VERSION ""

NS_ :

BS_:

BU_: BDCF THU FP IP RRS PLG BDCR FIS EPS ARHUD ETC EMS EPBI LAS WLCM ESCL HU APA ACC LCDAL LCDAR BMT AMP SRS TCU ATB AWD ESL ACM ECM PCU BMS IBCU OTA

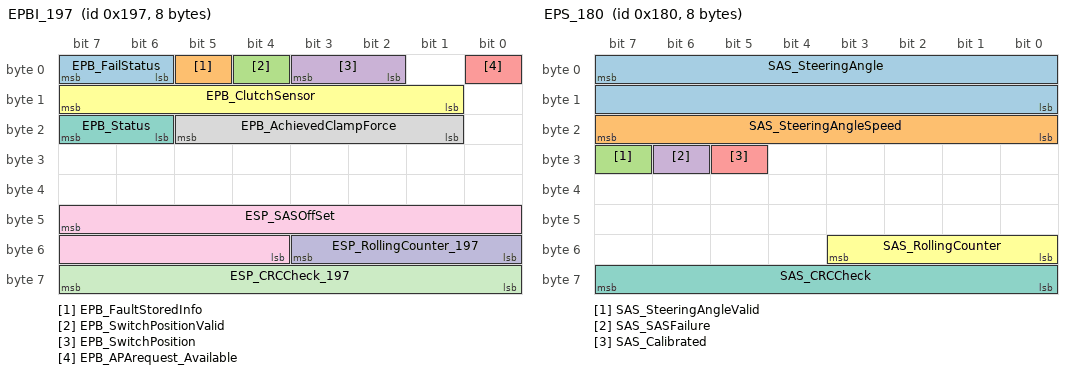
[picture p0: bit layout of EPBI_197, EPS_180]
BO_ 407 EPBI_197: 8 EPBI
SG_ EPB_FailStatus : 7|2@0+ (1,0) [0|3] "" BDCF
SG_ EPB_FaultStoredInfo : 5|1@0+ (1,0) [0|1] "" Vector__XXX
SG_ EPB_SwitchPositionValid : 4|1@0+ (1,0) [0|1] "" Vector__XXX
SG_ EPB_SwitchPosition : 3|2@0+ (1,0) [0|3] "" Vector__XXX
SG_ EPB_APArequest_Available : 0|1@0+ (1,0) [0|1] "" Vector__XXX
SG_ EPB_ClutchSensor : 15|7@0+ (1,0) [0|100] "%" Vector__XXX
SG_ EPB_Status : 23|2@0+ (1,0) [0|3] "" RRS
SG_ EPB_AchievedClampForce : 21|5@0+ (1,0) [0|31] "KN" Vector__XXX
SG_ ESP_SASOffSet : 47|12@0+ (0.1,-201) [-201|201] "degree" Vector__XXX
SG_ ESP_RollingCounter_197 : 51|4@0+ (1,0) [0|15] "" Vector__XXX
SG_ ESP_CRCCheck_197 : 63|8@0+ (1,0) [0|255] "" Vector__XXX

BO_ 391 EPBI_187: 8 EPBI
SG_ ESP_ABSActiveStatus : 7|1@0+ (1,0) [0|1] "" BDCF
SG_ ESP_GearHoldRequest : 6|1@0+ (1,0) [0|1] "" Vector__XXX
SG_ ESP_GearHoldRequestValid : 5|1@0+ (1,0) [0|1] "" Vector__XXX
SG_ ESP_TCSFailStatus : 4|1@0+ (1,0) [0|1] "" THU,IP
SG_ ESP_ABSFailStatus : 3|1@0+ (1,0) [0|1] "" THU,IP
SG_ ESP_EBDFailStatus : 2|1@0+ (1,0) [0|1] "" THU,IP
SG_ ESP_ESPFunctionStatus : 1|1@0+ (1,0) [0|1] "" THU,IP
SG_ ESP_ESPActiveStatus : 0|1@0+ (1,0) [0|1] "" THU,IP
SG_ ESP_EngTorqDecFast : 15|8@0+ (0.392,0) [0|99.568] "%" Vector__XXX
SG_ ESP_EngTorqDecSlow : 23|8@0+ (0.392,0) [0|99.568] "%" Vector__XXX
SG_ ESP_EngTorqInc : 31|8@0+ (0.392,0) [0|99.568] "%" Vector__XXX
SG_ ESP_EngTorqDecActive : 39|1@0+ (1,0) [0|1] "" Vector__XXX
SG_ ESP_EngTorqIncActive : 38|1@0+ (1,0) [0|1] "" Vector__XXX
SG_ ESP_VehicleSpeedValid : 37|1@0+ (1,0) [0|1] "" THU,IP,FIS,ESCL,RRS,PLG,BDCR
SG_ ESP_VehicleSpeed : 36|13@0+ (0.05625,0) [0|360] "km/h" THU,IP,FIS,ESCL,RRS,PLG,BDCR
SG_ ESP_ADBF_Active : 52|1@0+ (1,0) [0|1] "" Vector__XXX
SG_ ESP_RollingCounter_187 : 51|4@0+ (1,0) [0|15] "" Vector__XXX
SG_ ESP_CRCCheck_187 : 63|8@0+ (1,0) [0|255] "" Vector__XXX

BO_ 384 EPS_180: 8 EPS
SG_ SAS_SteeringAngle : 7|16@0+ (0.1,0) [-780|780] "degree" BDCF,THU,IP,FIS
SG_ SAS_SteeringAngleSpeed : 23|8@0+ (4,0) [0|1016] "deg/s" THU
SG_ SAS_SteeringAngleValid : 31|1@0+ (1,0) [0|1] "" THU,IP,FIS
SG_ SAS_SASFailure : 30|1@0+ (1,0) [0|1] "" Vector__XXX
SG_ SAS_Calibrated : 29|1@0+ (1,0) [0|1] "" Vector__XXX
SG_ SAS_RollingCounter : 51|4@0+ (1,0) [0|15] "" FIS
SG_ SAS_CRCCheck : 63|8@0+ (1,0) [0|255] "" FIS

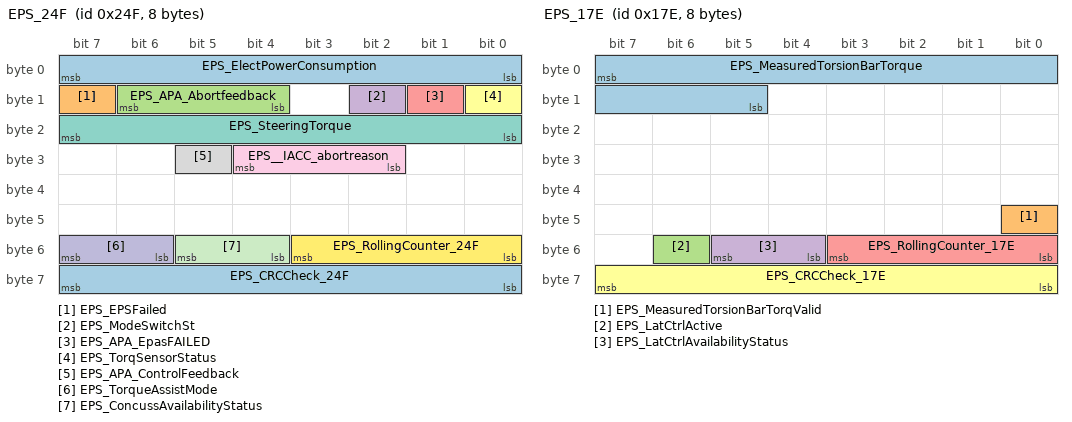
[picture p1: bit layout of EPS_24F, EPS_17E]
BO_ 591 EPS_24F: 8 EPS
 SG_ EPS_ElectPowerConsumption : 7|8@0+ (0.5,0) [0|127] "A" BDCF
 SG_ EPS_EPSFailed : 15|1@0+ (1,0) [0|1] "" THU,IP
 SG_ EPS_APA_Abortfeedback : 14|3@0+ (1,0) [0|7] "" Vector__XXX
 SG_ EPS_ModeSwitchSt : 10|1@0+ (1,0) [0|1] "" Vector__XXX
 SG_ EPS_APA_EpasFAILED : 9|1@0+ (1,0) [0|1] "" Vector__XXX
 SG_ EPS_TorqSensorStatus : 8|1@0+ (1,0) [0|1] "" Vector__XXX
 SG_ EPS_SteeringTorque : 23|8@0+ (0.1794,-22.78) [-22.78|22.78] "Nm" Vector__XXX
 SG_ EPS_APA_ControlFeedback : 29|1@0+ (1,0) [0|1] "" Vector__XXX
 SG_ EPS__IACC_abortreason : 28|3@0+ (1,0) [0|7] "" Vector__XXX
 SG_ EPS_TorqueAssistMode : 55|2@0+ (1,0) [0|3] "" THU,HU
 SG_ EPS_ConcussAvailabilityStatus : 53|2@0+ (1,0) [0|3] "" Vector__XXX
 SG_ EPS_RollingCounter_24F : 51|4@0+ (1,0) [0|15] "" Vector__XXX
 SG_ EPS_CRCCheck_24F : 63|8@0+ (1,0) [0|255] "" Vector__XXX

BO_ 382 EPS_17E: 8 EPS
 SG_ EPS_MeasuredTorsionBarTorque : 7|11@0+ (0.01,-10.23) [-10.23|10.23] "Nm" BDCF,THU
 SG_ EPS_MeasuredTorsionBarTorqValid : 40|1@0+ (1,0) [0|1] "" THU
 SG_ EPS_LatCtrlActive : 54|1@0+ (1,0) [0|1] "" Vector__XXX
 SG_ EPS_LatCtrlAvailabilityStatus : 53|2@0+ (1,0) [0|3] "" Vector__XXX
 SG_ EPS_RollingCounter_17E : 51|4@0+ (1,0) [0|15] "" Vector__XXX
 SG_ EPS_CRCCheck_17E : 63|8@0+ (1,0) [0|255] "" Vector__XXX

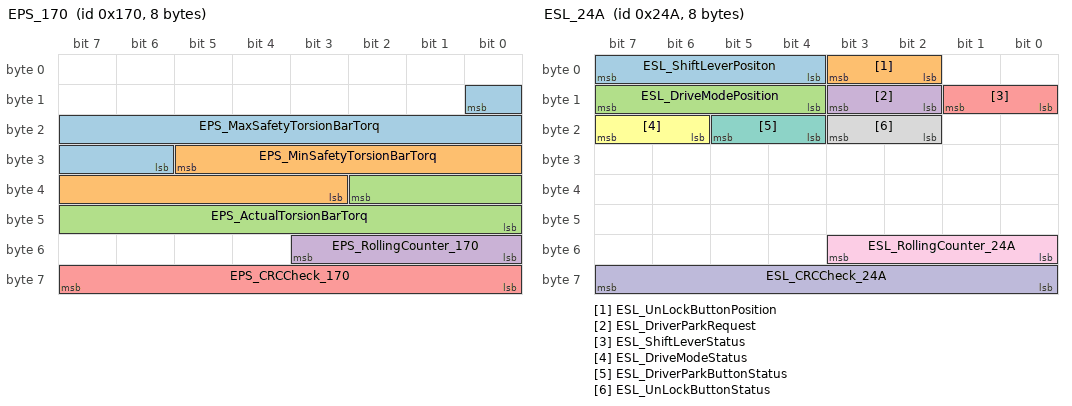
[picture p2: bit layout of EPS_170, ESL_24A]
BO_ 368 EPS_170: 8 EPS
 SG_ EPS_MaxSafetyTorsionBarTorq : 8|11@0+ (0.02,-20.48) [-20.48|20.46] "Nm" BDCF
 SG_ EPS_MinSafetyTorsionBarTorq : 29|11@0+ (0.02,-20.48) [-20.48|20.46] "Nm" Vector__XXX
 SG_ EPS_ActualTorsionBarTorq : 34|11@0+ (0.02,-20.48) [-20.48|20.46] "Nm" Vector__XXX
 SG_ EPS_RollingCounter_170 : 51|4@0+ (1,0) [0|15] "" Vector__XXX
 SG_ EPS_CRCCheck_170 : 63|8@0+ (1,0) [0|255] "" Vector__XXX

BO_ 586 ESL_24A: 8 ESL
 SG_ ESL_ShiftLeverPositon : 7|4@0+ (1,0) [0|15] "" BDCF
 SG_ ESL_UnLockButtonPosition : 3|2@0+ (1,0) [0|3] "" Vector__XXX
 SG_ ESL_DriveModePosition : 15|4@0+ (1,0) [0|15] "" Vector__XXX
 SG_ ESL_DriverParkRequest : 11|2@0+ (1,0) [0|3] "" Vector__XXX
 SG_ ESL_ShiftLeverStatus : 9|2@0+ (1,0) [0|3] "" Vector__XXX
 SG_ ESL_DriveModeStatus : 23|2@0+ (1,0) [0|3] "" Vector__XXX
 SG_ ESL_DriverParkButtonStatus : 21|2@0+ (1,0) [0|3] "" Vector__XXX
 SG_ ESL_UnLockButtonStatus : 19|2@0+ (1,0) [0|3] "" Vector__XXX
 SG_ ESL_RollingCounter_24A : 51|4@0+ (1,0) [0|15] "" Vector__XXX
 SG_ ESL_CRCCheck_24A : 63|8@0+ (1,0) [0|255] "" Vector__XXX

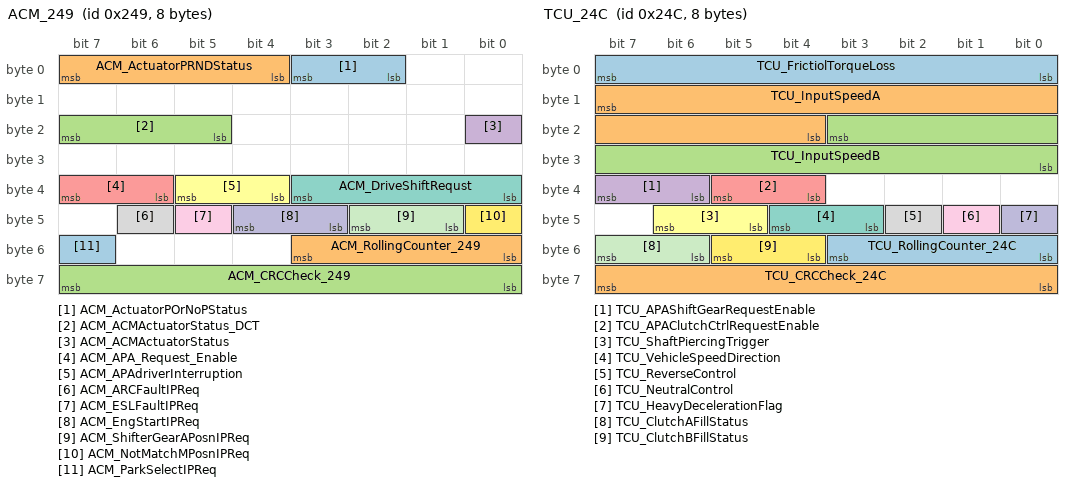
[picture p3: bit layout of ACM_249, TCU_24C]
BO_ 585 ACM_249: 8 ACM
 SG_ ACM_ActuatorPOrNoPStatus : 3|2@0+ (1,0) [0|3] "" BDCF
 SG_ ACM_ActuatorPRNDStatus : 7|4@0+ (1,0) [0|15] "" Vector__XXX
 SG_ ACM_ACMActuatorStatus_DCT : 23|3@0+ (1,0) [0|7] "" Vector__XXX
 SG_ ACM_ACMActuatorStatus : 16|1@0+ (1,0) [0|1] "" Vector__XXX
 SG_ ACM_APA_Request_Enable : 39|2@0+ (1,0) [0|3] "" Vector__XXX
 SG_ ACM_APAdriverInterruption : 37|2@0+ (1,0) [0|3] "" Vector__XXX
 SG_ ACM_DriveShiftRequst : 35|4@0+ (1,0) [0|15] "" Vector__XXX
 SG_ ACM_ARCFaultIPReq : 46|1@0+ (1,0) [0|1] "" Vector__XXX
 SG_ ACM_ESLFaultIPReq : 45|1@0+ (1,0) [0|1] "" Vector__XXX
 SG_ ACM_EngStartIPReq : 44|2@0+ (1,0) [0|3] "" Vector__XXX
 SG_ ACM_ShifterGearAPosnIPReq : 42|2@0+ (1,0) [0|3] "" Vector__XXX
 SG_ ACM_NotMatchMPosnIPReq : 40|1@0+ (1,0) [0|1] "" Vector__XXX
 SG_ ACM_ParkSelectIPReq : 55|1@0+ (1,0) [0|1] "" Vector__XXX
 SG_ ACM_RollingCounter_249 : 51|4@0+ (1,0) [0|15] "" Vector__XXX
 SG_ ACM_CRCCheck_249 : 63|8@0+ (1,0) [0|255] "" Vector__XXX

BO_ 509 ECM_1FD: 8 ECM
 SG_ TCU_CrankingAuthEnable : 5|2@0+ (1,0) [0|3] "" BDCF

BO_ 824 TCU_338: 8 TCU
 SG_ TCU_CompressorDisableReq : 7|1@0+ (1,0) [0|1] "" BDCF
 SG_ TCU_FailureLamp : 6|1@0+ (1,0) [0|1] "" THU,IP
 SG_ TCU_ReqTranTempWarning : 5|2@0+ (1,0) [0|3] "" THU,IP
 SG_ TCU_BrakeAssistRequest : 3|1@0+ (1,0) [0|1] "" Vector__XXX
 SG_ TCU_BrakeAssistRequestValid : 2|1@0+ (1,0) [0|1] "" Vector__XXX
 SG_ TCU_FanRequest : 1|2@0+ (1,0) [0|3] "" Vector__XXX
 SG_ TCU_ShiftMapID : 15|4@0+ (1,0) [0|15] "" Vector__XXX
 SG_ TCU_LinePressureFailureStatus : 11|1@0+ (1,0) [0|1] "" THU,IP
 SG_ TCU_ClearDiagnosticInfo : 9|2@0+ (1,0) [0|3] "" Vector__XXX
 SG_ TCU_TransFluidTemp : 23|8@0+ (1,-40) [-40|214] "degreeC" Vector__XXX
 SG_ TCU_SlopeRatio : 31|8@0+ (0.2,-25) [-25|25] "%" THU
 SG_ TCU_GearForDisplay : 39|4@0+ (1,0) [0|15] "" THU,IP,RRS
 SG_ TCU_GearIndication : 35|1@0+ (1,0) [0|1] "" Vector__XXX
 SG_ TCU_BuzzerReq : 34|3@0+ (1,0) [0|7] "" Vector__XXX
 SG_ TCU_EngStartIPReq : 47|2@0+ (1,0) [0|3] "" IP
 SG_ TCU_ParkRelAPosnIPReq : 45|2@0+ (1,0) [0|3] "" IP
 SG_ TCU_ParkRelMPosnIPReq : 43|1@0+ (1,0) [0|1] "" IP
 SG_ TCU_ParkSelectIPReq : 42|1@0+ (1,0) [0|1] "" IP
 SG_ TCU_ESLFaultIPReq : 41|1@0+ (1,0) [0|1] "" IP
 SG_ TCU_ARCFaultIPReq : 40|1@0+ (1,0) [0|1] "" IP
 SG_ TCU_DriveMode : 55|4@0+ (1,0) [0|15] "" Vector__XXX
 SG_ TCU_RollingCounter_338 : 51|4@0+ (1,0) [0|15] "" Vector__XXX
 SG_ TCU_CRCCheck_338 : 63|8@0+ (1,0) [0|255] "" Vector__XXX

BO_ 588 TCU_24C: 8 TCU
 SG_ TCU_FrictiolTorqueLoss : 7|8@0+ (0.1,0) [0|25] "%" BDCF
 SG_ TCU_InputSpeedA : 15|12@0+ (2.5,0) [0|10235] "rpm" Vector__XXX
 SG_ TCU_InputSpeedB : 19|12@0+ (2.5,0) [0|10235] "rpm" Vector__XXX
 SG_ TCU_APAShiftGearRequestEnable : 39|2@0+ (1,0) [0|3] "" Vector__XXX
 SG_ TCU_APAClutchCtrlRequestEnable : 37|2@0+ (1,0) [0|3] "" Vector__XXX
 SG_ TCU_ShaftPiercingTrigger : 46|2@0+ (1,0) [0|3] "" Vector__XXX
 SG_ TCU_VehicleSpeedDirection : 44|2@0+ (1,0) [0|3] "" Vector__XXX
 SG_ TCU_ReverseControl : 42|1@0+ (1,0) [0|1] "" RRS
 SG_ TCU_NeutralControl : 41|1@0+ (1,0) [0|1] "" Vector__XXX
 SG_ TCU_HeavyDecelerationFlag : 40|1@0+ (1,0) [0|1] "" Vector__XXX
 SG_ TCU_ClutchAFillStatus : 55|2@0+ (1,0) [0|3] "" Vector__XXX
 SG_ TCU_ClutchBFillStatus : 53|2@0+ (1,0) [0|3] "" Vector__XXX
 SG_ TCU_RollingCounter_24C : 51|4@0+ (1,0) [0|15] "" Vector__XXX
 SG_ TCU_CRCCheck_24C : 63|8@0+ (1,0) [0|255] "" Vector__XXX

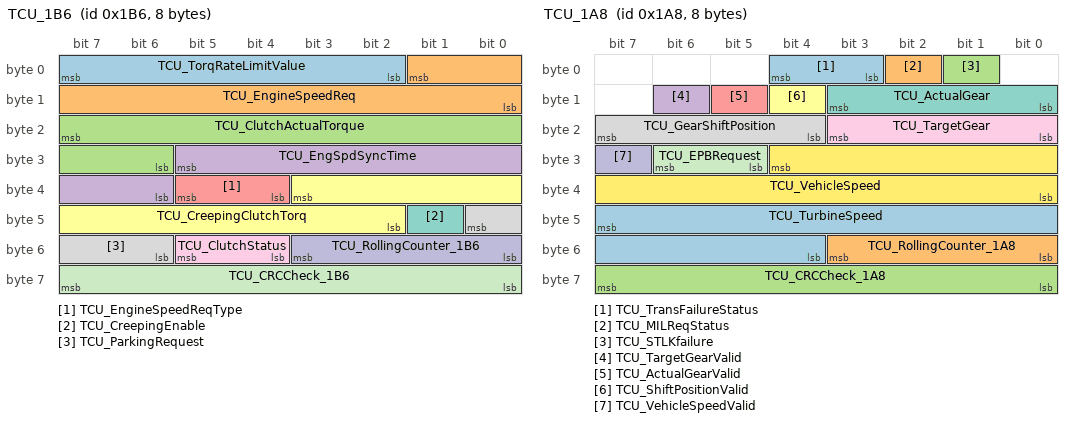
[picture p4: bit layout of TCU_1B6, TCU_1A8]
BO_ 438 TCU_1B6: 8 TCU
 SG_ TCU_TorqRateLimitValue : 7|6@0+ (10,0) [0|630] "Nm/s" BDCF
 SG_ TCU_EngineSpeedReq : 1|10@0+ (10,0) [0|10200] "Rpm" Vector__XXX
 SG_ TCU_ClutchActualTorque : 23|10@0+ (0.1,0) [0|100] "%" Vector__XXX
 SG_ TCU_EngSpdSyncTime : 29|8@0+ (10,0) [0|2550] "ms" Vector__XXX
 SG_ TCU_EngineSpeedReqType : 37|2@0+ (1,0) [0|3] "" Vector__XXX
 SG_ TCU_CreepingClutchTorq : 35|10@0+ (0.1,0) [0|100] "%" Vector__XXX
 SG_ TCU_CreepingEnable : 41|1@0+ (1,0) [0|1] "" Vector__XXX
 SG_ TCU_ParkingRequest : 40|3@0+ (1,0) [0|7] "" Vector__XXX
 SG_ TCU_ClutchStatus : 53|2@0+ (1,0) [0|3] "" Vector__XXX
 SG_ TCU_RollingCounter_1B6 : 51|4@0+ (1,0) [0|15] "" Vector__XXX
 SG_ TCU_CRCCheck_1B6 : 63|8@0+ (1,0) [0|255] "" Vector__XXX

BO_ 424 TCU_1A8: 8 TCU
SG_ TCU_TransFailureStatus : 4|2@0+ (1,0) [0|3] "" BDCF,THU,IP
SG_ TCU_MILReqStatus : 2|1@0+ (1,0) [0|1] "" Vector__XXX
SG_ TCU_STLKfailure : 1|1@0+ (1,0) [0|1] "" Vector__XXX
SG_ TCU_TargetGearValid : 14|1@0+ (1,0) [0|1] "" THU,IP
SG_ TCU_ActualGearValid : 13|1@0+ (1,0) [0|1] "" THU,IP
SG_ TCU_ShiftPositionValid : 12|1@0+ (1,0) [0|1] "" THU,IP,FIS,PLG
SG_ TCU_ActualGear : 11|4@0+ (1,0) [0|15] "" THU,IP,FIS
SG_ TCU_GearShiftPosition : 23|4@0+ (1,0) [0|15] "" THU,IP,FIS,PLG,BDCR
SG_ TCU_TargetGear : 19|4@0+ (1,0) [0|15] "" THU,IP
SG_ TCU_VehicleSpeedValid : 31|1@0+ (1,0) [0|1] "" Vector__XXX
SG_ TCU_EPBRequest : 30|2@0+ (1,0) [0|3] "" Vector__XXX
SG_ TCU_VehicleSpeed : 28|13@0+ (0.05625,0) [0|360] "km/h" Vector__XXX
SG_ TCU_TurbineSpeed : 47|12@0+ (2,0) [0|8190] "rpm" Vector__XXX
SG_ TCU_RollingCounter_1A8 : 51|4@0+ (1,0) [0|15] "" THU,IP
SG_ TCU_CRCCheck_1A8 : 63|8@0+ (1,0) [0|255] "" THU,IP

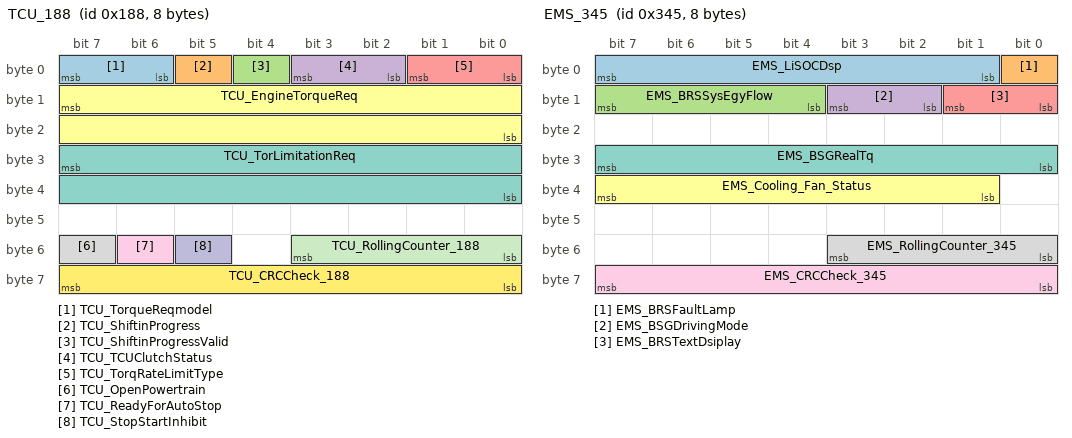
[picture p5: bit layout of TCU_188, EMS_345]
BO_ 392 TCU_188: 8 TCU
 SG_ TCU_TorqueReqmodel : 7|2@0+ (1,0) [0|3] "" BDCF
 SG_ TCU_ShiftinProgress : 5|1@0+ (1,0) [0|1] "" Vector__XXX
 SG_ TCU_ShiftinProgressValid : 4|1@0+ (1,0) [0|1] "" Vector__XXX
 SG_ TCU_TCUClutchStatus : 3|2@0+ (1,0) [0|3] "" Vector__XXX
 SG_ TCU_TorqRateLimitType : 1|2@0+ (1,0) [0|3] "" Vector__XXX
 SG_ TCU_EngineTorqueReq : 15|16@0+ (0.001526,0) [0|99.99878] "%" Vector__XXX
 SG_ TCU_TorLimitationReq : 31|16@0+ (0.001526,0) [0|99.99878] "%" Vector__XXX
 SG_ TCU_OpenPowertrain : 55|1@0+ (1,0) [0|1] "" Vector__XXX
 SG_ TCU_ReadyForAutoStop : 54|1@0+ (1,0) [0|1] "" Vector__XXX
 SG_ TCU_StopStartInhibit : 53|1@0+ (1,0) [0|1] "" Vector__XXX
 SG_ TCU_RollingCounter_188 : 51|4@0+ (1,0) [0|15] "" Vector__XXX
 SG_ TCU_CRCCheck_188 : 63|8@0+ (1,0) [0|255] "" Vector__XXX

BO_ 853 EMS_355: 8 EMS
SG_ EMS_CruiseActiveIndicate : 0|1@0+ (1,0) [0|1] "" BDCF,THU,IP
SG_ EMS_SSMWarningLampCtrol : 1|1@0+ (1,0) [0|1] "" THU,IP
SG_ EMS_CruiseUnavailDisplay : 2|1@0+ (1,0) [0|1] "" THU,IP
SG_ EMS_IdleStopStatus : 3|1@0+ (1,0) [0|1] "" THU,IP
SG_ EMS_CruiseIndicate : 4|1@0+ (1,0) [0|1] "" THU,IP
SG_ EMS_MIL : 6|2@0+ (1,0) [0|3] "" THU,IP
SG_ EMS_SVS : 7|1@0+ (1,0) [0|1] "" Vector__XXX
SG_ EMS_StartPrompt : 9|2@0+ (1,0) [0|3] "" THU,IP
SG_ EMS_CruiseDistance : 10|1@0+ (1,0) [0|1] "" THU,IP
SG_ EMS_CruiseSwitchSET : 11|1@0+ (1,0) [0|1] "" THU,IP
SG_ EMS_CruiseSwitchCANCEL : 12|1@0+ (1,0) [0|1] "" THU,IP
SG_ EMS_CruiseSwitchResume : 13|1@0+ (1,0) [0|1] "" THU,IP
SG_ EMS_CruiseSwitchOnOff : 14|1@0+ (1,0) [0|1] "" THU,IP
SG_ EMS_PFCCCondition : 15|1@0+ (1,0) [0|1] "" Vector__XXX
SG_ EMS_TankDoorSts : 16|1@0+ (1,0) [0|1] "" THU,IP
SG_ EMS_GPF_State : 19|3@0+ (1,0) [0|7] "" THU,IP
SG_ EMS_RemindShiftGear : 21|2@0+ (1,0) [0|3] "" THU,IP
SG_ EMS_ClearDiagnosticInfo : 23|2@0+ (1,0) [0|3] "" Vector__XXX
 SG_ EMS_AgsPosition : 26|2@0+ (1,0) [0|3] "" IP
SG_ EMS_AgsErrorStateDisplay : 27|1@0+ (1,0) [0|1] "" IP
SG_ EMS_CruiseControlStatus_355 : 29|2@0+ (1,0) [0|3] "" THU,IP
SG_ EMS_DriveMode : 31|2@0+ (1,0) [0|3] "" Vector__XXX
SG_ EMS_FuelConsumption : 39|8@0+ (0.015,0) [0|3.81] "ml" THU,IP
SG_ EMS_TargetCruiseSpeed : 47|8@0+ (1,0) [0|254] "Km/h" THU,IP
SG_ EMS_RollingCounter_355 : 51|4@0+ (1,0) [0|15] "" Vector__XXX
SG_ EMS_EngineType : 55|4@0+ (1,0) [0|15] "" Vector__XXX
SG_ EMS_CRCCheck_355 : 63|8@0+ (1,0) [0|255] "" Vector__XXX

BO_ 837 EMS_345: 8 EMS
SG_ EMS_LiSOCDsp : 7|7@0+ (1,0) [0|100] "%" BDCF
SG_ EMS_BRSFaultLamp : 0|1@0+ (1,0) [0|1] "" Vector__XXX
SG_ EMS_BRSSysEgyFlow : 15|4@0+ (1,0) [0|15] "" Vector__XXX
SG_ EMS_BSGDrivingMode : 11|2@0+ (1,0) [0|3] "" Vector__XXX
SG_ EMS_BRSTextDsiplay : 9|2@0+ (1,0) [0|3] "" Vector__XXX
SG_ EMS_Cooling_Fan_Status : 39|7@0+ (1,0) [0|111] "%" Vector__XXX
SG_ EMS_BSGRealTq : 31|8@0+ (0.5,-63) [-63|63] "" Vector__XXX
SG_ EMS_RollingCounter_345 : 51|4@0+ (1,0) [0|15] "" Vector__XXX
SG_ EMS_CRCCheck_345 : 63|8@0+ (1,0) [0|255] "" Vector__XXX

BO_ 776 EMS_308: 8 EMS
SG_ EMS_FuelCapLeakDisplay : 7|1@0+ (1,0) [0|1] "" THU,IP
SG_ EMS_OilPressureSts : 6|1@0+ (1,0) [0|1] "" THU,IP
SG_ EMS_ChrageLightState : 5|1@0+ (1,0) [0|1] "" THU,IP
SG_ EMS_EEMErrorFlag : 4|1@0+ (1,0) [0|1] "" Vector__XXX
SG_ EMS_EEM_state : 3|3@0+ (1,0) [0|7] "" Vector__XXX
SG_ EMS_IntakeAirTempSensorError : 0|1@0+ (1,0) [0|1] "" THU,HU
SG_ EMS_RemindGear : 15|3@0+ (1,0) [0|7] "" THU,IP
SG_ EMS_STTUnavailDisplay : 12|3@0+ (1,0) [0|7] "" IP
SG_ EMS_Neutralgear : 9|2@0+ (1,0) [0|1] "" Vector__XXX
SG_ EMS_EngineIntakeAirTemp : 23|8@0+ (0.75,-40) [-40|150.5] "degree_C" Vector__XXX
SG_ EMS_ASLTargetSpeed : 31|8@0+ (1,0) [0|255] "km/h" Vector__XXX
SG_ EMS_ExhaustValStatus : 34|2@0+ (1,0) [0|3] "" BDCF,THU
SG_ EMS_ASLFaultsWarning : 55|1@0+ (1,0) [0|1] "" Vector__XXX
SG_ EMS_ASLExceedTarSpdIndi : 54|1@0+ (1,0) [0|1] "" Vector__XXX
SG_ EMS_ASLControlStatus : 53|2@0+ (1,0) [0|3] "" Vector__XXX
SG_ EMS_RollingCounter_308 : 51|4@0+ (1,0) [0|15] "" Vector__XXX
SG_ EMS_CRCCheck_308 : 63|8@0+ (1,0) [0|255] "" Vector__XXX

BO_ 726 EMS_2D6: 8 EMS
SG_ EMS_CatalystWarmUp : 7|1@0+ (1,0) [0|1] "" BDCF
SG_ EMS_WarmUpCycle : 6|1@0+ (1,0) [0|1] "" Vector__XXX
SG_ EMS_DrivingCycle : 5|1@0+ (1,0) [0|1] "" Vector__XXX
SG_ EMS_EngineLimpHome : 4|1@0+ (1,0) [0|1] "" Vector__XXX
SG_ EMS_ImmoFeedback : 3|2@0+ (1,0) [0|3] "" Vector__XXX
SG_ EMS_ImmoConfiguration : 1|1@0+ (1,0) [0|1] "" Vector__XXX
SG_ EMS_CoolanTemperatureError : 15|1@0+ (1,0) [0|1] "" THU,IP
SG_ EMS_BatteryVoltageError : 14|1@0+ (1,0) [0|1] "" Vector__XXX
SG_ EMS_General_Denominator_Status : 12|1@0+ (1,0) [0|1] "" Vector__XXX
SG_ EMS_GeneralDenomStasVD : 11|1@0+ (1,0) [0|1] "" Vector__XXX
SG_ EMS_Ignition_Cycles_Counter : 10|1@0+ (1,0) [0|1] "" Vector__XXX
SG_ EMS_EngineStartupEnd : 9|1@0+ (1,0) [0|1] "" Vector__XXX
SG_ EMS_EngineCoolanTemperature : 23|8@0+ (0.75,-48) [-48|142.5] "degreeC" THU,IP
SG_ EMS_BatteryVoltage : 31|8@0+ (0.1,0) [0|25.4] "V" Vector__XXX
SG_ EMS_IdleReferenceSpeed : 39|8@0+ (10,0) [0|2540] "rpm" Vector__XXX
SG_ EMS_AltitudeFactor : 47|8@0+ (0.01575,0) [0|4] "" Vector__XXX
SG_ EMS_RollingCounter_2D6 : 51|4@0+ (1,0) [0|15] "" Vector__XXX
SG_ EMS_CRCCheck_2D6 : 63|8@0+ (1,0) [0|255] "" Vector__XXX

BO_ 618 EMS_26A: 8 EMS
SG_ EMS_EVPActive : 5|1@0+ (1,0) [0|1] "" BDCF
SG_ EMS_confirmation_in_sport_mode : 4|1@0+ (1,0) [0|1] "" Vector__XXX
SG_ EMS_AccReqPossible : 3|1@0+ (1,0) [0|1] "" Vector__XXX
SG_ EMS_QECACC : 2|2@0+ (1,0) [0|3] "" Vector__XXX
SG_ EMS_ECGPOvrd : 0|1@0+ (1,0) [0|1] "" Vector__XXX
SG_ EMS_APAAccPedShieldStatus : 24|1@0+ (1,0) [0|1] "" Vector__XXX
SG_ EMS_DriveModeSts : 28|4@0+ (1,0) [0|15] "" IP
SG_ EMS_EngTorqQualityFlag : 39|2@0+ (1,0) [0|3] "" Vector__XXX
SG_ EMS_CompressorWoE : 37|1@0+ (1,0) [0|1] "" Vector__XXX
SG_ EMS_KickDown : 36|1@0+ (1,0) [0|1] "" Vector__XXX
SG_ EMS_CompressorStatus : 35|1@0+ (1,0) [0|1] "" Vector__XXX
SG_ EMS_EngineStatusWithSTT : 34|3@0+ (1,0) [0|7] "" THU,IP
SG_ EMS_VacuumPressure : 47|10@0+ (1.1056,-1080) [-1080|50] "mbar" Vector__XXX
SG_ EMS_ConditionIdle : 53|1@0+ (1,0) [0|1] "" Vector__XXX
SG_ EMS_VacuumPressureValid : 52|1@0+ (1,0) [0|1] "" Vector__XXX
SG_ EMS_RollingCounter_26A : 51|4@0+ (1,0) [0|15] "" IP
SG_ EMS_CRCCheck_26A : 63|8@0+ (1,0) [0|255] "" IP

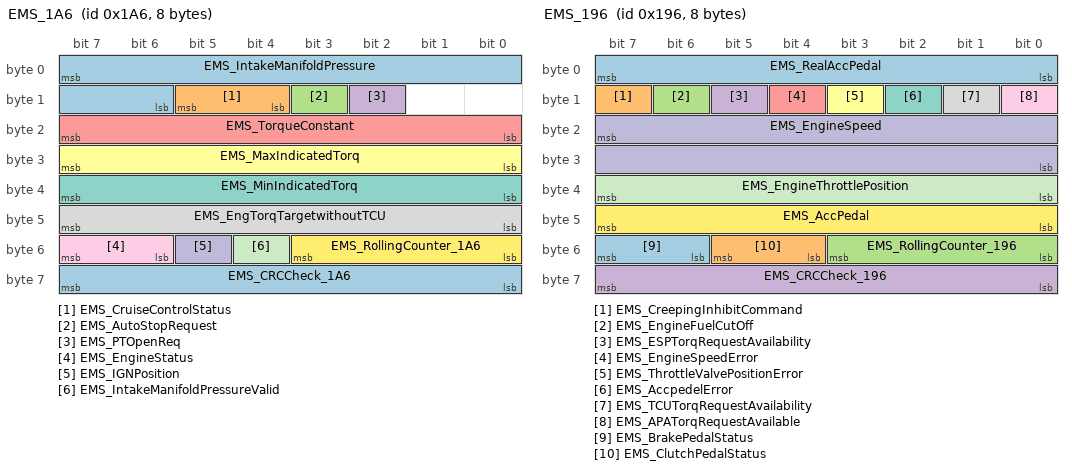
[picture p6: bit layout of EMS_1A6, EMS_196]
BO_ 422 EMS_1A6: 8 EMS
SG_ EMS_IntakeManifoldPressure : 7|10@0+ (4,100) [100|4188] "mbar" BDCF,THU
SG_ EMS_CruiseControlStatus : 13|2@0+ (1,0) [0|3] "" THU,IP
SG_ EMS_AutoStopRequest : 11|1@0+ (1,0) [0|1] "" Vector__XXX
SG_ EMS_PTOpenReq : 10|1@0+ (1,0) [0|1] "" Vector__XXX
SG_ EMS_TorqueConstant : 23|8@0+ (10,0) [0|2540] "NM" Vector__XXX
SG_ EMS_MaxIndicatedTorq : 31|8@0+ (0.392,0) [0|99.568] "%" Vector__XXX
SG_ EMS_MinIndicatedTorq : 39|8@0+ (0.392,0) [0|99.568] "%" Vector__XXX
SG_ EMS_EngTorqTargetwithoutTCU : 47|8@0+ (0.392,0) [0|99.568] "%" Vector__XXX
SG_ EMS_EngineStatus : 55|2@0+ (1,0) [0|3] "" THU,IP,FIS
SG_ EMS_IGNPosition : 53|1@0+ (1,0) [0|1] "" Vector__XXX
SG_ EMS_IntakeManifoldPressureValid : 52|1@0+ (1,0) [0|1] "" THU
SG_ EMS_RollingCounter_1A6 : 51|4@0+ (1,0) [0|15] "" Vector__XXX
SG_ EMS_CRCCheck_1A6 : 63|8@0+ (1,0) [0|255] "" Vector__XXX

BO_ 406 EMS_196: 8 EMS
SG_ EMS_RealAccPedal : 7|8@0+ (0.392,0) [0|99.568] "%" BDCF,THU
SG_ EMS_CreepingInhibitCommand : 15|1@0+ (1,0) [0|1] "" Vector__XXX
SG_ EMS_EngineFuelCutOff : 14|1@0+ (1,0) [0|1] "" IP
SG_ EMS_ESPTorqRequestAvailability : 13|1@0+ (1,0) [0|1] "" Vector__XXX
SG_ EMS_EngineSpeedError : 12|1@0+ (1,0) [0|1] "" THU,IP,FIS
SG_ EMS_ThrottleValvePositionError : 11|1@0+ (1,0) [0|1] "" THU,HU
SG_ EMS_AccpedelError : 10|1@0+ (1,0) [0|1] "" THU,HU
SG_ EMS_TCUTorqRequestAvailability : 9|1@0+ (1,0) [0|1] "" Vector__XXX
SG_ EMS_APATorqRequestAvailable : 8|1@0+ (1,0) [0|1] "" Vector__XXX
SG_ EMS_EngineSpeed : 23|16@0+ (0.25,0) [0|16383.5] "Rpm" THU,IP,FIS
SG_ EMS_EngineThrottlePosition : 39|8@0+ (0.392,0) [0|99.568] "%" Vector__XXX
SG_ EMS_AccPedal : 47|8@0+ (0.392,0) [0|99.568] "%" THU
SG_ EMS_BrakePedalStatus : 55|2@0+ (1,0) [0|3] "" THU,IP
SG_ EMS_ClutchPedalStatus : 53|2@0+ (1,0) [0|3] "" Vector__XXX
SG_ EMS_RollingCounter_196 : 51|4@0+ (1,0) [0|15] "" FIS
SG_ EMS_CRCCheck_196 : 63|8@0+ (1,0) [0|255] "" FIS

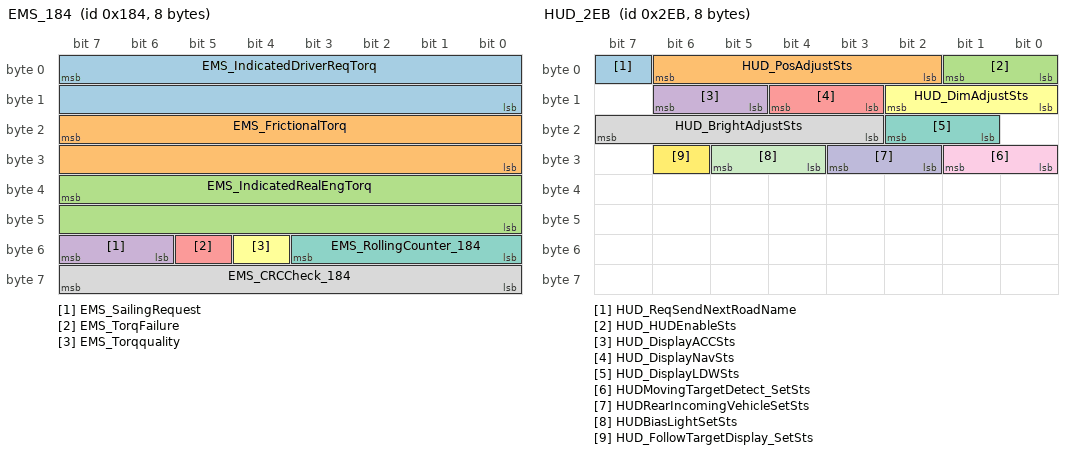
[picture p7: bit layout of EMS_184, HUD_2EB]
BO_ 388 EMS_184: 8 EMS
 SG_ EMS_IndicatedDriverReqTorq : 7|16@0+ (0.001526,0) [0|99.99878] "%" BDCF,THU,IP
 SG_ EMS_FrictionalTorq : 23|16@0+ (0.001526,0) [0|99.99878] "%" THU,IP
 SG_ EMS_IndicatedRealEngTorq : 39|16@0+ (0.001526,0) [0|99.99878] "%" Vector__XXX
 SG_ EMS_SailingRequest : 55|2@0+ (1,0) [0|3] "" Vector__XXX
 SG_ EMS_TorqFailure : 53|1@0+ (1,0) [0|1] "" Vector__XXX
 SG_ EMS_Torqquality : 52|1@0+ (1,0) [0|1] "" Vector__XXX
 SG_ EMS_RollingCounter_184 : 51|4@0+ (1,0) [0|15] "" Vector__XXX
 SG_ EMS_CRCCheck_184 : 63|8@0+ (1,0) [0|255] "" Vector__XXX

BO_ 747 HUD_2EB: 8 BDCF
 SG_ HUD_ReqSendNextRoadName : 7|1@0+ (1,0) [0|1] "" THU
 SG_ HUD_PosAdjustSts : 6|5@0+ (1,0) [0|31] "" THU
 SG_ HUD_HUDEnableSts : 1|2@0+ (1,0) [0|3] "" THU,IP
 SG_ HUD_DisplayACCSts : 14|2@0+ (1,0) [0|3] "" THU
 SG_ HUD_DisplayNavSts : 12|2@0+ (1,0) [0|3] "" THU
 SG_ HUD_DimAdjustSts : 10|3@0+ (1,0) [0|7] "" THU
 SG_ HUD_DisplayLDWSts : 18|2@0+ (1,0) [0|3] "" THU
 SG_ HUD_BrightAdjustSts : 23|5@0+ (1,0) [0|31] "" THU
 SG_ HUDMovingTargetDetect_SetSts : 25|2@0+ (1,0) [0|3] "" THU
 SG_ HUDRearIncomingVehicleSetSts : 27|2@0+ (1,0) [0|3] "" THU
 SG_ HUDBiasLightSetSts : 29|2@0+ (1,0) [0|3] "" THU
 SG_ HUD_FollowTargetDisplay_SetSts : 30|1@0+ (1,0) [0|1] "" THU

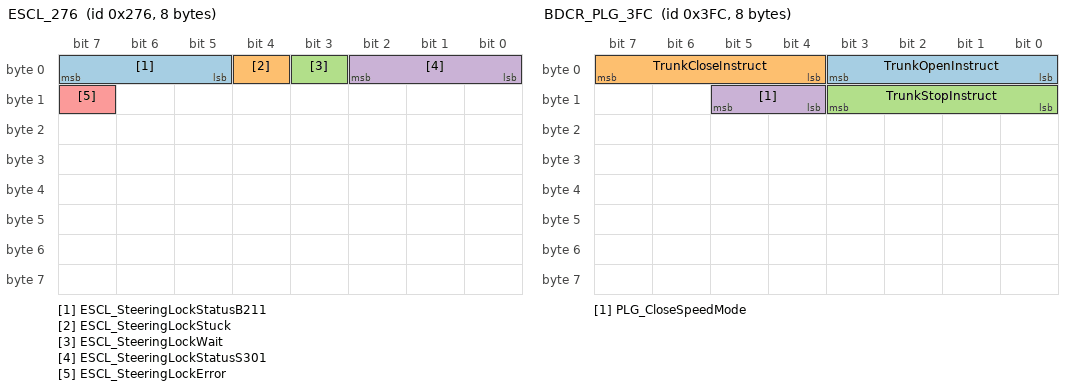
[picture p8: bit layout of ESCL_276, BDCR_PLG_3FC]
BO_ 630 ESCL_276: 8 ESCL
SG_ ESCL_SteeringLockStatusB211 : 7|3@0+ (1,0) [0|7] "" BDCF
SG_ ESCL_SteeringLockStuck : 4|1@0+ (1,0) [0|1] "" BDCF
SG_ ESCL_SteeringLockWait : 3|1@0+ (1,0) [0|1] "" BDCF
SG_ ESCL_SteeringLockStatusS301 : 2|3@0+ (1,0) [0|7] "" BDCF
SG_ ESCL_SteeringLockError : 15|1@0+ (1,0) [0|1] "" BDCF

BO_ 1020 BDCR_PLG_3FC: 8 BDCR
 SG_ TrunkOpenInstruct : 3|4@0+ (1,0) [0|15] ""  BDCF
 SG_ TrunkCloseInstruct : 7|4@0+ (1,0) [0|15] ""  BDCF
 SG_ TrunkStopInstruct : 11|4@0+ (1,0) [0|15] ""  BDCF
 SG_ PLG_CloseSpeedMode : 13|2@0+ (1,0) [0|3] ""  BDCF

BO_ 1022 BDCR_PLG_3FE: 8 BDCR
SG_ PLG_OpenHeightLearningStatus : 1|1@0+ (1,0) [0|1] "" BDCF
SG_ PLG_MovementStatus : 4|3@0+ (1,0) [0|7] "" BDCF,THU
SG_ PLG_LatchStatus : 7|3@0+ (1,0) [0|7] "" BDCF,THU
SG_ PLG_OpenHeightLearningResult : 0|1@0+ (1,0) [0|1] "" BDCF
SG_ PLG_GatePosition : 15|8@0+ (0.395,0) [0|100] "" BDCF,THU
SG_ PLG_InitializeStatus : 16|1@0+ (1,0) [0|1] "" BDCF,THU
SG_ PLG_InitializedResult : 17|1@0+ (1,0) [0|1] "" BDCF
SG_ PLG_ShutfaceSwitch : 18|1@0+ (1,0) [0|1] "" BDCF,THU
SG_ PLG_OpenCloseSwitch : 19|1@0+ (1,0) [0|1] "" BDCF,THU
SG_ PLG_PoleOverVoltage : 20|1@0+ (1,0) [0|1] "" BDCF
SG_ PLG_PoleUnderVoltage : 21|1@0+ (1,0) [0|1] "" BDCF
SG_ PLG_KickSensorStatus : 22|1@0+ (1,0) [0|1] "" BDCF
SG_ PLG_PawlSwitch : 23|1@0+ (1,0) [0|1] "" BDCF
SG_ PLG_PoleTimeoutStatus : 31|1@0+ (1,0) [0|1] "" BDCF
SG_ PLG_LockTimeoutStatus : 30|1@0+ (1,0) [0|1] "" BDCF
SG_ PLG_LockOverVoltage : 29|1@0+ (1,0) [0|1] "" BDCF
SG_ PLG_LockUnderVoltage : 28|1@0+ (1,0) [0|1] "" BDCF
SG_ PLG_ApsStatus : 27|1@0+ (1,0) [0|1] "" BDCF
SG_ PLG_PinchEventStatus : 26|1@0+ (1,0) [0|1] "" BDCF
SG_ PLG_ResetSwitch : 25|1@0+ (1,0) [0|1] "" BDCF
SG_ PLG_RatchetSwitch : 24|1@0+ (1,0) [0|1] "" BDCF
SG_ PLG_LatchMotorHeatProtectStatus : 39|1@0+ (1,0) [0|1] "" BDCF
SG_ PLG_LatchMotorStallStatus : 38|1@0+ (1,0) [0|1] "" BDCF
SG_ PLG_GateMotorHeatProtectStatus : 37|1@0+ (1,0) [0|1] "" BDCF
SG_ PLG_GateMotorStallStatus : 36|1@0+ (1,0) [0|1] "" BDCF
SG_ PLG_PinchPlayModeStatus : 35|1@0+ (1,0) [0|1] "" BDCF
SG_ PLG_InitializedFailReason : 34|3@0+ (1,0) [0|7] "" BDCF,THU
SG_ PLG_BuzzerStaus : 47|3@0+ (1,0) [0|3] "" BDCF,THU
SG_ PLG_OpenCloseSwitchError : 44|1@0+ (1,0) [0|1] "" BDCF
SG_ PLG_ShutfaceSwitchError : 43|1@0+ (1,0) [0|1] "" BDCF
SG_ PLG_PinchTriggerSignal : 42|1@0+ (1,0) [0|1] "" BDCF
SG_ PLG_Lock_RelayError : 41|1@0+ (1,0) [0|1] "" BDCF
SG_ PLG_Pole_HallError : 40|1@0+ (1,0) [0|1] "" BDCF
SG_ PLG_TrunkPositionFeedback : 55|8@0+ (0.395,0) [0|100] "" BDCF,THU
SG_ PLG_OpenHeightLearningFailReason : 58|3@0+ (1,0) [0|7] "" BDCF,THU
SG_ PLG_Pole_RelayError : 60|1@0+ (1,0) [0|1] "" BDCF
SG_ Sunroof_IntegrateSwitch : 63|3@0+ (1,0) [0|7] "" BDCF

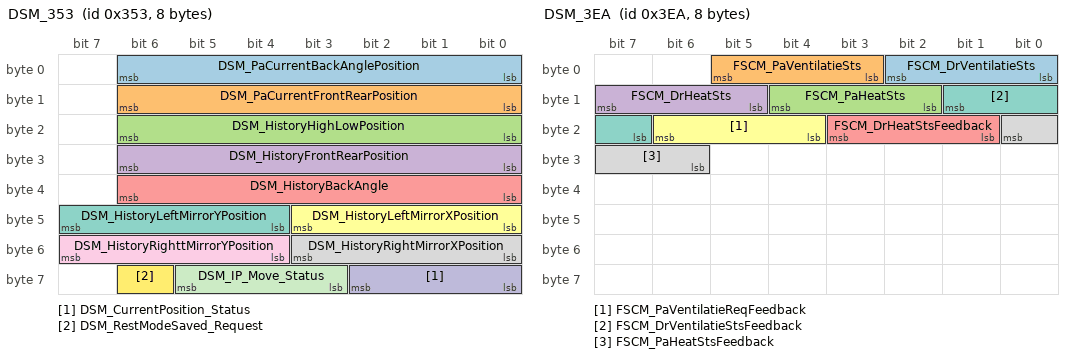
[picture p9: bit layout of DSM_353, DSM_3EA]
BO_ 851 DSM_353: 8 BDCF
SG_ DSM_PaCurrentBackAnglePosition : 6|7@0+ (1,0) [0|100] "%" THU,FIS
SG_ DSM_PaCurrentFrontRearPosition : 14|7@0+ (1,0) [0|100] "%" THU,FIS
SG_ DSM_HistoryHighLowPosition : 22|7@0+ (1,0) [0|100] "%" THU,FIS
SG_ DSM_HistoryFrontRearPosition : 30|7@0+ (1,0) [0|100] "%" THU,FIS
SG_ DSM_HistoryBackAngle : 38|7@0+ (1,0) [0|126] "°" THU,FIS
SG_ DSM_HistoryLeftMirrorXPosition : 43|4@0+ (5,0) [0|75] "°" THU,FIS
SG_ DSM_HistoryLeftMirrorYPosition : 47|4@0+ (5,0) [0|75] "°" THU,FIS
SG_ DSM_HistoryRightMirrorXPosition : 51|4@0+ (5,0) [0|75] "°" THU,FIS
SG_ DSM_HistoryRighttMirrorYPosition : 55|4@0+ (5,0) [0|75] "°" THU,FIS
SG_ DSM_CurrentPosition_Status : 58|3@0+ (1,0) [0|7] "" THU
SG_ DSM_IP_Move_Status : 61|3@0+ (1,0) [0|7] "" THU,IP
SG_ DSM_RestModeSaved_Request : 62|1@0+ (1,0) [0|1] "" THU,IP

BO_ 850 DSM_352: 8 BDCF
 SG_ DSM_MirrorTurnSetFeedback : 1|2@0+ (1,0) [0|3] ""  THU
 SG_ DSM_RightMirrorStatus : 3|2@0+ (1,0) [0|3] ""  THU
 SG_ DSM_LeftMirrorStatus : 5|2@0+ (1,0) [0|3] ""  THU
 SG_ DSM_ComityFeedback : 7|2@0+ (1,0) [0|3] ""  THU,FIS
 SG_ DSM_DrCurrentMemoryPosition : 11|4@0+ (1,0) [0|15] ""  THU,FIS
 SG_ DSM_PaPositionSaved_Request : 13|2@0+ (1,0) [0|3] ""  THU,IP,FIS
 SG_ DSM_MirrorPositionSaved_Request : 15|2@0+ (1,0) [0|3] ""  THU,IP,FIS
 SG_ DSM_DrCurrentHighLowPosition : 22|7@0+ (1,0) [0|100] "%"  THU,FIS
 SG_ DSM_DrCurrentFrontRearPosition : 30|7@0+ (1,0) [0|100] "%"  THU,FIS
 SG_ DSM_DrCurrentBackAngle : 38|7@0+ (1,0) [0|126] "°"  THU,FIS
 SG_ DSM_CurrentLeftMirrorXPosition : 43|4@0+ (5,0) [0|75] "°"  THU,FIS
 SG_ DSM_CurrentLeftMirrorYPosition : 47|4@0+ (5,0) [0|75] "°"  THU,FIS
 SG_ DSM_CurrentRightMirrorXPosition : 51|4@0+ (5,0) [0|75] "°"  THU,FIS
 SG_ DSM_CurrentRighttMirrorYPosition : 55|4@0+ (5,0) [0|75] "°"  THU,FIS
 SG_ DSM_SetSuccessed : 57|2@0+ (1,0) [0|3] ""  THU,FIS
 SG_ DSM_PositionStatus : 59|2@0+ (1,0) [0|3] ""  THU,FIS
 SG_ DSM_DrPositionSaved_Request : 61|2@0+ (1,0) [0|3] ""  THU,IP,FIS
 SG_ DSMPaComitySwitchFeedbasck : 62|1@0+ (1,0) [0|1] ""  THU,FIS
 SG_ DSMDrComitySwitchFeedbasck : 63|1@0+ (1,0) [0|1] ""  THU,FIS

BO_ 849 DSM_351: 8 BDCF
SG_ DSM_MemoryAlarm : 12|2@0+ (1,0) [0|3] "" THU
SG_ DSM_KeyMomerySts : 14|2@0+ (1,0) [0|3] "" THU
SG_ DSM_DSMMemoryPosition : 19|2@0+ (1,0) [0|3] "" THU
SG_ DSM_SlideForwardSwitch : 27|1@0+ (1,0) [0|1] "" THU
SG_ DSM_SlideBackwardSwtich : 28|1@0+ (1,0) [0|1] "" THU
SG_ DSM_BackForwardSwitch : 29|1@0+ (1,0) [0|1] "" THU
SG_ DSM_BackBackwardSwtich : 30|1@0+ (1,0) [0|1] "" THU
SG_ DSM_LeftMirrUpwardSW : 39|1@0+ (1,0) [0|1] "" THU
SG_ DSM_LeftMirrDownwardSW : 40|1@0+ (1,0) [0|1] "" THU
SG_ DSM_LeftMirrLeftwardSW : 41|1@0+ (1,0) [0|1] "" THU
SG_ DSM_LeftMirrRightwardSW : 42|1@0+ (1,0) [0|1] "" THU
SG_ DSM_RightMirrUpwardSW : 43|1@0+ (1,0) [0|1] "" THU
SG_ DSM_RightMirrDownwardSW : 44|1@0+ (1,0) [0|1] "" THU
SG_ DSM_RightMirrLeftwardSW : 45|1@0+ (1,0) [0|1] "" THU
SG_ DSM_RightMirrRightwardSW : 46|1@0+ (1,0) [0|1] "" THU
SG_ DSM_PaSlideForwardSwitch : 48|1@0+ (1,0) [0|1] "" THU
SG_ DSM_PaSlideBackwardSwtich : 49|1@0+ (1,0) [0|1] "" THU
SG_ DSM_PaBackForwardSwtich : 50|1@0+ (1,0) [0|1] "" THU
SG_ DSM_PaBackBackwardSwtich : 51|1@0+ (1,0) [0|1] "" THU
SG_ DSM_DrDownwardSwtich : 52|1@0+ (1,0) [0|1] "" THU
SG_ DSM_DrUpwardSwtich : 53|1@0+ (1,0) [0|1] "" THU
SG_ DSM_MemoryPositionFB : 55|2@0+ (1,0) [0|3] "" THU
SG_ DSM_PaCurrentMemoryPosition : 35|4@0+ (1,0) [0|15] "" THU
SG_ DSM_PaCurrentPosition_Status : 5|3@0+ (1,0) [0|7] "" THU
SG_ DSM_MirrCurrentPosition_Status : 7|2@0+ (1,0) [0|3] "" THU

BO_ 1002 DSM_3EA: 8 BDCF
SG_ FSCM_DrVentilatieSts : 2|3@0+ (1,0) [0|7] "" THU
SG_ FSCM_PaVentilatieSts : 5|3@0+ (1,0) [0|7] "" THU
SG_ FSCM_PaHeatSts : 12|3@0+ (1,0) [0|7] "" THU
SG_ FSCM_DrHeatSts : 15|3@0+ (1,0) [0|7] "" THU
SG_ FSCM_DrHeatStsFeedback : 19|3@0+ (1,0) [0|7] "" THU
SG_ FSCM_PaVentilatieReqFeedback : 22|3@0+ (1,0) [0|7] "" THU
SG_ FSCM_DrVentilatieStsFeedback : 9|3@0+ (1,0) [0|7] "" THU
SG_ FSCM_PaHeatStsFeedback : 16|3@0+ (1,0) [0|7] "" THU

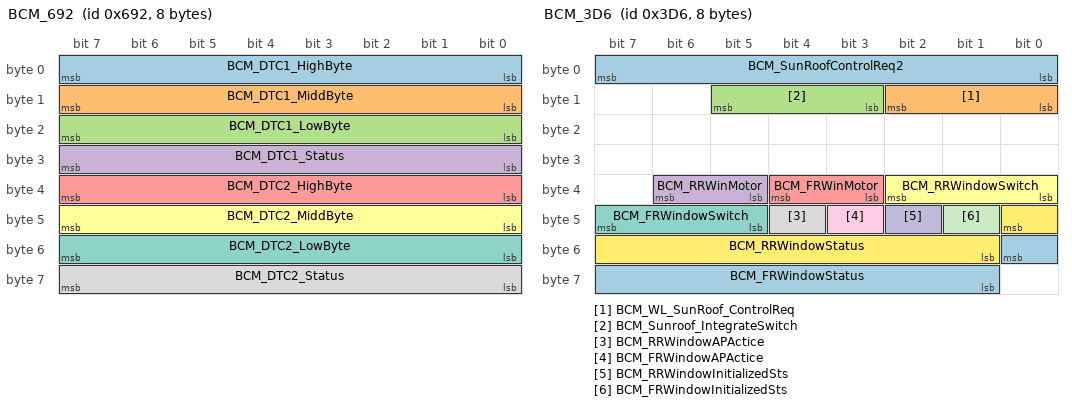
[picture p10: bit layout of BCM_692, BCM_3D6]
BO_ 1682 BCM_692: 8 BDCF
 SG_ BCM_DTC1_HighByte : 7|8@0+ (1,0) [0|255] "" Vector__XXX
 SG_ BCM_DTC1_MiddByte : 15|8@0+ (1,0) [0|255] "" Vector__XXX
 SG_ BCM_DTC1_LowByte : 23|8@0+ (1,0) [0|255] "" Vector__XXX
 SG_ BCM_DTC1_Status : 31|8@0+ (1,0) [0|255] "" Vector__XXX
 SG_ BCM_DTC2_HighByte : 39|8@0+ (1,0) [0|255] "" Vector__XXX
 SG_ BCM_DTC2_MiddByte : 47|8@0+ (1,0) [0|255] "" Vector__XXX
 SG_ BCM_DTC2_LowByte : 55|8@0+ (1,0) [0|255] "" Vector__XXX
 SG_ BCM_DTC2_Status : 63|8@0+ (1,0) [0|255] "" Vector__XXX

BO_ 982 BCM_3D6: 8 BDCF
SG_ BCM_SunRoofControlReq2 : 7|8@0+ (1,0) [0|256] "%" BDCR
SG_ BCM_WL_SunRoof_ControlReq : 10|3@0+ (1,0) [0|7] "" BDCR
SG_ BCM_Sunroof_IntegrateSwitch : 13|3@0+ (1,0) [0|7] "" BDCR
SG_ BCM_RRWinMotor : 38|2@0+ (1,0) [0|3] "" Vector__XXX
SG_ BCM_FRWinMotor : 36|2@0+ (1,0) [0|3] "" Vector__XXX
SG_ BCM_RRWindowSwitch : 34|3@0+ (1,0) [0|7] "" THU
SG_ BCM_FRWindowSwitch : 47|3@0+ (1,0) [0|7] "" THU
SG_ BCM_RRWindowAPActice : 44|1@0+ (1,0) [0|1] "" Vector__XXX
SG_ BCM_FRWindowAPActice : 43|1@0+ (1,0) [0|1] "" Vector__XXX
SG_ BCM_RRWindowInitializedSts : 42|1@0+ (1,0) [0|1] "" THU,IP
SG_ BCM_FRWindowInitializedSts : 41|1@0+ (1,0) [0|1] "" THU,IP
SG_ BCM_RRWindowStatus : 40|8@0+ (0.5,0) [0|100] "%" Vector__XXX
SG_ BCM_FRWindowStatus : 48|8@0+ (0.5,0) [0|100] "%" Vector__XXX

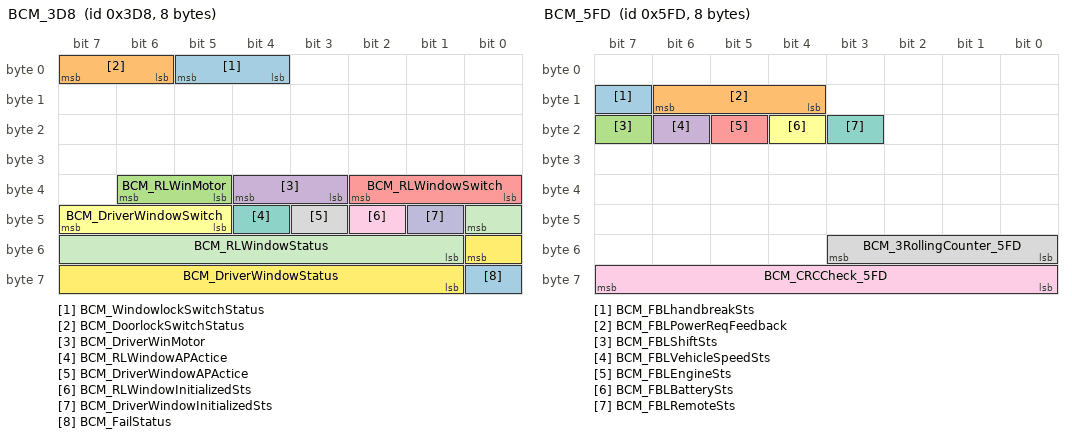
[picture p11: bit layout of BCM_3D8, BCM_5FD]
BO_ 984 BCM_3D8: 8 BDCF
SG_ BCM_WindowlockSwitchStatus : 5|2@0+ (1,0) [0|3] "" THU
SG_ BCM_DoorlockSwitchStatus : 7|2@0+ (1,0) [0|3] "" THU
SG_ BCM_RLWinMotor : 38|2@0+ (1,0) [0|3] "" Vector__XXX
SG_ BCM_DriverWinMotor : 36|2@0+ (1,0) [0|3] "" Vector__XXX
SG_ BCM_RLWindowSwitch : 34|3@0+ (1,0) [0|7] "" THU
SG_ BCM_DriverWindowSwitch : 47|3@0+ (1,0) [0|7] "" THU
SG_ BCM_RLWindowAPActice : 44|1@0+ (1,0) [0|1] "" Vector__XXX
SG_ BCM_DriverWindowAPActice : 43|1@0+ (1,0) [0|1] "" Vector__XXX
SG_ BCM_RLWindowInitializedSts : 42|1@0+ (1,0) [0|1] "" THU,IP
SG_ BCM_DriverWindowInitializedSts : 41|1@0+ (1,0) [0|1] "" THU,IP
SG_ BCM_RLWindowStatus : 40|8@0+ (0.5,0) [0|100] "%" Vector__XXX
SG_ BCM_DriverWindowStatus : 48|8@0+ (0.5,0) [0|100] "%" Vector__XXX
SG_ BCM_FailStatus : 56|1@0+ (1,0) [0|1] "" Vector__XXX

BO_ 1533 BCM_5FD: 8 BDCF
SG_ BCM_FBLhandbreakSts : 15|1@0+ (1,0) [0|1] "" THU
SG_ BCM_FBLPowerReqFeedback : 14|3@0+ (1,0) [0|7] "" THU
SG_ BCM_FBLShiftSts : 23|1@0+ (1,0) [0|1] "" THU
SG_ BCM_FBLVehicleSpeedSts : 22|1@0+ (1,0) [0|1] "" THU
SG_ BCM_FBLEngineSts : 21|1@0+ (1,0) [0|1] "" THU
SG_ BCM_FBLBatterySts : 20|1@0+ (1,0) [0|1] "" THU
SG_ BCM_FBLRemoteSts : 19|1@0+ (1,0) [0|1] "" THU
SG_ BCM_3RollingCounter_5FD : 51|4@0+ (1,0) [0|15] "" THU
SG_ BCM_CRCCheck_5FD : 63|8@0+ (1,0) [0|255] "" THU

BO_ 1535 BCM_5FF: 8 BDCF
SG_ BCM_AutoLockFeedback : 7|2@0+ (1,0) [0|3] "" Vector__XXX
SG_ BCM_RKEUnlockDoorTypeSetStatus : 5|2@0+ (1,0) [0|3] "" THU,IP
SG_ BCM_AutoParkUnlockSetStatus : 3|2@0+ (1,0) [0|3] "" THU,IP
SG_ BCM_AutoSpeedLockSetStatus : 1|2@0+ (1,0) [0|3] "" THU,IP
SG_ BCM_RmoteLockFeedback : 15|3@0+ (1,0) [0|7] "" THU
SG_ BCM_TwiceLockDoorSetStatus : 12|2@0+ (1,0) [0|3] "" Vector__XXX
SG_ BCM_AutoLeaveLockSetStatus : 10|3@0+ (1,0) [0|7] "" Vector__XXX
SG_ PEPS_KeyPositionStatus : 23|3@0+ (1,0) [0|7] "" THU,FIS
SG_ PEPS_PeScanDoorStatus : 20|1@0+ (1,0) [0|1] "" Vector__XXX
SG_ BCM_KeyInSignal : 19|1@0+ (1,0) [0|1] "" THU,IP
SG_ BCM_RmoteUnLockFeedback : 18|3@0+ (1,0) [0|3] "" THU
SG_ PEPS_GreetLampFB : 31|3@0+ (1,0) [0|7] "" THU
SG_ PEPS_DoorHandleButtonSignal : 28|1@0+ (1,0) [0|1] "" Vector__XXX
SG_ PEPS_UnlockModeTransitionSignal : 27|1@0+ (1,0) [0|1] "" Vector__XXX
SG_ PEPS_KeyInCarAlarmSignal : 26|1@0+ (1,0) [0|1] "" THU,IP,FIS
SG_ PEPS_KeyUndetectedAlarmSignal : 25|1@0+ (1,0) [0|1] "" THU,IP
SG_ PEPS_KeyBatteryStatus : 24|1@0+ (1,0) [0|1] "" THU,IP
SG_ PEPS_HandleProximitySensorSignal : 39|2@0+ (1,0) [0|3] "" Vector__XXX
SG_ PEPS_SmartUnlockstatus : 37|2@0+ (1,0) [0|3] "" THU
SG_ PEPS_Smartlockstatus : 35|2@0+ (1,0) [0|3] "" THU
SG_ PEPS_SmartTrunkUlockStaus : 33|2@0+ (1,0) [0|3] "" Vector__XXX
SG_ LCM_MirrorAutoFoldSetStatus : 47|2@0+ (1,0) [0|3] "" Vector__XXX
SG_ BCM_CarRemindFeedback : 45|2@0+ (1,0) [0|3] "" THU
SG_ BCM_RearWiperSetStatus : 43|2@0+ (1,0) [0|3] "" THU
SG_ BCM_MirrorAutoFoldSetStatus : 41|2@0+ (1,0) [0|3] "" THU
SG_ BCM_CarWashMirrorFoldFeedback : 55|2@0+ (1,0) [0|3] "" Vector__XXX
SG_ BCM_RemoteControlSwtichSetStatus : 53|3@0+ (1,0) [0|7] "" THU
SG_ BCM_RemoteControlWindowSetStatus : 50|2@0+ (1,0) [0|3] "" THU
SG_ BCM_RemoteCtrlSunroofSetStatus : 63|2@0+ (1,0) [0|3] "" THU
SG_ BCM_LockAutoClsSunroofSetStatus : 61|2@0+ (1,0) [0|3] "" THU
SG_ BCM_LatchOverheatProtect : 59|1@0+ (1,0) [0|1] "" THU
SG_ BCM_RemoteTrunkFeedback : 58|3@0+ (1,0) [0|7] "" Vector__XXX

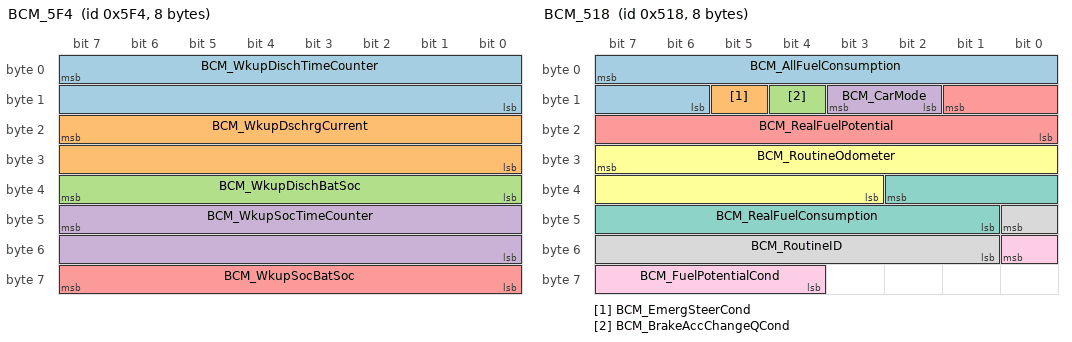
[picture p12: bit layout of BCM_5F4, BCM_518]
BO_ 1524 BCM_5F4: 8 BDCF
SG_ BCM_WkupDischTimeCounter : 7|16@0+ (1,0) [0|65535] "" Vector__XXX
SG_ BCM_WkupDschrgCurrent : 23|16@0+ (1,0) [0|65536] "mA" Vector__XXX
SG_ BCM_WkupDischBatSoc : 39|8@0+ (1,0) [0|100] "%" Vector__XXX
SG_ BCM_WkupSocTimeCounter : 47|16@0+ (1,0) [0|65535] "" Vector__XXX
SG_ BCM_WkupSocBatSoc : 63|8@0+ (1,0) [0|100] "%" Vector__XXX

BO_ 1510 BCM_5E6: 8 BDCF
SG_ BCM_HotMagCurrentData : 7|64@0+ (1,0) [0|0] "" Vector__XXX

BO_ 1304 BCM_518: 8 BDCF
SG_ BCM_AllFuelConsumption : 7|10@0+ (0.1,0) [0|102.3] "L" Vector__XXX
SG_ BCM_EmergSteerCond : 13|1@0+ (1,0) [0|1] "" Vector__XXX
SG_ BCM_BrakeAccChangeQCond : 12|1@0+ (1,0) [0|1] "" Vector__XXX
SG_ BCM_CarMode : 11|2@0+ (1,0) [0|3] "" THU,IP
SG_ BCM_RealFuelPotential : 9|10@0+ (0.015,0) [0|15.345] "ml" Vector__XXX
SG_ BCM_RoutineOdometer : 31|13@0+ (0.1,0) [0|819.1] "KM" Vector__XXX
SG_ BCM_RealFuelConsumption : 34|10@0+ (0.015,0) [0|15.345] "ml" Vector__XXX
SG_ BCM_RoutineID : 40|8@0+ (1,0) [0|255] "" Vector__XXX
SG_ BCM_FuelPotentialCond : 48|5@0+ (1,0) [0|31] "" Vector__XXX

BO_ 1298 BCM_512: 8 BDCF
SG_ PEPS_VINFrameNumber : 7|8@0+ (1,0) [0|255] "" THU,FIS,ETC
SG_ PEPS_VIN : 15|56@0+ (1,0) [0|1] "" THU,FIS,ETC

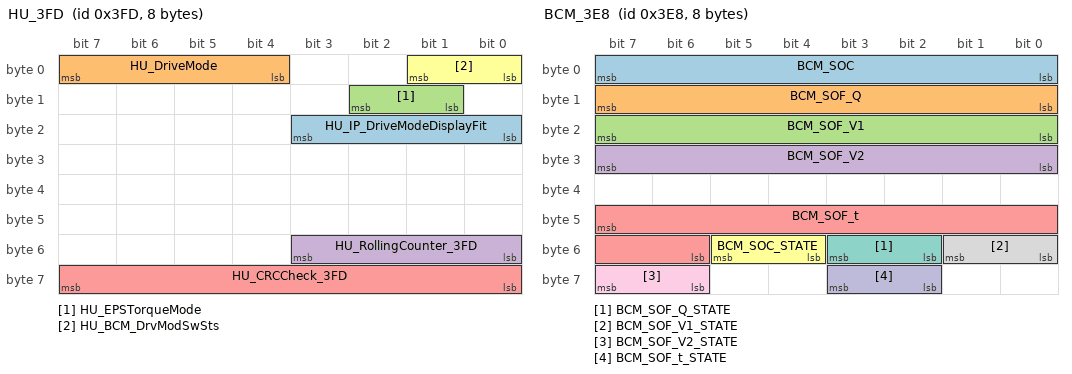
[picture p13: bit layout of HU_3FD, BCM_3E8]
BO_ 1021 HU_3FD: 8 THU
 SG_ HU_IP_DriveModeDisplayFit : 19|4@0+ (1,0) [0|15] "" BDCF,IP
 SG_ HU_DriveMode : 7|4@0+ (1,0) [0|15] "" BDCF,IP
 SG_ HU_EPSTorqueMode : 10|2@0+ (1,0) [0|3] "" BDCF
 SG_ HU_RollingCounter_3FD : 51|4@0+ (1,0) [0|15] "" BDCF,IP
 SG_ HU_CRCCheck_3FD : 63|8@0+ (1,0) [0|255] "" BDCF,IP
 SG_ HU_BCM_DrvModSwSts : 1|2@0+ (1,0) [0|3] "" BDCF

BO_ 1023 BCM_3FF: 8 BDCF
SG_ BCM_MusicPlayRequestSignal : 7|2@0+ (1,0) [0|3] "" THU
SG_ BCM_MusicLightModeSelectSts : 2|3@0+ (1,0) [0|7] "" THU
SG_ BCM_FollowMeTurnon : 15|1@0+ (1,0) [0|1] "" THU,HU,IP
SG_ BCM_Musiclightfeedback : 12|2@0+ (1,0) [0|3] "" THU
SG_ BCM_OutWelcomeSoundFeedback : 10|3@0+ (1,0) [0|7] "" THU
SG_ BCM_FrontPositionLampError : 23|1@0+ (1,0) [0|1] "" THU,IP
SG_ BCM_AutoHeadlightSts : 22|1@0+ (1,0) [0|1] "" THU,HU,IP
SG_ BCM_FrontFoglampStatus : 21|2@0+ (1,0) [0|3] "" THU,HU,IP
SG_ BCM_RearFoglampStatus : 19|2@0+ (1,0) [0|3] "" THU,HU,IP
SG_ BCM_PositionLampStatus : 17|2@0+ (1,0) [0|3] "" THU,HU,IP
SG_ BCM_BrakeLampError : 31|1@0+ (1,0) [0|1] "" THU,IP
SG_ BCM_RightRearFoglampError : 30|1@0+ (1,0) [0|1] "" THU,IP
SG_ BCM_LeftRearFoglampError : 29|1@0+ (1,0) [0|1] "" THU,IP
SG_ BCM_RightFrontFoglampError : 28|1@0+ (1,0) [0|1] "" THU,IP
SG_ BCM_LeftFrontFoglampError : 27|1@0+ (1,0) [0|1] "" THU,IP
SG_ BCM_RightLowBeamError : 26|1@0+ (1,0) [0|1] "" THU,IP
SG_ BCM_LeftLowBeamError : 25|1@0+ (1,0) [0|1] "" THU,IP
SG_ BCM_RearPositionLampError : 24|1@0+ (1,0) [0|1] "" THU,IP
SG_ BCM_ReverseLightSts : 39|2@0+ (1,0) [0|3] "" THU
SG_ BCM_RightPositionLampError : 37|1@0+ (1,0) [0|1] "" THU,IP
SG_ BCM_LeftPositionLampError : 36|1@0+ (1,0) [0|1] "" THU,IP
SG_ BCM_RightDayLampError : 35|1@0+ (1,0) [0|1] "" THU,IP
SG_ BCM_LeftDayLampError : 34|1@0+ (1,0) [0|1] "" THU,IP
SG_ BCM_ReverseLampError : 33|1@0+ (1,0) [0|1] "" THU
SG_ BCM_CHMLampError : 32|1@0+ (1,0) [0|1] "" THU
SG_ BCM_RearRightTuningLightFaultSts : 47|1@0+ (1,0) [0|1] "" THU
SG_ BCM_TurnIndicatorRightError : 46|1@0+ (1,0) [0|1] "" THU,IP
SG_ BCM_TurnIndicatorLeftError : 45|1@0+ (1,0) [0|1] "" THU,IP
SG_ BCM_PositionLampSwitchStatus : 44|1@0+ (1,0) [0|1] "" THU
SG_ BCM_DRLSts : 43|1@0+ (1,0) [0|1] "" THU
SG_ BCM_FollowMeHomeLightSetStatus : 42|3@0+ (1,0) [0|7] "" THU,IP
SG_ BCM_AutoHeadlightSetSts : 54|1@0+ (1,0) [0|1] "" THU,HU
SG_ BCM_HighBeamLampError : 53|1@0+ (1,0) [0|1] "" THU
SG_ BCM_RearLeftTuningLightFaultSts : 52|1@0+ (1,0) [0|1] "" THU
SG_ BCM_LightingBackwardWarningStatus : 51|2@0+ (1,0) [0|3] "" THU
SG_ BCM_LightingDoorOpenWarningStatus : 49|2@0+ (1,0) [0|3] "" THU
SG_ BCM_AutoturnlightovertakemodeSetSts : 63|2@0+ (1,0) [0|3] "" THU,IP
SG_ BCM_BrakeLampStatus : 56|1@0+ (1,0) [0|1] "" THU
SG_ BCM_RainOpenLightStatus : 58|2@0+ (1,0) [0|3] "" THU
 SG_ BCM_ParkingWaitLightStatus : 60|2@0+ (1,0) [0|3] "" THU
 SG_ BCM_EmBrakeFlashStatus : 14|2@0+ (1,0) [0|3] "" THU
SG_ BCM_AutoFlashlightovertakeSts : 4|2@0+ (1,0) [0|3] ""  THU

BO_ 1007 BCM_3EF: 8 BDCF
 SG_ BCM_AtmoLightTopLightEnableSts : 7|2@0+ (1,0) [0|3] "" Vector__XXX
 SG_ BCM_AtmosphereLightswitchSetStatus : 5|2@0+ (1,0) [0|3] "" THU
 SG_ BCM_SetDoorLightStatus : 3|2@0+ (1,0) [0|3] "" THU
 SG_ BCM_RoomLightControlSts : 1|2@0+ (1,0) [0|3] "" THU
 SG_ BCM_Dimmerlevel : 15|5@0+ (1,0) [0|31] "" Vector__XXX
 SG_ BCM_AtmosphereLightbrightnessSetStatus : 8|4@0+ (0.1,0) [0|15] "" THU
 SG_ BCM_DimmerLevelSts : 20|5@0+ (1,0) [0|31] "" Vector__XXX
 SG_ BCM_AtmosphereLightColorSetStatus : 31|8@0+ (1,0) [0|255] "" THU
 SG_ BCM_SEWEnableSts : 39|2@0+ (1,0) [0|3] "" Vector__XXX
 SG_ BCM_WelcomeAtmoLightEnableSts : 37|2@0+ (1,0) [0|3] "" Vector__XXX
 SG_ BCM_AtmoLightLinkStartEnableSts : 35|2@0+ (1,0) [0|3] "" Vector__XXX
 SG_ BCM_AtmoLightOverspeedEnableSts : 33|2@0+ (1,0) [0|3] "" Vector__XXX
 SG_ BCM_SenseAQIEnable : 47|2@0+ (1,0) [0|3] "" Vector__XXX
 SG_ BCM_AtmoLightSceneMode_FeedBack : 45|2@0+ (1,0) [0|3] "" Vector__XXX
 SG_ BCM_AtmoLightLinkDriveModeSts : 43|2@0+ (1,0) [0|3] "" Vector__XXX
 SG_ BCM_AtmoLightLinkDoorEnableSts : 41|2@0+ (1,0) [0|3] "" Vector__XXX
 SG_ BCM_AtmoLightAAEnableSts : 55|2@0+ (1,0) [0|3] "" Vector__XXX
 SG_ BCM_SenseBlossomEnable : 53|2@0+ (1,0) [0|3] "" Vector__XXX
 SG_ BCM_LaneChangeTurnLightSetStatus : 51|3@0+ (1,0) [0|7] "" THU
 SG_ BCM_ALCEnableStatus : 59|2@0+ (1,0) [0|3] "" THU
 SG_ BCM_Interactive_switch_Status : 57|2@0+ (1,0) [0|3] "" Vector__XXX
 SG_ BCM_HonkovertakeSts : 10|2@0+ (1,0) [0|3] ""  THU

BO_ 1000 BCM_3E8: 8 BDCF
SG_ BCM_SOC : 7|8@0+ (1,0) [0|100] "%" THU
SG_ BCM_SOF_Q : 15|8@0+ (0.5,0) [0|127] "Ah" THU
SG_ BCM_SOF_V1 : 23|8@0+ (0.0625,0) [0|15.875] "V" THU
SG_ BCM_SOF_V2 : 31|8@0+ (0.0625,0) [0|15.875] "V" THU
SG_ BCM_SOF_t : 47|10@0+ (1,0) [0|1023] "min" THU
SG_ BCM_SOC_STATE : 53|2@0+ (1,0) [0|3] "" THU
SG_ BCM_SOF_Q_STATE : 51|2@0+ (1,0) [0|3] "" THU
SG_ BCM_SOF_V1_STATE : 49|2@0+ (1,0) [0|3] "" THU
SG_ BCM_SOF_V2_STATE : 63|2@0+ (1,0) [0|3] "" THU
SG_ BCM_SOF_t_STATE : 59|2@0+ (1,0) [0|3] "" THU

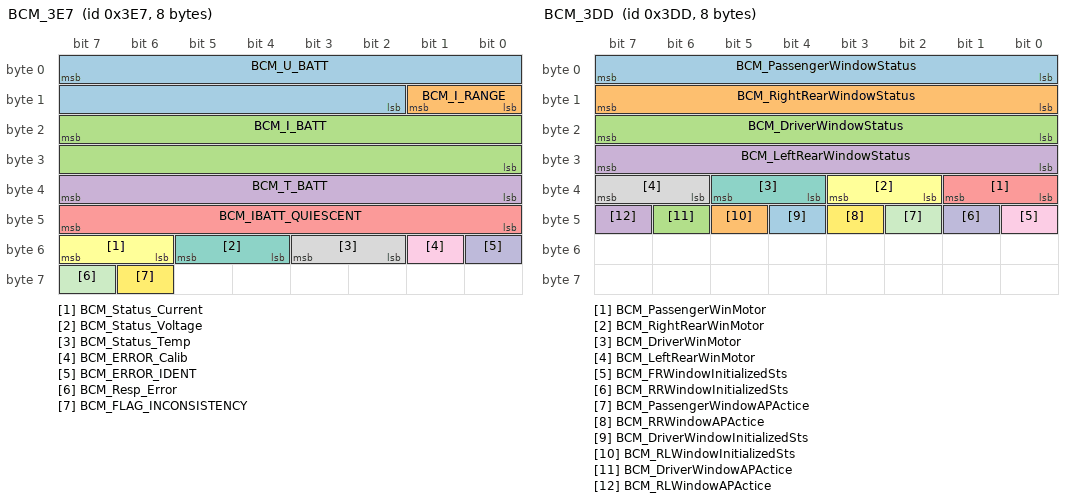
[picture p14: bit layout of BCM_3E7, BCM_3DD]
BO_ 999 BCM_3E7: 8 BDCF
SG_ BCM_U_BATT : 7|14@0+ (0.0009765625,3) [3|18] "V" THU
SG_ BCM_I_RANGE : 9|2@0+ (1,0) [0|3] "" THU
SG_ BCM_I_BATT : 23|16@0+ (1,0) [7168|58368] "A" THU
SG_ BCM_T_BATT : 39|8@0+ (1,-40) [-40|105] "°C" THU
SG_ BCM_IBATT_QUIESCENT : 47|8@0+ (0.00390625,0) [0|0.984375] "A" THU
SG_ BCM_Status_Current : 55|2@0+ (1,0) [0|3] "" THU
SG_ BCM_Status_Voltage : 53|2@0+ (1,0) [0|3] "" THU
SG_ BCM_Status_Temp : 51|2@0+ (1,0) [0|3] "" THU
SG_ BCM_ERROR_Calib : 49|1@0+ (1,0) [0|1] "" THU
SG_ BCM_ERROR_IDENT : 48|1@0+ (1,0) [0|1] "" THU
SG_ BCM_Resp_Error : 63|1@0+ (1,0) [0|1] "" THU
SG_ BCM_FLAG_INCONSISTENCY : 62|1@0+ (1,0) [0|1] "" THU

BO_ 989 BCM_3DD: 8 BDCF
SG_ BCM_PassengerWindowStatus : 7|8@0+ (0.5,0) [0|100] "%" THU,IP,BDCR
SG_ BCM_RightRearWindowStatus : 15|8@0+ (0.5,0) [0|100] "%" THU,IP,BDCR
SG_ BCM_DriverWindowStatus : 23|8@0+ (0.5,0) [0|100] "%" THU,IP,BDCR
SG_ BCM_LeftRearWindowStatus : 31|8@0+ (0.5,0) [0|100] "%" THU,IP,BDCR
SG_ BCM_PassengerWinMotor : 33|2@0+ (1,0) [0|3] "" Vector__XXX
SG_ BCM_RightRearWinMotor : 35|2@0+ (1,0) [0|3] "" Vector__XXX
SG_ BCM_DriverWinMotor : 37|2@0+ (1,0) [0|3] "" Vector__XXX
SG_ BCM_LeftRearWinMotor : 39|2@0+ (1,0) [0|3] "" Vector__XXX
SG_ BCM_FRWindowInitializedSts : 40|1@0+ (1,0) [0|1] "" THU
SG_ BCM_RRWindowInitializedSts : 41|1@0+ (1,0) [0|1] "" THU
SG_ BCM_PassengerWindowAPActice : 42|1@0+ (1,0) [0|1] "" THU
SG_ BCM_RRWindowAPActice : 43|1@0+ (1,0) [0|1] "" THU
SG_ BCM_DriverWindowInitializedSts : 44|1@0+ (1,0) [0|1] "" THU
SG_ BCM_RLWindowInitializedSts : 45|1@0+ (1,0) [0|1] "" THU
SG_ BCM_DriverWindowAPActice : 46|1@0+ (1,0) [0|1] "" THU
SG_ BCM_RLWindowAPActice : 47|1@0+ (1,0) [0|1] "" THU

BO_ 942 BCM_3AE: 8 BDCF
SG_ BCM_Q_Charge : 7|16@0+ (0.125,0) [0|8191.75] "Ah" THU
SG_ BCM_Q_Discharge : 23|16@0+ (0.125,0) [0|8191.75] "Ah" THU

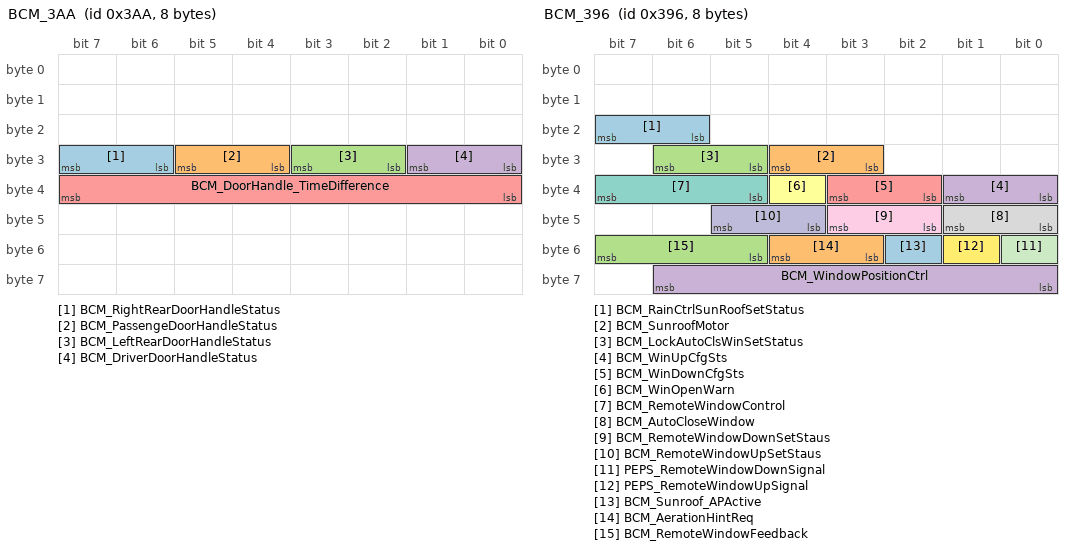
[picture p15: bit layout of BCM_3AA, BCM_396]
BO_ 938 BCM_3AA: 8 BDCF
SG_ BCM_RightRearDoorHandleStatus : 31|2@0+ (1,0) [0|3] "" Vector__XXX
SG_ BCM_PassengeDoorHandleStatus : 29|2@0+ (1,0) [0|3] "" Vector__XXX
SG_ BCM_LeftRearDoorHandleStatus : 27|2@0+ (1,0) [0|3] "" Vector__XXX
SG_ BCM_DriverDoorHandleStatus : 25|2@0+ (1,0) [0|3] "" Vector__XXX
SG_ BCM_DoorHandle_TimeDifference : 39|8@0+ (5,0) [0|255] "" Vector__XXX

BO_ 918 BCM_396: 8 BDCF
 SG_ BCM_RainCtrlSunRoofSetStatus : 23|2@0+ (1,0) [0|3] ""  THU
 SG_ BCM_SunroofMotor : 28|2@0+ (1,0) [0|3] ""  THU
 SG_ BCM_LockAutoClsWinSetStatus : 30|2@0+ (1,0) [0|3] ""  THU
 SG_ BCM_WinUpCfgSts : 33|2@0+ (1,0) [0|3] "" Vector__XXX
 SG_ BCM_WinDownCfgSts : 35|2@0+ (1,0) [0|3] "" Vector__XXX
 SG_ BCM_WinOpenWarn : 36|1@0+ (1,0) [0|1] "" Vector__XXX
 SG_ BCM_RemoteWindowControl : 39|3@0+ (1,0) [0|7] "" Vector__XXX
 SG_ BCM_AutoCloseWindow : 41|2@0+ (1,0) [0|3] "" Vector__XXX
 SG_ BCM_RemoteWindowDownSetStaus : 43|2@0+ (1,0) [0|3] "" Vector__XXX
 SG_ BCM_RemoteWindowUpSetStaus : 45|2@0+ (1,0) [0|3] "" Vector__XXX
 SG_ PEPS_RemoteWindowDownSignal : 48|1@0+ (1,0) [0|1] ""  THU
 SG_ PEPS_RemoteWindowUpSignal : 49|1@0+ (1,0) [0|1] ""  THU
 SG_ BCM_Sunroof_APActive : 50|1@0+ (1,0) [0|1] "" Vector__XXX
 SG_ BCM_AerationHintReq : 52|2@0+ (1,0) [0|3] "" Vector__XXX
 SG_ BCM_RemoteWindowFeedback : 55|3@0+ (1,0) [0|7] ""  THU
 SG_ BCM_WindowPositionCtrl : 62|7@0+ (1,0) [0|127] "" Vector__XXX

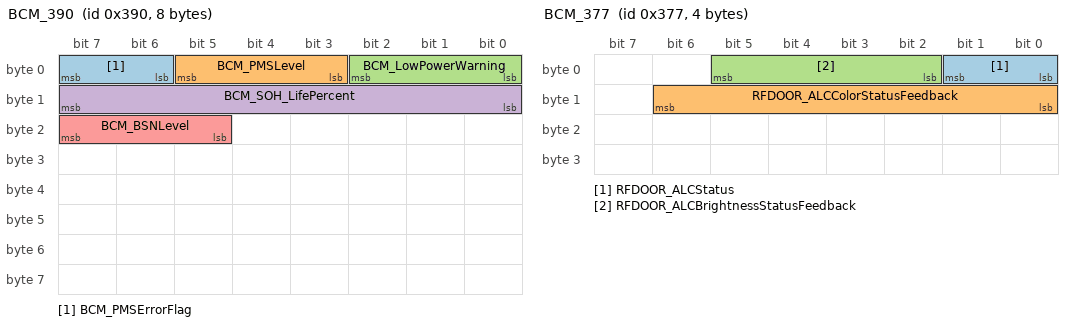
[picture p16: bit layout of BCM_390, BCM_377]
BO_ 912 BCM_390: 8 BDCF
SG_ BCM_PMSErrorFlag : 7|2@0+ (1,0) [0|3] "" THU,IP
SG_ BCM_PMSLevel : 5|3@0+ (1,0) [0|7] "" THU,IP
SG_ BCM_LowPowerWarning : 2|3@0+ (1,0) [0|7] "" THU,IP
SG_ BCM_SOH_LifePercent : 15|8@0+ (1,0) [0|100] "%" THU,IP
SG_ BCM_BSNLevel : 23|3@0+ (1,0) [0|7] "" THU,IP

BO_ 905 BCM_389: 8 BDCF
SG_ BCM_RearWiperSwitchStatus : 1|2@0+ (1,0) [0|3] "" THU
SG_ BCM_PositionLampSwitchStatus : 3|2@0+ (1,0) [0|3] "" THU
SG_ BCM_RearFoglampSwitchStatus : 5|2@0+ (1,0) [0|3] "" THU
SG_ BCM_HighBeamSwitchStatus : 7|2@0+ (1,0) [0|3] "" THU
SG_ BCM_LowBeamSwitchStatus : 9|2@0+ (1,0) [0|3] "" THU
SG_ BCM_FrontWashSwitchStatus : 11|2@0+ (1,0) [0|3] "" THU
SG_ BCM_RearWashSwitchStatus : 13|2@0+ (1,0) [0|3] "" THU
SG_ BCM_AutoHeadlightSwitchStatus : 15|2@0+ (1,0) [0|3] "" THU
SG_ BCM_RoofLampDoorSwitchStatus : 17|2@0+ (1,0) [0|3] "" THU
SG_ BCM_PassengerWindowSwitchStatus1 : 19|2@0+ (1,0) [0|3] "" THU
SG_ BCM_LeftRearWindowSwitchStatus1 : 21|2@0+ (1,0) [0|3] "" THU
SG_ BCM_RightRearWindowSwitchStatus1 : 23|2@0+ (1,0) [0|3] "" THU
SG_ BCM_RearMirrorFoldStatus : 25|2@0+ (1,0) [0|3] "" THU
SG_ BCM_SunRoofSwitchStatus : 27|2@0+ (1,0) [0|3] "" THU
SG_ BCM_SunshadeSwitchStatus : 29|2@0+ (1,0) [0|3] "" THU
SG_ BCM_CarWashModelstatus : 31|2@0+ (1,0) [0|1] "" THU
SG_ BCM_FrontWiperIntervalTime : 39|3@0+ (1,0) [0|7] "" THU
SG_ RLS_WiperAutoSpReq : 36|3@0+ (1,0) [0|3] "" THU
SG_ BCM_FrontWiperSwitchStatus : 33|3@0+ (1,0) [0|7] "" THU
SG_ BCM_FrontWiperSensibility : 46|3@0+ (1,0) [0|7] "" THU
SG_ BCM_OverTakeLightSwitchStatus : 43|2@0+ (1,0) [0|3] "" THU
SG_ BCM_FrontFoglampSwitchStatus : 41|2@0+ (1,0) [0|3] "" THU
SG_ BCM_EmergencyLightSwitchStatus : 55|2@0+ (1,0) [0|3] "" THU
SG_ BCM_TrumpetSwitchStatus : 53|1@0+ (1,0) [0|1] "" THU
SG_ BCM_FrontWiperPosition : 52|1@0+ (1,0) [0|1] "" THU
SG_ BCM_RearWiperPosition : 51|1@0+ (1,0) [0|1] "" THU
SG_ BCM_WiperServiceReqStatus : 50|1@0+ (1,0) [0|1] "" THU
SG_ BCM_WiperForbiddenSta : 49|1@0+ (1,0) [0|1] "" THU
SG_ BCM_WindowContralSta : 48|1@0+ (1,0) [0|1] "" THU
SG_ BCM_BrakePedalStatus : 57|2@0+ (1,0) [0|3] "" THU,IP,FIS
SG_ BCM_ValetModelFeedback : 62|3@0+ (1,0) [0|7] "" THU

BO_ 903 BCM_387: 8 BDCF
SG_ BCM_DriveModeFeedback : 7|2@0+ (1,0) [0|3] "" Vector__XXX
SG_ BCM_DriveModeStatus : 5|4@0+ (1,0) [0|15] "" Vector__XXX
SG_ BCM__BLEKeyIndicator : 1|2@0+ (1,0) [0|3] "" Vector__XXX
SG_ BCM_DrivingModeMemoryStatus : 15|2@0+ (1,0) [0|3] "" Vector__XXX
SG_ BCM_DriveModeSet : 13|3@0+ (1,0) [0|7] "" Vector__XXX
SG_ BCM_RainfallLevel : 19|4@0+ (1,0) [0|15] "" THU
SG_ BCM_ThemeChangeSet : 29|2@0+ (1,0) [0|3] "" Vector__XXX
SG_ BCM_FrontWashStatus : 27|2@0+ (1,0) [0|3] "" THU
SG_ BCM_FrontWiperStatus : 25|2@0+ (1,0) [0|3] "" THU
SG_ BCM_RLS_Light_switch_reason : 39|8@0+ (1,0) [0|255] "" THU,IP
SG_ BCM_BuzzerWarningMode : 47|5@0+ (1,0) [0|31] "" THU,HU,IP
SG_ BCM_AmbientLightStatus : 42|1@0+ (1,0) [0|1] "" Vector__XXX
SG_ BCM_Statusrainsensor : 41|1@0+ (1,0) [0|1] "" THU,IP
SG_ BCM_Statuslowbeam : 40|1@0+ (1,0) [0|1] "" THU,IP
SG_ BCM_SystemFailureFlag : 55|1@0+ (1,0) [0|1] "" THU
SG_ BCM_RearWiperStatus : 54|1@0+ (1,0) [0|1] "" THU
SG_ BCM_SaveEnergySetStatus : 53|2@0+ (1,0) [0|3] "" Vector__XXX
SG_ BCM_VoiceWelcometSts : 51|2@0+ (1,0) [0|3] "" THU
SG_ BCM_VoiceWelcomeTipsContent : 58|3@0+ (1,0) [0|7] "" THU
SG_ BCM_RainOpenLightRequest : 60|2@0+ (1,0) [0|3] "" THU
 SG_ BCM_LightThemeSts : 63|2@0+ (1,0) [0|3] "" THU

BO_ 902 BCM_386: 8 BDCF
SG_ BCM_LeftLowFrequencyAntennaDiagnosis : 1|2@0+ (1,0) [0|3] "" THU
SG_ BCM_RightLowFrequencyAntennaDiagnosis : 3|2@0+ (1,0) [0|3] "" THU
SG_ BCM_FrontCarLowFrequencyAntennaDiagnosis : 5|2@0+ (1,0) [0|3] "" THU
SG_ BCM_MiddleCarLowFrequencyAntennaDiagnosis : 7|2@0+ (1,0) [0|3] "" THU
SG_ BCM_TrunkLowFrequencyAntennaDiagnosis : 9|2@0+ (1,0) [0|3] "" THU
SG_ BCM_RearFoglampDiagnosis : 11|2@0+ (1,0) [0|3] "" THU
SG_ BCM_LeftLowBeamDiagnosis : 13|2@0+ (1,0) [0|3] "" THU
SG_ BCM_RightLowBeamDiagnosis : 15|2@0+ (1,0) [0|3] "" THU
SG_ BCM_LeftHighBeamDiagnosis : 17|2@0+ (1,0) [0|3] "" THU
SG_ BCM_RightHighBeamDiagnosis : 19|2@0+ (1,0) [0|3] "" THU
SG_ BCM_BrakeLightDiagnosis : 21|2@0+ (1,0) [0|3] "" THU
SG_ BCM_PositionLampDiagnosis : 23|2@0+ (1,0) [0|3] "" THU
SG_ BCM_TurnIndicatorLeftFrontDiagnosis : 25|2@0+ (1,0) [0|3] "" THU
SG_ BCM_TurnIndicatorRightFrontDiagnosis : 27|2@0+ (1,0) [0|3] "" THU
SG_ BCM_TurnIndicatorLeftRearDiagnosis : 29|2@0+ (1,0) [0|3] "" THU
SG_ BCM_TurnIndicatorRightRearDiagnosis : 31|2@0+ (1,0) [0|3] "" THU
SG_ BCM_RLS_NotInstalled : 33|2@0+ (1,0) [0|3] "" THU
SG_ BCM_LFPressureSensorDiagnosis : 35|2@0+ (1,0) [0|3] "" THU
SG_ BCM_RFPressureSensorDiagnosis : 37|2@0+ (1,0) [0|3] "" THU
SG_ BCM_LRPressureSensorDiagnosis : 39|2@0+ (1,0) [0|3] "" THU
SG_ BCM_RRPressureSensorDiagnosis : 41|2@0+ (1,0) [0|3] "" THU
SG_ BCM_LFPressureNotLearn : 42|1@0+ (1,0) [0|1] "" THU
SG_ BCM_RFPressureNotLearn : 43|1@0+ (1,0) [0|1] "" THU
SG_ BCM_LRPressureNotLearn : 44|1@0+ (1,0) [0|1] "" THU
SG_ BCM_RRPressureNotLearn : 45|1@0+ (1,0) [0|1] "" THU
SG_ BCM_LFPressureSensorLowPower : 46|1@0+ (1,0) [0|1] "" THU
SG_ BCM_RFPressureSensorLowPower : 47|1@0+ (1,0) [0|1] "" THU
SG_ BCM_LRPressureSensorLowPower : 48|1@0+ (1,0) [0|1] "" THU
SG_ BCM_RRPressureSensorLowPower : 49|1@0+ (1,0) [0|1] "" THU

BO_ 889 BDCR_SRF_379: 8 BDCR
SG_ Sunshade_SwitchError : 0|1@0+ (1,0) [0|1] "" BDCF
SG_ Sunshade_ECUError : 1|1@0+ (1,0) [0|1] "" BDCF
SG_ Sunshade_HallError : 2|1@0+ (1,0) [0|1] "" BDCF
SG_ Sunshade_ThermalProtection : 3|1@0+ (1,0) [0|1] "" BDCF
SG_ Sunshade_OverVoltage : 4|1@0+ (1,0) [0|1] "" BDCF
SG_ Sunshade_UnderVoltage : 5|1@0+ (1,0) [0|1] "" BDCF
SG_ Sunshade_RelayError : 6|1@0+ (1,0) [0|1] "" BDCF
SG_ Sunshade_TimeoutStatus : 7|1@0+ (1,0) [0|1] "" BDCF
SG_ Sunshade_PositionCount : 15|16@0+ (1,0) [0|65535] "" BDCF
SG_ Sunshade_MovementStatus : 26|3@0+ (1,0) [0|7] "" BDCF
SG_ Sunshade_Switch : 31|5@0+ (1,0) [0|31] "" BDCF
SG_ Sunshade_Initialized : 32|1@0+ (1,0) [0|1] "" BDCF
SG_ Sunshade_TeachRun : 33|1@0+ (1,0) [0|1] "" BDCF
SG_ Sunshade_Status : 35|2@0+ (1,0) [0|3] "" BDCF
SG_ Sunshade_APActive : 36|1@0+ (1,0) [0|1] "" BDCF
SG_ Sunshade_Position : 39|3@0+ (1,0) [0|7] "" BDCF
SG_ Sunshade_MasterSlave : 47|8@0+ (1,0) [0|255] "" BDCF
SG_ Sunshade_POS_VIT_FL : 54|7@0+ (1,0) [0|100] "%" BDCF
SG_ Sunshade_MasterSlave2 : 59|4@0+ (1,0) [0|15] "" BDCF
SG_ Sunshade_MotorStallStatus : 60|1@0+ (1,0) [0|1] "" BDCF
SG_ Sunshade_PinchEventStatus : 61|1@0+ (1,0) [0|1] "" BDCF
SG_ Sunshade_PinchPlayModeStatus : 62|1@0+ (1,0) [0|1] "" BDCF

BO_ 890 BDCR_SRF_37A: 8 BDCR
SG_ Sunroof_Initialized : 0|1@0+ (1,0) [0|1] "" BDCF
SG_ Sunroof_Status : 2|2@0+ (1,0) [0|3] "" BDCF
SG_ Sunroof_APActive : 3|1@0+ (1,0) [0|1] "" BDCF
SG_ BDCR_ECUError : 4|1@0+ (1,0) [0|1] "" BDCF
SG_ Sunroof_SwitchError : 5|1@0+ (1,0) [0|1] "" BDCF
SG_ Sunroof_HallError : 6|1@0+ (1,0) [0|1] "" BDCF
SG_ Sunroof_TimeoutStatus : 7|1@0+ (1,0) [0|1] "" BDCF
SG_ Sunroof_POS_VIT : 14|7@0+ (1,0) [0|100] "%"  BDCF,THU
SG_ Sunroof_POS_Direction : 15|1@0+ (1,0) [0|1] "" BDCF
SG_ Sunroof_PositionCount : 23|16@0+ (1,0) [0|65535] "" BDCF
SG_ Sunroof_MovementStatus : 35|4@0+ (1,0) [0|15] "" BDCF
SG_ Sunroof_Switch : 39|4@0+ (1,0) [0|15] "" BDCF
SG_ Sunroof_ThermalProtection : 40|1@0+ (1,0) [0|1] "" BDCF
SG_ Sunroof_SsInitializing : 41|1@0+ (1,0) [0|1] "" BDCF
SG_ Sunroof_TeachRun : 42|1@0+ (1,0) [0|1] "" BDCF
SG_ Sunroof_OverVoltage : 43|1@0+ (1,0) [0|1] "" BDCF
SG_ Sunroof_UnderVoltage : 44|1@0+ (1,0) [0|1] "" BDCF
SG_ Sunroof_RelayError : 45|1@0+ (1,0) [0|1] "" BDCF
SG_ Sun_InitializedResult : 46|1@0+ (1,0) [0|1] "" BDCF
SG_ Sunroof_PinchPlayModeStatus : 47|1@0+ (1,0) [0|1] "" BDCF
SG_ Sunroof_Position : 50|3@0+ (1,0) [0|7] "" BDCF
SG_ Sun_InitializedFailReason : 53|3@0+ (1,0) [0|7] "" BDCF
SG_ Sunroof_PinchEventStatus : 54|1@0+ (1,0) [0|1] "" BDCF
SG_ Sunroof_MotorStallStatus : 55|1@0+ (1,0) [0|1] "" BDCF
SG_ Sunroof_MasterSlave : 63|8@0+ (1,0) [0|255] "" BDCF

BO_ 887 BCM_377: 4 BDCF
SG_ RFDOOR_ALCStatus : 1|2@0+ (1,0) [0|3] "" THU,HU
SG_ RFDOOR_ALCColorStatusFeedback : 14|7@0+ (1,0) [0|127] "" THU,HU
SG_ RFDOOR_ALCBrightnessStatusFeedback : 5|4@0+ (1,0) [0|15] "" THU,HU

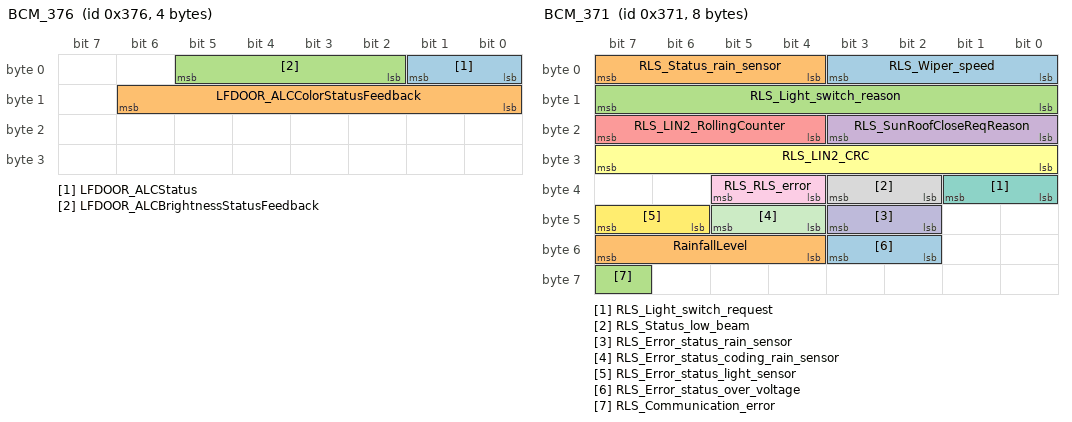
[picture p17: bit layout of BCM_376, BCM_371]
BO_ 886 BCM_376: 4 BDCF
SG_ LFDOOR_ALCStatus : 1|2@0+ (1,0) [0|3] "" THU,HU
SG_ LFDOOR_ALCColorStatusFeedback : 14|7@0+ (1,0) [0|127] "" THU,HU
SG_ LFDOOR_ALCBrightnessStatusFeedback : 5|4@0+ (1,0) [0|15] "" THU,HU

BO_ 885 BCM_375: 4 BDCF
SG_ InstrumentPanel_MiddleALCStatus : 1|2@0+ (1,0) [0|3] "" THU,HU
SG_ InstrumentPanel_MiddleALCColorStatusFeedback : 14|7@0+ (1,0) [0|127] "" THU,HU
SG_ InstrumentPanel_MiddleALCBrightnessStatusFeedback : 5|4@0+ (1,0) [0|15] "" THU,HU

BO_ 884 BCM_374: 4 BDCF
 SG_ InstrumentPanel_RightALCStatus : 1|2@0+ (1,0) [0|3] "" THU,HU
 SG_ InstrumentPanel_RightALCColorStatusFeedback : 14|7@0+ (1,0) [0|127] "" THU,HU
 SG_ InstrumentPanel_RightALCBrightnessStatusFeedback : 5|4@0+ (1,0) [0|15] "" THU,HU

BO_ 883 BCM_373: 4 BDCF
SG_ InstrumentPanel_LeftALCStatus : 1|2@0+ (1,0) [0|3] "" THU,HU
SG_ InstrumentPanel_LeftALCColorStatusFeedback : 14|7@0+ (1,0) [0|127] "" THU,HU
SG_ InstrumentPanel_LeftALCBrightnessStatusFeedback : 5|4@0+ (1,0) [0|15] "" THU,HU

BO_ 881 BCM_371: 8 BDCF
SG_ RLS_Wiper_speed : 3|4@0+ (2,33) [0|15] "wiper_strokes/min" Vector__XXX
SG_ RLS_Status_rain_sensor : 7|4@0+ (1,0) [0|15] "" Vector__XXX
SG_ RLS_Light_switch_reason : 15|8@0+ (1,0) [0|255] "" Vector__XXX
SG_ RLS_SunRoofCloseReqReason : 19|4@0+ (1,0) [0|7] "" Vector__XXX
SG_ RLS_LIN2_RollingCounter : 23|4@0+ (1,0) [0|15] "" Vector__XXX
SG_ RLS_LIN2_CRC : 31|8@0+ (1,0) [0|255] "" Vector__XXX
SG_ RLS_Light_switch_request : 33|2@0+ (1,0) [0|3] "" Vector__XXX
SG_ RLS_Status_low_beam : 35|2@0+ (1,0) [0|3] "" Vector__XXX
SG_ RLS_RLS_error : 37|2@0+ (1,0) [0|3] "" Vector__XXX
SG_ RLS_Error_status_rain_sensor : 43|2@0+ (1,0) [0|3] "" Vector__XXX
SG_ RLS_Error_status_coding_rain_sensor : 45|2@0+ (1,0) [0|3] "" Vector__XXX
SG_ RLS_Error_status_light_sensor : 47|2@0+ (1,0) [0|3] "" Vector__XXX
SG_ RLS_Error_status_over_voltage : 51|2@0+ (1,0) [0|3] "" Vector__XXX
SG_ RainfallLevel : 55|4@0+ (1,0) [0|15] "" Vector__XXX
SG_ RLS_Communication_error : 63|1@0+ (1,0) [0|1] "" Vector__XXX

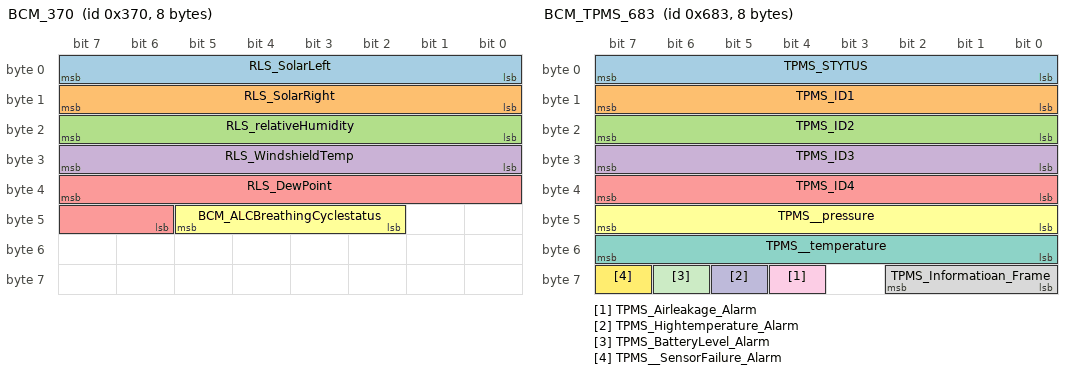
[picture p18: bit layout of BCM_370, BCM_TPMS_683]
BO_ 880 BCM_370: 8 BDCF
SG_ RLS_SolarLeft : 7|8@0+ (5,0) [0|1200] "w/m2" THU,IP,ARHUD
SG_ RLS_SolarRight : 15|8@0+ (5,0) [0|1200] "w/m2" THU,IP,ARHUD
SG_ RLS_relativeHumidity : 23|8@0+ (0.5,-0.5) [0|100] "%" Vector__XXX
SG_ RLS_WindshieldTemp : 31|8@0+ (0.5,-40) [-40|87] "℃" Vector__XXX
SG_ RLS_DewPoint : 39|10@0+ (0.1,-39.6) [-39.6|60.4] "℃" Vector__XXX
 SG_ BCM_ALCBreathingCyclestatus : 45|4@0+ (1,0) [0|15] ""  THU

BO_ 1668 BCM_TPMS_684: 8 BDCF
SG_ TPMS_checksum : 7|8@0+ (1,0) [0|255] "" Vector__XXX

BO_ 1667 BCM_TPMS_683: 8 BDCF
SG_ TPMS_STYTUS : 7|8@0+ (1,0) [0|255] "" Vector__XXX
SG_ TPMS_ID1 : 15|8@0+ (1,0) [0|255] "" Vector__XXX
SG_ TPMS_ID2 : 23|8@0+ (1,0) [0|255] "" Vector__XXX
SG_ TPMS_ID3 : 31|8@0+ (1,0) [0|255] "" Vector__XXX
SG_ TPMS_ID4 : 39|8@0+ (1,0) [0|255] "" Vector__XXX
SG_ TPMS__pressure : 47|8@0+ (1,0) [0|255] "" Vector__XXX
SG_ TPMS__temperature : 55|8@0+ (1,0) [0|255] "" Vector__XXX
SG_ TPMS_Informatioan_Frame : 58|3@0+ (1,0) [0|7] "" Vector__XXX
SG_ TPMS_Airleakage_Alarm : 60|1@0+ (1,0) [0|1] "" Vector__XXX
SG_ TPMS_Hightemperature_Alarm : 61|1@0+ (1,0) [0|1] "" Vector__XXX
SG_ TPMS_BatteryLevel_Alarm : 62|1@0+ (1,0) [0|1] "" Vector__XXX
SG_ TPMS__SensorFailure_Alarm : 63|1@0+ (1,0) [0|1] "" Vector__XXX

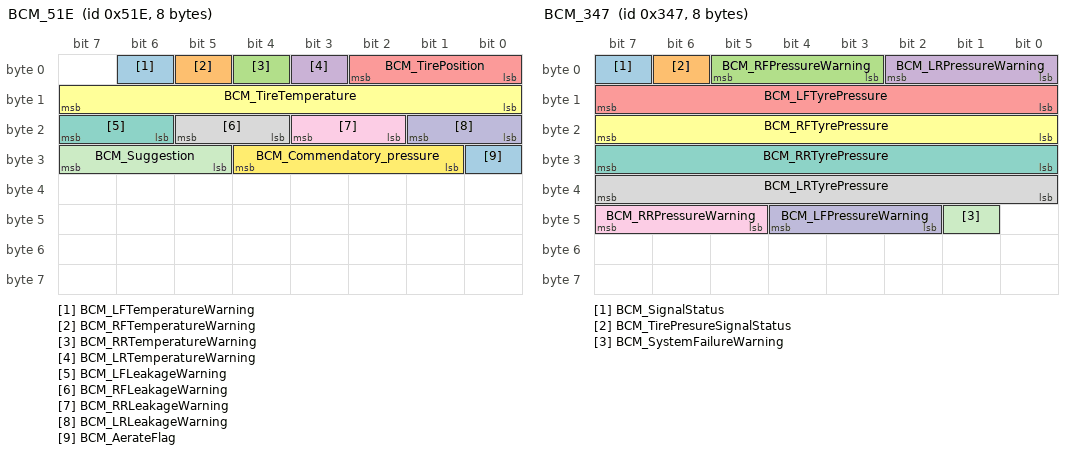
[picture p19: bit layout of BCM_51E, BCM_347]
BO_ 1310 BCM_51E: 8 BDCF
SG_ BCM_LFTemperatureWarning : 6|1@0+ (1,0) [0|1] "" THU,HU,IP
SG_ BCM_RFTemperatureWarning : 5|1@0+ (1,0) [0|1] "" THU,HU,IP
SG_ BCM_RRTemperatureWarning : 4|1@0+ (1,0) [0|1] "" THU,HU,IP
SG_ BCM_LRTemperatureWarning : 3|1@0+ (1,0) [0|1] "" THU,HU,IP
SG_ BCM_TirePosition : 2|3@0+ (1,0) [0|3] "" THU,HU,IP
SG_ BCM_TireTemperature : 15|8@0+ (1,-40) [-40|214] "°C" THU,HU,IP
SG_ BCM_LFLeakageWarning : 23|2@0+ (1,0) [0|3] "" THU,IP
SG_ BCM_RFLeakageWarning : 21|2@0+ (1,0) [0|3] "" THU,IP
SG_ BCM_RRLeakageWarning : 19|2@0+ (1,0) [0|3] "" THU,IP
SG_ BCM_LRLeakageWarning : 17|2@0+ (1,0) [0|3] "" THU,IP
SG_ BCM_Suggestion : 31|3@0+ (1,0) [0|7] "" THU,IP
SG_ BCM_Commendatory_pressure : 28|4@0+ (1,0) [0|15] "" THU,IP
SG_ BCM_AerateFlag : 24|1@0+ (1,0) [0|1] "" IP

BO_ 839 BCM_347: 8 BDCF
SG_ BCM_SignalStatus : 7|1@0+ (1,0) [0|1] "" THU,HU,IP
SG_ BCM_TirePresureSignalStatus : 6|1@0+ (1,0) [0|1] "" THU,HU,IP
SG_ BCM_RFPressureWarning : 5|3@0+ (1,0) [0|7] "" THU,HU,IP
SG_ BCM_LRPressureWarning : 2|3@0+ (1,0) [0|7] "" THU,HU,IP
SG_ BCM_LFTyrePressure : 15|8@0+ (1.373,0) [0|350] "KPa" THU,HU,IP
SG_ BCM_RFTyrePressure : 23|8@0+ (1.373,0) [0|350] "KPa" THU,HU,IP
SG_ BCM_RRTyrePressure : 31|8@0+ (1.373,0) [0|350] "KPa" THU,HU,IP
SG_ BCM_LRTyrePressure : 39|8@0+ (1.373,0) [0|350] "KPa" THU,HU,IP
SG_ BCM_RRPressureWarning : 47|3@0+ (1,0) [0|7] "" THU,HU,IP
SG_ BCM_LFPressureWarning : 44|3@0+ (1,0) [0|7] "" THU,HU,IP
SG_ BCM_SystemFailureWarning : 41|1@0+ (1,0) [0|1] "" THU,HU,IP

BO_ 664 BCM_298: 8 BDCF
 SG_ PEPS_TrunkRequestSignal : 7|1@0+ (1,0) [0|1] "" THU
 SG_ PEPS_KeyLearningSignal : 6|2@0+ (1,0) [0|3] "" THU,IP
 SG_ PEPS_EasyOpenOrginalSignal : 4|1@0+ (1,0) [0|1] "" Vector__XXX
 SG_ PEPS_RemoteFailedAlarmSignal : 3|1@0+ (1,0) [0|1] "" THU,IP
 SG_ PEPS_SearchCarSignal : 2|1@0+ (1,0) [0|1] "" Vector__XXX
 SG_ PEPS_LuggageUnlockSignal : 1|2@0+ (1,0) [0|3] "" THU,PLG,BDCR
 SG_ PEPS_KeyNumber : 15|3@0+ (1,0) [0|7] "" Vector__XXX
 SG_ PEPS_KeyAuthenticationStatus : 12|2@0+ (1,0) [0|3] "" Vector__XXX
 SG_ PEPS_Easy_open : 10|1@0+ (1,0) [0|1] "" PLG
 SG_ PEPS_Welcomelamp_Detonate : 9|2@0+ (1,0) [0|3] "" THU
 SG_ PEPS_SmartTrunkUlockRemind : 23|2@0+ (1,0) [0|3] "" Vector__XXX
 SG_ PEPS_UnlockSignal : 21|2@0+ (1,0) [0|3] "" THU
 SG_ PEPS_WLCM_Enable : 19|2@0+ (1,0) [0|3] "" THU,WLCM
 SG_ PEPS_LockSignal : 17|2@0+ (1,0) [0|3] "" THU,IP,ESCL
 SG_ PEPS_SmartUnlockSignal : 29|3@0+ (1,0) [0|7] "" Vector__XXX
 SG_ PEPS_SmartLockSignal : 26|3@0+ (1,0) [0|7] "" Vector__XXX
 SG_ PEPS_LockKeyStatus : 31|2@0+ (1,0) [0|3] "" Vector__XXX
 SG_ BCM_TrunkStatus : 39|1@0+ (1,0) [0|1] "" THU,HU,IP,BDCR
 SG_ BCM_RightRearDoorStatus : 38|1@0+ (1,0) [0|1] "" THU,HU,IP,BDCR
 SG_ BCM_BreathingLightSet_FeedBack : 37|2@0+ (1,0) [0|3] "" THU
 SG_ PEPS_TrunkKeyStatus : 35|2@0+ (1,0) [0|3] "" Vector__XXX
 SG_ PEPS_UnLockKeyStatus : 33|2@0+ (1,0) [0|3] "" Vector__XXX
 SG_ BCM_PassengerDoorStatus : 45|1@0+ (1,0) [0|1] "" THU,HU,IP,BDCR
 SG_ BCM_DriverDoorLockStatus : 44|2@0+ (1,0) [0|3] "" THU,FIS,PLG
 SG_ BCM_PassengerDoorLockStatus : 42|2@0+ (1,0) [0|3] "" THU,FIS
 SG_ BCM_LeftRearDoorStatus : 40|1@0+ (1,0) [0|1] "" THU,HU,IP,FIS,BDCR
 SG_ BCM_LockandUnlockFeedback : 51|6@0+ (1,0) [0|52] "" THU,HU,FIS
 SG_ BCM_WindowElectricInspectionSign : 61|1@0+ (1,0) [0|1] "" THU,HU
 SG_ PEPS_RemoteStartKeyStatus : 47|2@0+ (1,0) [0|3] ""  THU

CM_ SG_ 884 ACC_CRCCheck_374 "ACC_374校验和";
CM_ SG_ 884 ACC_RollingCounter_374 "ACC_374计数器";
CM_ SG_ 884 ADS_RemoteRoadShapeC2 "远端道路形状参数C2";
CM_ SG_ 884 ADS_RemoteRoadShapeC1 "远端道路形状参数C1";
CM_ SG_ 884 ADS_RightPedWarnLevel "右侧行人目标报警级别";
CM_ SG_ 884 ADS_TSRHostNextSpdLimitDist "前方限速变化点距离";
CM_ SG_ 884 ADS_TSRHostNextSpdLimit "前方变更点后限速值";
CM_ SG_ 884 ADS_RightPedDetection "右侧行人目标识别结果";
CM_ SG_ 884 ADS_LeftPedWarnLevel "左侧行人目标报警级别";
CM_ SG_ 884 ADS_LeftPedDetection "左侧行人目标识别结果";
CM_ SG_ 884 ADS_HostPedWarnLevel_1 "本车道行人目标1报警级别";
CM_ SG_ 407 ESP_CRCCheck_197 "ESP_197校验和";
CM_ SG_ 407 ESP_RollingCounter_197 "ESP_197计数器";
CM_ SG_ 407 ESP_SASOffSet "转向角度补偿值";
CM_ SG_ 407 EPB_AchievedClampForce "EPB夹紧力";
CM_ SG_ 407 EPB_Status "EPB状态";
CM_ SG_ 407 EPB_ClutchSensor "离合器行程开关";
CM_ SG_ 407 EPB_APArequest_Available "APA请求拉EPB可用";
CM_ SG_ 407 EPB_SwitchPosition "EPB开关位置";
CM_ SG_ 407 EPB_FaultStoredInfo "EPB故障存储信息";
CM_ SG_ 407 EPB_FailStatus "EPB故障状态";
CM_ SG_ 391 ESP_CRCCheck_187 "ESP_187校验和";
CM_ SG_ 391 ESP_RollingCounter_187 "ESP_187计数器";
CM_ SG_ 391 ESP_ADBF_Active "ADBF功能的可行性";
CM_ SG_ 391 ESP_VehicleSpeed "车速信号";
CM_ SG_ 391 ESP_EngTorqIncActive "增扭有效标志位";
CM_ SG_ 391 ESP_EngTorqDecActive "降扭有效标志位";
CM_ SG_ 391 ESP_EngTorqInc "增扭请求";
CM_ SG_ 391 ESP_EngTorqDecSlow "慢速减扭请求";
CM_ SG_ 391 ESP_EngTorqDecFast "快速减扭请求";
CM_ SG_ 391 ESP_ESPActiveStatus "ESP工作状态";
CM_ SG_ 391 ESP_ESPFunctionStatus "ESP功能开启状态";
CM_ SG_ 391 ESP_EBDFailStatus "EBD故障";
CM_ SG_ 391 ESP_ABSFailStatus "ABS故障";
CM_ SG_ 391 ESP_TCSFailStatus "TCS/ESP故障";
CM_ SG_ 391 ESP_GearHoldRequestValid "TCS换档禁止请求有效";
CM_ SG_ 391 ESP_GearHoldRequest "TCS换档禁止请求";
CM_ SG_ 391 ESP_ABSActiveStatus "ABS工作状态";
CM_ SG_ 384 SAS_CRCCheck "SAS_180校验和";
CM_ SG_ 384 SAS_RollingCounter "转角报文计数信号";
CM_ SG_ 384 SAS_Calibrated "SAS标定状态";
CM_ SG_ 384 SAS_SASFailure "转角传感器失效";
CM_ SG_ 384 SAS_SteeringAngleValid "转向角度失效信号";
CM_ SG_ 384 SAS_SteeringAngleSpeed "转角速度";
CM_ SG_ 384 SAS_SteeringAngle "转向角度";
CM_ SG_ 591 EPS_CRCCheck_24F "EPS_24F校验和";
CM_ SG_ 591 EPS_RollingCounter_24F "EPS_24F计数器";
CM_ SG_ 591 EPS_ConcussAvailabilityStatus "方向盘震动状态";
CM_ SG_ 591 EPS_TorqueAssistMode "EPS当前助力模式反馈";
CM_ SG_ 591 EPS__IACC_abortreason "IACC控制中断反馈";
CM_ SG_ 591 EPS_APA_ControlFeedback "APA请求转向控制反馈";
CM_ SG_ 591 EPS_SteeringTorque "转向力矩";
CM_ SG_ 591 EPS_TorqSensorStatus "力矩传感器状态";
CM_ SG_ 591 EPS_APA_EpasFAILED "EPS临时故障";
CM_ SG_ 591 EPS_ModeSwitchSt "EPS助力模式切换状态";
CM_ SG_ 591 EPS_APA_Abortfeedback "APA控制中断反馈";
CM_ SG_ 591 EPS_EPSFailed "助力转向故障位";
CM_ SG_ 591 EPS_ElectPowerConsumption "助力转向电流消耗";
CM_ SG_ 382 EPS_CRCCheck_17E "EPS_17E校验和";
CM_ SG_ 382 EPS_RollingCounter_17E "EPS_17E计数器";
CM_ SG_ 382 EPS_LatCtrlAvailabilityStatus "EPS横向控制可用状态";
CM_ SG_ 382 EPS_LatCtrlActive "EPS横向控制激活";
CM_ SG_ 382 EPS_MeasuredTorsionBarTorqValid "驾驶员手力矩验证位";
CM_ SG_ 382 EPS_MeasuredTorsionBarTorque "驾驶员手力矩";
CM_ SG_ 368 EPS_CRCCheck_170 "EPS_170校验和";
CM_ SG_ 368 EPS_RollingCounter_170 "EPS_170计数器";
CM_ SG_ 368 EPS_ActualTorsionBarTorq "EPS实际扭杆扭矩";
CM_ SG_ 368 EPS_MinSafetyTorsionBarTorq "EPS功能安全限定的最小扭杆扭矩";
CM_ SG_ 368 EPS_MaxSafetyTorsionBarTorq "EPS功能安全限定的最大扭杆扭矩";
CM_ SG_ 586 ESL_CRCCheck_24A "ESL_24A校验和";
CM_ SG_ 586 ESL_RollingCounter_24A "ESL_24A计数器";
CM_ SG_ 586 ESL_UnLockButtonStatus "解锁按钮信号有效状态";
CM_ SG_ 586 ESL_DriverParkButtonStatus "P挡开关故障状态";
CM_ SG_ 586 ESL_DriveModeStatus "驾驶模式故障状态";
CM_ SG_ 586 ESL_ShiftLeverStatus "电子换挡器状态";
CM_ SG_ 586 ESL_DriverParkRequest "驾驶员P档请求";
CM_ SG_ 586 ESL_DriveModePosition "驾驶模式";
CM_ SG_ 586 ESL_UnLockButtonPosition "解锁按钮状态";
CM_ SG_ 586 ESL_ShiftLeverPositon "电子换挡器挡位请求";
CM_ SG_ 585 ACM_CRCCheck_249 "ACM_249校验和";
CM_ SG_ 585 ACM_RollingCounter_249 "ACM_249计数器";
CM_ SG_ 585 ACM_ParkSelectIPReq "不满足入P条件提示";
CM_ SG_ 585 ACM_NotMatchMPosnIPReq "换挡器在M位置出提示";
CM_ SG_ 585 ACM_ShifterGearAPosnIPReq "换挡器在A位置出提示";
CM_ SG_ 585 ACM_EngStartIPReq "不满足启动操作条件提示";
CM_ SG_ 585 ACM_ESLFaultIPReq "ESL故障显示需求";
CM_ SG_ 585 ACM_ARCFaultIPReq "ACM故障显示需求";
CM_ SG_ 585 ACM_DriveShiftRequst "驾驶员挡位请求";
CM_ SG_ 585 ACM_APAdriverInterruption "驾驶员干预换挡";
CM_ SG_ 585 ACM_APA_Request_Enable "APA控制使能";
CM_ SG_ 585 ACM_ACMActuatorStatus "ACM与执行机构状态";
CM_ SG_ 585 ACM_ActuatorPRNDStatus "执行机构PRND状态";
CM_ SG_ 585 ACM_ActuatorPOrNoPStatus "执行机构状态";
CM_ SG_ 509 TCU_CrankingAuthEnable "离合器允许发动机启动";
CM_ SG_ 824 TCU_CRCCheck_338 "TCU_338校验和";
CM_ SG_ 824 TCU_RollingCounter_338 "TCU_338计数器";
CM_ SG_ 824 TCU_DriveMode "TCU驾驶模式";
CM_ SG_ 824 TCU_ARCFaultIPReq "执行机构发生故障时，对仪表的显示需求(包括Limphome，在P挡卡滞、在非P挡卡滞、在P与非P之间卡滞)";
CM_ SG_ 824 TCU_ESLFaultIPReq "换挡器存在故障时，对仪表的显示请求。";
CM_ SG_ 824 TCU_ParkSelectIPReq "不满足入P条件的文本对话框提醒/The_warning_text_that_unsatisfy_engagement_park_condition";
CM_ SG_ 824 TCU_ParkRelMPosnIPReq "换挡器在M位置出P的文本对话框提醒/The_warning_text_when_release_park_at__M_positon";
CM_ SG_ 824 TCU_ParkRelAPosnIPReq "换挡器在A位置出P的文本对话框提醒/The_warning_text_when_release_park_at__Auto_positon";
CM_ SG_ 824 TCU_EngStartIPReq "不满足启动操作条件的文本对话框提醒/The_warning_text_that_unsatisfy_the_start_operation_condition";
CM_ SG_ 824 TCU_BuzzerReq "蜂鸣器";
CM_ SG_ 824 TCU_GearIndication "档位显示方式";
CM_ SG_ 824 TCU_GearForDisplay "档位显示";
CM_ SG_ 824 TCU_SlopeRatio "坡度";
CM_ SG_ 824 TCU_TransFluidTemp "传动液温度";
CM_ SG_ 824 TCU_ClearDiagnosticInfo "清故障信息";
CM_ SG_ 824 TCU_LinePressureFailureStatus "DCT变速器主压状态";
CM_ SG_ 824 TCU_ShiftMapID "TCU换挡图谱";
CM_ SG_ 824 TCU_FanRequest "风扇请求";
CM_ SG_ 824 TCU_BrakeAssistRequestValid "制动辅助请求有效";
CM_ SG_ 824 TCU_BrakeAssistRequest "制动辅助请求";
CM_ SG_ 824 TCU_ReqTranTempWarning "TCU请求仪表显示油温信息";
CM_ SG_ 824 TCU_FailureLamp "故障指示灯";
CM_ SG_ 824 TCU_CompressorDisableReq "压缩机禁止请求";
CM_ SG_ 588 TCU_CRCCheck_24C "TCU_24C校验和";
CM_ SG_ 588 TCU_RollingCounter_24C "TCU_24C计数器";
CM_ SG_ 588 TCU_ClutchBFillStatus "离合器B充油状态";
CM_ SG_ 588 TCU_ClutchAFillStatus "离合器A充油状态";
CM_ SG_ 588 TCU_HeavyDecelerationFlag "急减速标志";
CM_ SG_ 588 TCU_NeutralControl "空挡控制标志";
CM_ SG_ 588 TCU_ReverseControl "倒挡控制标志";
CM_ SG_ 588 TCU_VehicleSpeedDirection "车速方向";
CM_ SG_ 588 TCU_ShaftPiercingTrigger "穿轴使能";
CM_ SG_ 588 TCU_APAClutchCtrlRequestEnable "APA滑摩请求使能";
CM_ SG_ 588 TCU_APAShiftGearRequestEnable "APA换挡控制使能";
CM_ SG_ 588 TCU_InputSpeedB "输入轴B转速";
CM_ SG_ 588 TCU_InputSpeedA "输入轴A转速";
CM_ SG_ 588 TCU_FrictiolTorqueLoss "TCU摩擦扭矩损耗";
CM_ SG_ 438 TCU_CRCCheck_1B6 "TCU_1B6校验和";
CM_ SG_ 438 TCU_RollingCounter_1B6 "TCU_1B6计数器";
CM_ SG_ 438 TCU_ClutchStatus "离合器状态";
CM_ SG_ 438 TCU_ParkingRequest "P挡请求信号";
CM_ SG_ 438 TCU_CreepingEnable "爬行开始标志";
CM_ SG_ 438 TCU_CreepingClutchTorq "爬行加载在离合器上的扭矩";
CM_ SG_ 438 TCU_EngineSpeedReqType "TCU转速请求模式";
CM_ SG_ 438 TCU_EngSpdSyncTime "发动机转速同步时间";
CM_ SG_ 438 TCU_ClutchActualTorque "离合器实际扭矩";
CM_ SG_ 438 TCU_EngineSpeedReq "TCU转速请求";
CM_ SG_ 438 TCU_TorqRateLimitValue "发动机扭矩斜率限制值";
CM_ SG_ 424 TCU_CRCCheck_1A8 "TCU_1A8校验和";
CM_ SG_ 424 TCU_RollingCounter_1A8 "TCU_1A8计数器";
CM_ SG_ 424 TCU_TurbineSpeed "涡轮转速";
CM_ SG_ 424 TCU_EPBRequest "TCU对EPB请求";
CM_ SG_ 424 TCU_VehicleSpeed "车速信号";
CM_ SG_ 424 TCU_GearShiftPosition "换挡器位置";
CM_ SG_ 424 TCU_ShiftPositionValid "换挡器位置有效";
CM_ SG_ 424 TCU_ActualGear "实际档位";
CM_ SG_ 424 TCU_TargetGear "目标档位";
CM_ SG_ 424 TCU_STLKfailure "STLK故障";
CM_ SG_ 424 TCU_MILReqStatus "MIL灯请求";
CM_ SG_ 424 TCU_TransFailureStatus "变速箱故障状态";
CM_ SG_ 392 TCU_CRCCheck_188 "TCU_188校验和";
CM_ SG_ 392 TCU_RollingCounter_188 "TCU_188计数器";
CM_ SG_ 392 TCU_StopStartInhibit "禁止起停信号";
CM_ SG_ 392 TCU_ReadyForAutoStop "准备好自动停机信号";
CM_ SG_ 392 TCU_OpenPowertrain "传动链断开信号";
CM_ SG_ 392 TCU_TorLimitationReq "扭矩限制请求";
CM_ SG_ 392 TCU_EngineTorqueReq "请求发动机目标指示扭矩";
CM_ SG_ 392 TCU_TorqRateLimitType "发动机扭矩斜率限制类型";
CM_ SG_ 392 TCU_TCUClutchStatus "液力变矩器状态";
CM_ SG_ 392 TCU_ShiftinProgressValid "换挡过程状态有效";
CM_ SG_ 392 TCU_ShiftinProgress "换挡过程状态";
CM_ SG_ 392 TCU_TorqueReqmodel "AT扭矩请求模式";
CM_ SG_ 853 EMS_CRCCheck_355 "EMS_355校验和";
CM_ SG_ 853 EMS_EngineType "发动机类型";
CM_ SG_ 853 EMS_RollingCounter_355 "EMS_355计数器";
CM_ SG_ 853 EMS_TargetCruiseSpeed "巡航目标车速";
CM_ SG_ 853 EMS_FuelConsumption "100ms油耗";
CM_ SG_ 853 EMS_DriveMode "发动机驾驶模式";
CM_ SG_ 853 EMS_CruiseControlStatus_355 "巡航控制状态";
CM_ SG_ 853 EMS_AgsErrorStateDisplay "主动进气格栅故障状态";
CM_ SG_ 853 EMS_ClearDiagnosticInfo "清除诊断信息";
CM_ SG_ 853 EMS_RemindShiftGear "换档提示";
CM_ SG_ 853 EMS_GPF_State "GPF再生提示";
CM_ SG_ 853 EMS_TankDoorSts "油箱门未关标志位";
CM_ SG_ 853 EMS_PFCCCondition "永久故障码清除条件";
CM_ SG_ 853 EMS_CruiseSwitchOnOff "ACC使能开关状态";
CM_ SG_ 853 EMS_CruiseSwitchResume "ACC的RESUME开关状态";
CM_ SG_ 853 EMS_CruiseSwitchCANCEL "ACC的CANCEL开关状态";
CM_ SG_ 853 EMS_CruiseSwitchSET "ACC的SET开关状态";
CM_ SG_ 853 EMS_CruiseDistance "ACC巡航距离开关状态";
CM_ SG_ 853 EMS_StartPrompt "启动提示";
CM_ SG_ 853 EMS_SVS "SVS指示灯";
CM_ SG_ 853 EMS_MIL "MIL指示灯";
CM_ SG_ 853 EMS_CruiseIndicate "巡航指示灯";
CM_ SG_ 853 EMS_IdleStopStatus "怠速停机状态信号";
CM_ SG_ 853 EMS_CruiseUnavailDisplay "巡航条件不满足显示";
CM_ SG_ 853 EMS_SSMWarningLampCtrol "起停系统警告灯控制";
CM_ SG_ 853 EMS_CruiseActiveIndicate "巡航激活指示灯";
CM_ SG_ 837 EMS_CRCCheck_345 "EMS_345校验和";
CM_ SG_ 837 EMS_RollingCounter_345 "EMS_345计数器";
CM_ SG_ 837 EMS_BSGRealTq "48V电机真实扭矩";
CM_ SG_ 837 EMS_Cooling_Fan_Status "冷却风扇工作状态";
CM_ SG_ 837 EMS_BRSTextDsiplay "48V系统文本显示";
CM_ SG_ 837 EMS_BSGDrivingMode "电机助力模式";
CM_ SG_ 837 EMS_BRSSysEgyFlow "48V系统能量流显示";
CM_ SG_ 837 EMS_BRSFaultLamp "48V系统故障指示灯";
CM_ SG_ 837 EMS_LiSOCDsp "48V锂电池显示SOC";
CM_ SG_ 776 EMS_CRCCheck_308 "EMS_308校验和";
CM_ SG_ 776 EMS_RollingCounter_308 "EMS_308计数器";
CM_ SG_ 776 EMS_ASLControlStatus "限速控制状态";
CM_ SG_ 776 EMS_ASLExceedTarSpdIndi "超速状态指示";
CM_ SG_ 776 EMS_ASLFaultsWarning "限速故障提醒";
CM_ SG_ 776 EMS_ExhaustValStatus "排气声浪功能状态";
CM_ SG_ 776 EMS_ASLTargetSpeed "限速目标车速";
CM_ SG_ 776 EMS_EngineIntakeAirTemp "进气温度传感器";
CM_ SG_ 776 EMS_Neutralgear "空挡信号";
CM_ SG_ 776 EMS_STTUnavailDisplay "STT不能停机提示信号";
CM_ SG_ 776 EMS_RemindGear "提示目标档位";
CM_ SG_ 776 EMS_IntakeAirTempSensorError "进气温度传感器故障";
CM_ SG_ 776 EMS_EEM_state "发电机状态";
CM_ SG_ 776 EMS_EEMErrorFlag "发电机通讯故障提示信号";
CM_ SG_ 776 EMS_ChrageLightState "充电指示灯控制信号";
CM_ SG_ 776 EMS_OilPressureSts "机油压力报警";
CM_ SG_ 776 EMS_FuelCapLeakDisplay "油箱盖未拧紧提示";
CM_ SG_ 726 EMS_CRCCheck_2D6 "EMS_2D6校验和";
CM_ SG_ 726 EMS_RollingCounter_2D6 "EMS_2D6计数器";
CM_ SG_ 726 EMS_AltitudeFactor "高原系数";
CM_ SG_ 726 EMS_IdleReferenceSpeed "目标怠速";
CM_ SG_ 726 EMS_EngineCoolanTemperature "发动机冷却液温度";
CM_ SG_ 726 EMS_EngineStartupEnd "发动机退出起动";
CM_ SG_ 726 EMS_Ignition_Cycles_Counter "点火计数器";
CM_ SG_ 726 EMS_GeneralDenomStasVD "一般分母计数器有效";
CM_ SG_ 726 EMS_General_Denominator_Status "一般分母计数器";
CM_ SG_ 726 EMS_BatteryVoltage "电源电压";
CM_ SG_ 726 EMS_CoolanTemperatureError "发动机冷却液温度故障";
CM_ SG_ 726 EMS_ImmoConfiguration "IMMO配置";
CM_ SG_ 726 EMS_ImmoFeedback "IMMO认证反馈";
CM_ SG_ 726 EMS_EngineLimpHome "跛行状态";
CM_ SG_ 726 EMS_DrivingCycle "驾驶循环";
CM_ SG_ 726 EMS_WarmUpCycle "暖机循环";
CM_ SG_ 726 EMS_CatalystWarmUp "催化剂加热请求";
CM_ SG_ 618 EMS_CRCCheck_26A "EMS_26A校验和";
CM_ SG_ 618 EMS_RollingCounter_26A "EMS_26A计数器";
CM_ SG_ 618 EMS_VacuumPressureValid "真空度压力有效标志";
CM_ SG_ 618 EMS_ConditionIdle "怠速状态";
CM_ SG_ 618 EMS_VacuumPressure "真空度压力";
CM_ SG_ 618 EMS_EngineStatusWithSTT "发动机怠速起停状态";
CM_ SG_ 618 EMS_CompressorStatus "压缩机状态";
CM_ SG_ 618 EMS_KickDown "Kick_down开关";
CM_ SG_ 618 EMS_CompressorWoE "压缩机许可信号";
CM_ SG_ 618 EMS_EngTorqQualityFlag "发动机扭矩质量标志位";
CM_ SG_ 618 EMS_DriveModeSts "EMS驾驶模式状态";
CM_ SG_ 618 EMS_APAAccPedShieldStatus "加速踏板屏蔽请求状态";
CM_ SG_ 618 EMS_ECGPOvrd "发动机检测到驾驶员油门请求超过ACC油门请求";
CM_ SG_ 618 EMS_QECACC "EMS检测到ACC发出的信息有错误";
CM_ SG_ 618 EMS_AccReqPossible "发动机当前可以响应ACC的扭矩请求";
CM_ SG_ 618 EMS_confirmation_in_sport_mode "电喷进入运动模式确认";
CM_ SG_ 618 EMS_EVPActive "电子真空泵工作状态";
CM_ SG_ 422 EMS_CRCCheck_1A6 "EMS_1A6校验和";
CM_ SG_ 422 EMS_RollingCounter_1A6 "EMS_1A6计数器";
CM_ SG_ 422 EMS_IntakeManifoldPressureValid "进气压力有效";
CM_ SG_ 422 EMS_IGNPosition "点火开关ON位置";
CM_ SG_ 422 EMS_EngineStatus "发动机运行状态";
CM_ SG_ 422 EMS_EngTorqTargetwithoutTCU "不包括TCU扭矩干预请求的发动机扭矩";
CM_ SG_ 422 EMS_MinIndicatedTorq "最小指示扭矩";
CM_ SG_ 422 EMS_MaxIndicatedTorq "最大指示扭矩";
CM_ SG_ 422 EMS_TorqueConstant "扭矩基准值";
CM_ SG_ 422 EMS_PTOpenReq "请求传动链脱开信号";
CM_ SG_ 422 EMS_AutoStopRequest "自动停机请求信号";
CM_ SG_ 422 EMS_CruiseControlStatus "巡航控制状态";
CM_ SG_ 422 EMS_IntakeManifoldPressure "进气歧管压力";
CM_ SG_ 406 EMS_CRCCheck_196 "EMS_196校验和";
CM_ SG_ 406 EMS_RollingCounter_196 "EMS_196计数器";
CM_ SG_ 406 EMS_ClutchPedalStatus "离合器踏板状态";
CM_ SG_ 406 EMS_BrakePedalStatus "制动踏板状态";
CM_ SG_ 406 EMS_AccPedal "加速踏板位置";
CM_ SG_ 406 EMS_EngineThrottlePosition "发动机节气门位置";
CM_ SG_ 406 EMS_APATorqRequestAvailable "发动机当前可以响应APA的扭矩请求";
CM_ SG_ 406 EMS_TCUTorqRequestAvailability "TCU扭矩请求响应";
CM_ SG_ 406 EMS_AccpedelError "加速踏板故障";
CM_ SG_ 406 EMS_ThrottleValvePositionError "节气门位置故障";
CM_ SG_ 406 EMS_EngineSpeed "发动机转速";
CM_ SG_ 406 EMS_ESPTorqRequestAvailability "ESP扭矩请求响应";
CM_ SG_ 406 EMS_EngineFuelCutOff "断油标志";
CM_ SG_ 406 EMS_CreepingInhibitCommand "爬行功能禁止";
CM_ SG_ 406 EMS_RealAccPedal "真实加速踏板位置";
CM_ SG_ 388 EMS_CRCCheck_184 "EMS_184校验和";
CM_ SG_ 388 EMS_RollingCounter_184 "EMS_184计数器";
CM_ SG_ 388 EMS_Torqquality "发动机扭矩质量";
CM_ SG_ 388 EMS_TorqFailure "发动机扭矩失效";
CM_ SG_ 388 EMS_SailingRequest "空挡滑行请求";
CM_ SG_ 388 EMS_IndicatedRealEngTorq "发动机真实扭矩";
CM_ SG_ 388 EMS_FrictionalTorq "摩擦扭矩";
CM_ SG_ 388 EMS_IndicatedDriverReqTorq "驾驶员期望燃烧扭矩";
CM_ SG_ 747 HUD_FollowTargetDisplay_SetSts "跟随目标显示设置反馈";
CM_ SG_ 747 HUDBiasLightSetSts "HUD背景光设置反馈";
CM_ SG_ 747 HUDRearIncomingVehicleSetSts "后方来车提醒设置反馈";
CM_ SG_ 747 HUDMovingTargetDetect_SetSts "移动物体检测设置反馈";
CM_ SG_ 747 HUD_BrightAdjustSts "HUD亮度调节反馈";
CM_ SG_ 747 HUD_DisplayLDWSts "HUD是否显示LDW反馈";
CM_ SG_ 747 HUD_DimAdjustSts "HUD背光调节反馈";
CM_ SG_ 747 HUD_DisplayNavSts "HUD是否显示导航反馈";
CM_ SG_ 747 HUD_DisplayACCSts "HUD是否显示ACC反馈";
CM_ SG_ 747 HUD_HUDEnableSts "HUD功能开启状态";
CM_ SG_ 747 HUD_PosAdjustSts "HUD高度调节反馈";
CM_ SG_ 747 HUD_ReqSendNextRoadName "请求重新发送道路名";
CM_ SG_ 630 ESCL_SteeringLockError "转向锁故障信号";
CM_ SG_ 630 ESCL_SteeringLockStatusS301 "转向锁状态信号";
CM_ SG_ 630 ESCL_SteeringLockWait "转向锁等待信号";
CM_ SG_ 630 ESCL_SteeringLockStuck "转向锁堵转信号";
CM_ SG_ 630 ESCL_SteeringLockStatusB211 "转向锁状态信号";
CM_ SG_ 1020 PLG_CloseSpeedMode "电动背门关闭速度模式";
CM_ SG_ 1020 TrunkStopInstruct "尾门系统暂停指令";
CM_ SG_ 1020 TrunkCloseInstruct "尾门系统关闭指令";
CM_ SG_ 1020 TrunkOpenInstruct "尾门系统打开指令";
CM_ SG_ 1022 Sunroof_IntegrateSwitch "天窗一体式开关状态";
CM_ SG_ 1022 PLG_Pole_RelayError "电吸锁继电器错误";
CM_ SG_ 1022 PLG_OpenHeightLearningFailReason "电动背门开启高度学习失败原因";
CM_ SG_ 1022 PLG_TrunkPositionFeedback "尾门位置设置反馈";
CM_ SG_ 1022 PLG_Pole_HallError "撑杆电机霍尔传感器错误";
CM_ SG_ 1022 PLG_Lock_RelayError "撑杆电机继电器错误";
CM_ SG_ 1022 PLG_PinchTriggerSignal "背门防夹触发信号";
CM_ SG_ 1022 PLG_ShutfaceSwitchError "背门内开关错误";
CM_ SG_ 1022 PLG_OpenCloseSwitchError "主驾驶侧开关错误";
CM_ SG_ 1022 PLG_BuzzerStaus "蜂鸣器状态";
CM_ SG_ 1022 PLG_InitializedFailReason "电动背门初始化失败原因反馈";
CM_ SG_ 1022 PLG_PinchPlayModeStatus "防玩保护状态信号";
CM_ SG_ 1022 PLG_GateMotorStallStatus "撑杆电机堵转状态信号";
CM_ SG_ 1022 PLG_GateMotorHeatProtectStatus "撑杆电机热保护状态信号";
CM_ SG_ 1022 PLG_LatchMotorStallStatus "锁电机堵转状态信号";
CM_ SG_ 1022 PLG_LatchMotorHeatProtectStatus "锁电机热保护状态信号";
CM_ SG_ 1022 PLG_RatchetSwitch "全锁开关信号";
CM_ SG_ 1022 PLG_ResetSwitch "锁复位开关信号";
CM_ SG_ 1022 PLG_PinchEventStatus "防夹状态信号";
CM_ SG_ 1022 PLG_ApsStatus "防夹条状态信号";
CM_ SG_ 1022 PLG_LockUnderVoltage "门锁电机欠电压错误";
CM_ SG_ 1022 PLG_LockOverVoltage "门锁电机过电压错误";
CM_ SG_ 1022 PLG_LockTimeoutStatus "门锁电机运行超时状态信号";
CM_ SG_ 1022 PLG_PoleTimeoutStatus "撑杆电机运行超时状态信号";
CM_ SG_ 1022 PLG_PawlSwitch "半锁开关信号";
CM_ SG_ 1022 PLG_KickSensorStatus "脚踢传感器开关命令请求";
CM_ SG_ 1022 PLG_PoleUnderVoltage "撑杆电机欠电压错误";
CM_ SG_ 1022 PLG_PoleOverVoltage "撑杆电机过电压错误";
CM_ SG_ 1022 PLG_OpenCloseSwitch "主驾驶侧开关状态";
CM_ SG_ 1022 PLG_ShutfaceSwitch "背门内开关状态";
CM_ SG_ 1022 PLG_InitializedResult "电动背门初始化结果反馈";
CM_ SG_ 1022 PLG_InitializeStatus "电动背门初始化状态";
CM_ SG_ 1022 PLG_GatePosition "尾门位置";
CM_ SG_ 1022 PLG_OpenHeightLearningResult "电动背门开启高度学习结果反馈";
CM_ SG_ 1022 PLG_LatchStatus "锁工作状态";
CM_ SG_ 1022 PLG_MovementStatus "尾门运动状态信号";
CM_ SG_ 1022 PLG_OpenHeightLearningStatus "电动背门开启高度学习状态";
CM_ SG_ 851 DSM_RestModeSaved_Request "座椅休息模式保存请求";
CM_ SG_ 851 DSM_IP_Move_Status "座椅移动状态提醒";
CM_ SG_ 851 DSM_CurrentPosition_Status "当前座椅位置状态";
CM_ SG_ 851 DSM_HistoryRighttMirrorYPosition "右后视镜历史Y轴位置";
CM_ SG_ 851 DSM_HistoryRightMirrorXPosition "右后视镜历史X轴位置";
CM_ SG_ 851 DSM_HistoryLeftMirrorYPosition "左后视镜历史Y轴位置";
CM_ SG_ 851 DSM_HistoryLeftMirrorXPosition "左后视镜历史X轴位置";
CM_ SG_ 851 DSM_HistoryBackAngle "主驾历史倾斜角度";
CM_ SG_ 851 DSM_HistoryFrontRearPosition "主驾历史前后位置";
CM_ SG_ 851 DSM_HistoryHighLowPosition "座椅历史高低位置";
CM_ SG_ 851 DSM_PaCurrentFrontRearPosition "副驾座椅当前前后位置";
CM_ SG_ 851 DSM_PaCurrentBackAnglePosition "副驾座椅当前靠背位置";
CM_ SG_ 850 DSM_MirrorTurnSetFeedback "挂倒挡后视镜自动翻转设置反馈";
CM_ SG_ 850 DSM_RightMirrorStatus "右后视镜工作状态";
CM_ SG_ 850 DSM_LeftMirrorStatus "左后视镜工作状态";
CM_ SG_ 850 DSM_ComityFeedback "座椅礼让设置反馈";
CM_ SG_ 850 DSM_DrCurrentMemoryPosition "主驾当前记忆状态";
CM_ SG_ 850 DSM_PaPositionSaved_Request "副驾座椅位置保存请求";
CM_ SG_ 850 DSM_MirrorPositionSaved_Request "后视镜位置保存请求";
CM_ SG_ 850 DSM_DrCurrentHighLowPosition "座椅当前高低位置";
CM_ SG_ 850 DSM_DrCurrentFrontRearPosition "主驾当前前后位置";
CM_ SG_ 850 DSM_DrCurrentBackAngle "主驾当前倾斜角度";
CM_ SG_ 850 DSM_CurrentLeftMirrorXPosition "左后视镜当前X轴位置";
CM_ SG_ 850 DSM_CurrentLeftMirrorYPosition "左后视镜当前Y轴位置";
CM_ SG_ 850 DSM_CurrentRightMirrorXPosition "右后视镜当前X轴位置";
CM_ SG_ 850 DSM_CurrentRighttMirrorYPosition "右后视镜当前Y轴位置";
CM_ SG_ 850 DSM_SetSuccessed "DSM设置成功信号";
CM_ SG_ 850 DSM_PositionStatus "DSM状态信号";
CM_ SG_ 850 DSM_DrPositionSaved_Request "主驾座椅位置保存请求";
CM_ SG_ 850 DSMPaComitySwitchFeedbasck "主驾座椅礼让开关反馈";
CM_ SG_ 850 DSMDrComitySwitchFeedbasck "副驾座椅礼让开关反馈";

CM_ SG_ 849 DSM_MirrCurrentPosition_Status "后视镜当前位置状态";
CM_ SG_ 849 DSM_PaCurrentPosition_Status "当前副驾座椅位置状态";
CM_ SG_ 849 DSM_PaCurrentMemoryPosition "副驾当前记忆状态";
CM_ SG_ 849 DSM_MemoryPositionFB "HU记忆提示反馈";
CM_ SG_ 849 DSM_DrUpwardSwtich "主驾座椅向上调节开关";
CM_ SG_ 849 DSM_DrDownwardSwtich "主驾座椅向下调节开关";
CM_ SG_ 849 DSM_PaBackBackwardSwtich "副驾座椅靠背向后调节开关";
CM_ SG_ 849 DSM_PaBackForwardSwtich "副驾座椅靠背向前调节开关";
CM_ SG_ 849 DSM_PaSlideBackwardSwtich "副驾座椅水平向后调节开关";
CM_ SG_ 849 DSM_PaSlideForwardSwitch "副驾座椅水平向前调节开关";
CM_ SG_ 849 DSM_RightMirrRightwardSW "右外后视镜向右调节开关";
CM_ SG_ 849 DSM_RightMirrLeftwardSW "右外后视镜向左调节开关";
CM_ SG_ 849 DSM_RightMirrDownwardSW "右外后视镜向下调节开关";
CM_ SG_ 849 DSM_RightMirrUpwardSW "右外后视镜向上调节开关";
CM_ SG_ 849 DSM_LeftMirrRightwardSW "左外后视镜向右调节开关";
CM_ SG_ 849 DSM_LeftMirrLeftwardSW "左外后视镜向左调节开关";
CM_ SG_ 849 DSM_LeftMirrDownwardSW "左外后视镜向下调节开关";
CM_ SG_ 849 DSM_LeftMirrUpwardSW "左外后视镜向上调节开关";
CM_ SG_ 849 DSM_BackBackwardSwtich "主驾座椅靠背向后调节开关";
CM_ SG_ 849 DSM_BackForwardSwitch "主驾座椅靠背向前调节开关";
CM_ SG_ 849 DSM_SlideBackwardSwtich "主驾座椅水平向后调节开关";
CM_ SG_ 849 DSM_SlideForwardSwitch "主驾座椅水平向前调节开关";
CM_ SG_ 849 DSM_DSMMemoryPosition "座椅记忆位置请求";
CM_ SG_ 849 DSM_KeyMomerySts "钥匙联动状态";
CM_ SG_ 849 DSM_MemoryAlarm "记忆提示请求";
CM_ SG_ 1002 FSCM_PaHeatStsFeedback "副驾座椅加热状态反馈";
CM_ SG_ 1002 FSCM_DrVentilatieStsFeedback "主驾座椅通风状态反馈";
CM_ SG_ 1002 FSCM_PaVentilatieReqFeedback "副驾座椅通风状态反馈";
CM_ SG_ 1002 FSCM_DrHeatStsFeedback "主驾座椅加热状态反馈";
CM_ SG_ 1002 FSCM_DrHeatSts "主驾座椅加热状态";
CM_ SG_ 1002 FSCM_PaHeatSts "副驾座椅加热状态";
CM_ SG_ 1002 FSCM_PaVentilatieSts "副驾座椅通风状态";
CM_ SG_ 1002 FSCM_DrVentilatieSts "主驾座椅通风状态";
CM_ SG_ 1682 BCM_DTC2_Status "BCM的DTC2状态";
CM_ SG_ 1682 BCM_DTC2_LowByte "BCM的DTC2低字节";
CM_ SG_ 1682 BCM_DTC2_MiddByte "BCM的DTC2中字节";
CM_ SG_ 1682 BCM_DTC2_HighByte "BCM的DTC2高字节";
CM_ SG_ 1682 BCM_DTC1_Status "BCM的DTC1状态";
CM_ SG_ 1682 BCM_DTC1_LowByte "BCM的DTC1低字节";
CM_ SG_ 1682 BCM_DTC1_MiddByte "BCM的DTC1中字节";
CM_ SG_ 1682 BCM_DTC1_HighByte "BCM的DTC1高字节";
CM_ SG_ 982 BCM_FRWindowStatus "副驾车窗状态";
CM_ SG_ 982 BCM_RRWindowStatus "右后车窗状态";
CM_ SG_ 982 BCM_FRWindowInitializedSts "副驾车窗初始化状态";
CM_ SG_ 982 BCM_RRWindowInitializedSts "右后车窗初始化状态";
CM_ SG_ 982 BCM_FRWindowAPActice "副驾车窗防夹状态";
CM_ SG_ 982 BCM_RRWindowAPActice "右后车窗防夹状态";
CM_ SG_ 982 BCM_FRWindowSwitch "副驾车窗开关状态";
CM_ SG_ 982 BCM_RRWindowSwitch "右后车窗开关状态";
CM_ SG_ 982 BCM_FRWinMotor "副驾车窗电机状态";
CM_ SG_ 982 BCM_RRWinMotor "右后车窗电机状态";
CM_ SG_ 982 BCM_Sunroof_IntegrateSwitch "天窗一体式开关状态";
CM_ SG_ 982 BCM_WL_SunRoof_ControlReq "天窗控制请求";
CM_ SG_ 982 BCM_SunRoofControlReq2 "天窗控制请求2";
CM_ SG_ 984 BCM_FailStatus "SLCM故障信号";
CM_ SG_ 984 BCM_DriverWindowStatus "主驾车窗状态";
CM_ SG_ 984 BCM_RLWindowStatus "左后车窗状态";
CM_ SG_ 984 BCM_DriverWindowInitializedSts "主驾车窗初始化状态";
CM_ SG_ 984 BCM_RLWindowInitializedSts "左后车窗初始化状态";
CM_ SG_ 984 BCM_DriverWindowAPActice "主驾车窗防夹状态";
CM_ SG_ 984 BCM_RLWindowAPActice "左后车窗防夹状态";
CM_ SG_ 984 BCM_DriverWindowSwitch "主驾车窗开关状态";
CM_ SG_ 984 BCM_RLWindowSwitch "左后车窗开关状态";
CM_ SG_ 984 BCM_DriverWinMotor "主驾车窗电机状态";
CM_ SG_ 984 BCM_RLWinMotor "左后车窗电机状态";
CM_ SG_ 984 BCM_DoorlockSwitchStatus "车门中控解闭锁开关";
CM_ SG_ 984 BCM_WindowlockSwitchStatus "车窗锁止开关";
CM_ SG_ 1533 BCM_CRCCheck_5FD "BCM_5FD校验和";
CM_ SG_ 1533 BCM_3RollingCounter_5FD "BCM_5FD计数器";
CM_ SG_ 1533 BCM_FBLRemoteSts "远程启动反馈";
CM_ SG_ 1533 BCM_FBLBatterySts "蓄电池状态反馈";
CM_ SG_ 1533 BCM_FBLEngineSts "发动机状态反馈";
CM_ SG_ 1533 BCM_FBLVehicleSpeedSts "车速状态反馈";
CM_ SG_ 1533 BCM_FBLShiftSts "换档器状态反馈";
CM_ SG_ 1533 BCM_FBLPowerReqFeedback "刷写档位电源反馈";
CM_ SG_ 1533 BCM_FBLhandbreakSts "手刹状态反馈";
CM_ SG_ 1535 BCM_RemoteTrunkFeedback "远程行李箱解锁反馈";
CM_ SG_ 1535 BCM_LatchOverheatProtect "锁电机过热保护";
CM_ SG_ 1535 BCM_LockAutoClsSunroofSetStatus "闭锁关天窗设置状态";
CM_ SG_ 1535 BCM_RemoteCtrlSunroofSetStatus "遥控控制天窗设置状态";
CM_ SG_ 1535 BCM_RemoteControlWindowSetStatus "遥控控制车窗设置状态";
CM_ SG_ 1535 BCM_RemoteControlSwtichSetStatus "解闭锁反馈方式设置（灯光+声音，仅灯光、仅声音）";
CM_ SG_ 1535 BCM_CarWashMirrorFoldFeedback "洗车模式后视镜折叠设置状态";
CM_ SG_ 1535 BCM_MirrorAutoFoldSetStatus "后视镜自动折叠设置状态";
CM_ SG_ 1535 BCM_RearWiperSetStatus "倒档后雨刮自动刮刷设置状态";
CM_ SG_ 1535 BCM_CarRemindFeedback "停车位置提示反馈";
CM_ SG_ 1535 LCM_MirrorAutoFoldSetStatus "后视镜自动折叠设置反馈";
CM_ SG_ 1535 PEPS_SmartTrunkUlockStaus "智能行李箱主动开启设置反馈";
CM_ SG_ 1535 PEPS_Smartlockstatus "离开闭锁设置状态";
CM_ SG_ 1535 PEPS_SmartUnlockstatus "靠近解锁设置状态";
CM_ SG_ 1535 PEPS_HandleProximitySensorSignal "门把手感应开关状态信号";
CM_ SG_ 1535 PEPS_KeyBatteryStatus "智能钥匙电池状态";
CM_ SG_ 1535 PEPS_KeyUndetectedAlarmSignal "未检测到钥匙报警信号";
CM_ SG_ 1535 PEPS_KeyInCarAlarmSignal "钥匙在车内报警信号";
CM_ SG_ 1535 PEPS_UnlockModeTransitionSignal "解锁模式转换信号";
CM_ SG_ 1535 PEPS_DoorHandleButtonSignal "门把手按钮状态信号";
CM_ SG_ 1535 PEPS_GreetLampFB "迎宾功能反馈";
CM_ SG_ 1535 BCM_RmoteUnLockFeedback "远程解锁反馈";
CM_ SG_ 1535 BCM_KeyInSignal "钥匙未拔信号";
CM_ SG_ 1535 PEPS_PeScanDoorStatus "扫描钥匙前门状态";
CM_ SG_ 1535 PEPS_KeyPositionStatus "智能钥匙位置状态";
CM_ SG_ 1535 BCM_AutoLeaveLockSetStatus "离车自动闭锁设置状态";
CM_ SG_ 1535 BCM_TwiceLockDoorSetStatus "二次落锁设置状态";
CM_ SG_ 1535 BCM_RmoteLockFeedback "远程闭锁反馈";
CM_ SG_ 1535 BCM_AutoSpeedLockSetStatus "自动速度落锁设置状态";
CM_ SG_ 1535 BCM_AutoParkUnlockSetStatus "自动驻车解锁设置状态";
CM_ SG_ 1535 BCM_RKEUnlockDoorTypeSetStatus "遥控钥匙解锁模式设置状态";
CM_ SG_ 1535 BCM_AutoLockFeedback "自动锁车反馈";
CM_ SG_ 1524 BCM_WkupSocBatSoc "低电量唤醒SOC值";
CM_ SG_ 1524 BCM_WkupSocTimeCounter "低电量唤醒时间计数值";
CM_ SG_ 1524 BCM_WkupDischBatSoc "过流唤醒SOC值";
CM_ SG_ 1524 BCM_WkupDschrgCurrent "过流唤醒电流值";
CM_ SG_ 1524 BCM_WkupDischTimeCounter "过流唤醒时间计数值";
CM_ SG_ 1510 BCM_HotMagCurrentData "热监控电流数据";
CM_ SG_ 1304 BCM_FuelPotentialCond "节油潜力工况";
CM_ SG_ 1304 BCM_RoutineID "行程ID";
CM_ SG_ 1304 BCM_RealFuelConsumption "实时油耗";
CM_ SG_ 1304 BCM_RoutineOdometer "行程里程";
CM_ SG_ 1304 BCM_RealFuelPotential "实时节油潜力";
CM_ SG_ 1304 BCM_CarMode "车辆模式信号";
CM_ SG_ 1304 BCM_BrakeAccChangeQCond "刹车油门频繁切换";
CM_ SG_ 1304 BCM_EmergSteerCond "急转弯提醒";
CM_ SG_ 1304 BCM_AllFuelConsumption "行程总油耗";
CM_ SG_ 1298 PEPS_VIN "VIN码";
CM_ SG_ 1021 HU_CRCCheck_3FD "校验和";
CM_ SG_ 1021 HU_RollingCounter_3FD "计数器";
CM_ SG_ 1021 HU_EPSTorqueMode "转向助力模式请求";
CM_ SG_ 1021 HU_DriveMode "驾驶模式";
CM_ SG_ 1021 HU_IP_DriveModeDisplayFit "驾驶模式英文字符显示";
CM_ SG_ 1023 BCM_RainOpenLightStatus "雨雾天开灯设置状态";
CM_ SG_ 1023 BCM_BrakeLampStatus "刹车灯状态";
CM_ SG_ 1023 BCM_AutoturnlightovertakemodeSetSts "超车模式自动转向灯设置状态";
CM_ SG_ 1023 BCM_LightingDoorOpenWarningStatus "照明开门预警设置反馈";
CM_ SG_ 1023 BCM_LightingBackwardWarningStatus "照明倒车提醒设置反馈";
CM_ SG_ 1023 BCM_RearLeftTuningLightFaultSts "后左转向灯故障信号";
CM_ SG_ 1023 BCM_HighBeamLampError "远光灯故障状态";
CM_ SG_ 1023 BCM_AutoHeadlightSetSts "自动大灯设置状态(语音)";
CM_ SG_ 1023 BCM_FollowMeHomeLightSetStatus "跟随回家灯光设置状态";
CM_ SG_ 1023 BCM_DRLSts "日间行车灯状态";
CM_ SG_ 1023 BCM_PositionLampSwitchStatus "位置灯开关状态";
CM_ SG_ 1023 BCM_TurnIndicatorLeftError "左转向灯故障状态";
CM_ SG_ 1023 BCM_TurnIndicatorRightError "右转向灯故障状态";
CM_ SG_ 1023 BCM_RearRightTuningLightFaultSts "后右转向灯故障信号";
CM_ SG_ 1023 BCM_CHMLampError "高位制动灯灯故障状态";
CM_ SG_ 1023 BCM_ReverseLampError "倒车灯故障状态";
CM_ SG_ 1023 BCM_LeftDayLampError "左日间行车灯故障状态";
CM_ SG_ 1023 BCM_RightDayLampError "右日间行车灯故障状态";
CM_ SG_ 1023 BCM_LeftPositionLampError "左位置灯故障状态";
CM_ SG_ 1023 BCM_RightPositionLampError "右位置灯故障状态";
CM_ SG_ 1023 BCM_ReverseLightSts "倒车灯状态";
CM_ SG_ 1023 BCM_RearPositionLampError "后位置灯故障状态";
CM_ SG_ 1023 BCM_LeftLowBeamError "左近光灯故障状态";
CM_ SG_ 1023 BCM_RightLowBeamError "右近光灯故障状态";
CM_ SG_ 1023 BCM_LeftFrontFoglampError "左前雾灯故障状态";
CM_ SG_ 1023 BCM_RightFrontFoglampError "右前雾灯故障状态";
CM_ SG_ 1023 BCM_LeftRearFoglampError "左后雾灯故障状态";
CM_ SG_ 1023 BCM_RightRearFoglampError "右后雾灯故障状态";
CM_ SG_ 1023 BCM_BrakeLampError "刹车灯故障状态";
CM_ SG_ 1023 BCM_PositionLampStatus "位置灯工作状态";
CM_ SG_ 1023 BCM_RearFoglampStatus "后雾灯工作状态";
CM_ SG_ 1023 BCM_FrontFoglampStatus "前雾灯工作状态";
CM_ SG_ 1023 BCM_AutoHeadlightSts "自动大灯状态";
CM_ SG_ 1023 BCM_FrontPositionLampError "前位置灯故障状态";
CM_ SG_ 1023 BCM_OutWelcomeSoundFeedback "律动迎宾声音设置反馈";
CM_ SG_ 1023 BCM_Musiclightfeedback "音乐灯光反馈信号";
CM_ SG_ 1023 BCM_FollowMeTurnon "跟随回家功能开启";
CM_ SG_ 1023 BCM_MusicLightModeSelectSts "音乐灯光模式选择反馈";
CM_ SG_ 1023 BCM_MusicPlayRequestSignal "音乐播放请求";
CM_ SG_ 1007 BCM_Interactive_switch_Status "智能交互载体开关设置状态";
CM_ SG_ 1007 BCM_ALCEnableStatus "氛围灯使能状态反馈";
CM_ SG_ 1007 BCM_LaneChangeTurnLightSetStatus "变道闪光设置状态";
CM_ SG_ 1007 BCM_SenseBlossomEnable "感知花季使能设置状态";
CM_ SG_ 1007 BCM_AtmoLightAAEnableSts "氛围灯自动调节使能设置状态";
CM_ SG_ 1007 BCM_AtmoLightLinkDoorEnableSts "车门未关氛围灯提醒使能设置状态";
CM_ SG_ 1007 BCM_AtmoLightLinkDriveModeSts "驾驶模式调节设置状态";
CM_ SG_ 1007 BCM_AtmoLightSceneMode_FeedBack "氛围灯情景模式反馈信号";
CM_ SG_ 1007 BCM_SenseAQIEnable "感知空气质量使能设置状态";
CM_ SG_ 1007 BCM_AtmoLightOverspeedEnableSts "超速氛围灯预警使能设置状态";
CM_ SG_ 1007 BCM_AtmoLightLinkStartEnableSts "科技点火使能设置状态";
CM_ SG_ 1007 BCM_WelcomeAtmoLightEnableSts "开门氛围灯迎宾使能设置状态";
CM_ SG_ 1007 BCM_SEWEnableSts "开门预警使能设置状态";
CM_ SG_ 1007 BCM_AtmosphereLightColorSetStatus "氛围灯颜色状态反馈";
CM_ SG_ 1007 BCM_DimmerLevelSts "背景光调光设置反馈";
CM_ SG_ 1007 BCM_AtmosphereLightbrightnessSetStatus "氛围灯亮度状态反馈";
CM_ SG_ 1007 BCM_Dimmerlevel "背景光调光等级";
CM_ SG_ 1007 BCM_RoomLightControlSts "顶灯状态";
CM_ SG_ 1007 BCM_SetDoorLightStatus "Door挡开关设置状态";
CM_ SG_ 1007 BCM_AtmosphereLightswitchSetStatus "氛围灯开关设置状态";
CM_ SG_ 1007 BCM_AtmoLightTopLightEnableSts "前顶灯氛围灯联动使能设置状态";
CM_ SG_ 1000 BCM_SOF_t_STATE "到启动临界点时间状态";
CM_ SG_ 1000 BCM_SOF_V2_STATE "SOF_V2状态";
CM_ SG_ 1000 BCM_SOF_V1_STATE "SOF_V1状态";
CM_ SG_ 1000 BCM_SOF_Q_STATE "实际剩余蓄电池电量状态";
CM_ SG_ 1000 BCM_SOC_STATE "蓄电池传感器SOC状态";
CM_ SG_ 1000 BCM_SOF_t "到启动临界点时间";
CM_ SG_ 1000 BCM_SOF_V2 "SOF_V2值";
CM_ SG_ 1000 BCM_SOF_V1 "SOF_V1值";
CM_ SG_ 1000 BCM_SOF_Q "实际剩余蓄电池电量";
CM_ SG_ 1000 BCM_SOC "蓄电池传感器SOC值";
CM_ SG_ 999 BCM_FLAG_INCONSISTENCY "蓄电池内阻一致性标志";
CM_ SG_ 999 BCM_Resp_Error "响应错误";
CM_ SG_ 999 BCM_ERROR_IDENT "ECU认证错误";
CM_ SG_ 999 BCM_ERROR_Calib "标定数据错误";
CM_ SG_ 999 BCM_Status_Temp "蓄电池传感器温度状态信号";
CM_ SG_ 999 BCM_Status_Voltage "蓄电池传感器电压状态信号";
CM_ SG_ 999 BCM_Status_Current "蓄电池传感器电流状态信号";
CM_ SG_ 999 BCM_IBATT_QUIESCENT "蓄电池传感器静态电流信号";
CM_ SG_ 999 BCM_T_BATT "蓄电池传感器温度信号";
CM_ SG_ 999 BCM_I_BATT "蓄电池传感器电流信号";
CM_ SG_ 999 BCM_I_RANGE "蓄电池电流范围";
CM_ SG_ 999 BCM_U_BATT "蓄电池传感器电压信号";
CM_ SG_ 989 BCM_RLWindowAPActice "左后车窗防夹状态";
CM_ SG_ 989 BCM_DriverWindowAPActice "主驾车窗防夹状态";
CM_ SG_ 989 BCM_RLWindowInitializedSts "左后车窗初始化状态";
CM_ SG_ 989 BCM_DriverWindowInitializedSts "主驾车窗初始化状态";
CM_ SG_ 989 BCM_RRWindowAPActice "右后车窗防夹状态";
CM_ SG_ 989 BCM_PassengerWindowAPActice "副驾车窗防夹状态";
CM_ SG_ 989 BCM_RRWindowInitializedSts "右后车窗初始化状态";
CM_ SG_ 989 BCM_FRWindowInitializedSts "副驾车窗初始化状态";
CM_ SG_ 989 BCM_LeftRearWinMotor "左后窗电机状态";
CM_ SG_ 989 BCM_DriverWinMotor "左前窗电机状态";
CM_ SG_ 989 BCM_RightRearWinMotor "右后窗电机状态";
CM_ SG_ 989 BCM_PassengerWinMotor "右前窗电机状态";
CM_ SG_ 989 BCM_LeftRearWindowStatus "左后车窗状态";
CM_ SG_ 989 BCM_DriverWindowStatus "主驾车窗状态";
CM_ SG_ 989 BCM_RightRearWindowStatus "右后车窗状态";
CM_ SG_ 989 BCM_PassengerWindowStatus "副驾车窗状态";
CM_ SG_ 942 BCM_Q_Discharge "累计放电电量";
CM_ SG_ 942 BCM_Q_Charge "累计充电电量";
CM_ SG_ 938 BCM_DoorHandle_TimeDifference "门把手到位时间差";
CM_ SG_ 938 BCM_DriverDoorHandleStatus "左前门把手状态";
CM_ SG_ 938 BCM_LeftRearDoorHandleStatus "左后门把手状态";
CM_ SG_ 938 BCM_PassengeDoorHandleStatus "右前门把手状态";
CM_ SG_ 938 BCM_RightRearDoorHandleStatus "右后门把手状态";
CM_ SG_ 918 BCM_Sunroof_Intialized "天窗初始化状态";
CM_ SG_ 918 BCM_WindowPositionCtrl "车窗开度控制信号";
CM_ SG_ 918 BCM_RemoteWindowFeedback "远程控制车窗反馈";
CM_ SG_ 918 BCM_AerationHintReq "车窗留缝提示请求";
CM_ SG_ 918 BCM_Sunroof_APActive "天窗防夹状态";
CM_ SG_ 918 PEPS_RemoteWindowUpSignal "遥控升窗信号";
CM_ SG_ 918 PEPS_RemoteWindowDownSignal "遥控降窗信号";
CM_ SG_ 918 BCM_RemoteWindowUpSetStaus "遥控升车窗设置状态反馈";
CM_ SG_ 918 BCM_RemoteWindowDownSetStaus "遥控降车窗设置状态反馈";
CM_ SG_ 918 BCM_AutoCloseWindow "离车下雨自动关窗";
CM_ SG_ 918 BCM_RemoteWindowControl "遥控车窗信号";
CM_ SG_ 918 BCM_WinOpenWarn "车窗状态报警";
CM_ SG_ 918 BCM_WinDownCfgSts "车窗下降配置状态";
CM_ SG_ 918 BCM_WinUpCfgSts "车窗上升配置状态";
CM_ SG_ 918 BCM_LockAutoClsWinSetStatus "闭锁关车窗设置状态";
CM_ SG_ 918 BCM_SunroofMotor "天窗电机状态";
CM_ SG_ 918 BCM_Sunroof_Position "天窗位置状态";
CM_ SG_ 918 BCM_RainCtrlSunRoofSetStatus "雨量感应天窗设置状态（设置开启关闭）";
CM_ SG_ 918 BCM_Sunshade_Movement "遮阳帘运动状态";
CM_ SG_ 918 BCM_Sunroof_Movement "天窗运动状态";
CM_ SG_ 918 BCM_Sunshade_POS_VIT_FL "遮阳帘开度位置反馈";
CM_ SG_ 918 BCM_Sunroof_POS_Direction "天窗运行区间";
CM_ SG_ 912 BCM_BSNLevel "蓄电池健康等级信号";
CM_ SG_ 912 BCM_SOH_LifePercent "蓄电池寿命百分比";
CM_ SG_ 912 BCM_LowPowerWarning "蓄电池电量提示";
CM_ SG_ 912 BCM_PMSLevel "电源管理等级信号";
CM_ SG_ 912 BCM_PMSErrorFlag "电源管理系统故障提示信号";
CM_ SG_ 905 BCM_ValetModelFeedback "朋友模式信号";
CM_ SG_ 905 BCM_BrakePedalStatus "制动踏板状态";
CM_ SG_ 905 BCM_WindowContralSta "车窗控制信号";
CM_ SG_ 905 BCM_WiperForbiddenSta "雨刮禁用状态";
CM_ SG_ 905 BCM_WiperServiceReqStatus "雨刮维修模式信号";
CM_ SG_ 905 BCM_RearWiperPosition "后雨刮位置";
CM_ SG_ 905 BCM_FrontWiperPosition "前雨刮位置";
CM_ SG_ 905 BCM_TrumpetSwitchStatus "喇叭开关状态";
CM_ SG_ 905 BCM_EmergencyLightSwitchStatus "紧急报警灯开关状态";
CM_ SG_ 905 BCM_FrontFoglampSwitchStatus "前雾灯开关状态";
CM_ SG_ 905 BCM_OverTakeLightSwitchStatus "超车灯开关状态";
CM_ SG_ 905 BCM_FrontWiperSensibility "前雨刮开关灵敏度等级";
CM_ SG_ 905 BCM_FrontWiperSwitchStatus "前雨刮开关状态";
CM_ SG_ 905 RLS_WiperAutoSpReq "雨刮档位速度请求";
CM_ SG_ 905 BCM_FrontWiperIntervalTime "前雨刮开关间隙档时间";
CM_ SG_ 905 BCM_CarWashModelstatus "洗车模式状态信号";
CM_ SG_ 905 BCM_SunshadeSwitchStatus "遮阳帘开关状态";
CM_ SG_ 905 BCM_SunRoofSwitchStatus "天窗开关状态";
CM_ SG_ 905 BCM_RearMirrorFoldStatus "外后视镜状态信号";
CM_ SG_ 905 BCM_RightRearWindowSwitchStatus1 "右后座位侧车窗开关状态";
CM_ SG_ 905 BCM_LeftRearWindowSwitchStatus1 "左后座位侧车窗开关状态";
CM_ SG_ 905 BCM_PassengerWindowSwitchStatus1 "副驾座位侧车窗开关状态";
CM_ SG_ 905 BCM_RoofLampDoorSwitchStatus "顶灯door档开关信号";
CM_ SG_ 905 BCM_AutoHeadlightSwitchStatus "自动大灯开关状态";
CM_ SG_ 905 BCM_RearWashSwitchStatus "后洗涤开关状态";
CM_ SG_ 905 BCM_FrontWashSwitchStatus "前洗涤开关状态";
CM_ SG_ 905 BCM_LowBeamSwitchStatus "近光灯开关状态";
CM_ SG_ 905 BCM_HighBeamSwitchStatus "远光灯开关状态";
CM_ SG_ 905 BCM_RearFoglampSwitchStatus "后雾灯开关状态";
CM_ SG_ 905 BCM_PositionLampSwitchStatus "位置灯开关状态";
CM_ SG_ 905 BCM_RearWiperSwitchStatus "后雨刮开关状态";
CM_ SG_ 903 BCM_RainOpenLightRequest "雨雾天开灯请求";
CM_ SG_ 903 BCM_VoiceWelcomeTipsContent "车外语音提示内容";
CM_ SG_ 903 BCM_VoiceWelcometSts "车外语音迎宾设置状态";
CM_ SG_ 903 BCM_SaveEnergySetStatus "节能电源设置状态";
CM_ SG_ 903 BCM_RearWiperStatus "后雨刮工作状态";
CM_ SG_ 903 BCM_SystemFailureFlag "BCM系统故障";
CM_ SG_ 903 BCM_Statuslowbeam "光传感器故障信号";
CM_ SG_ 903 BCM_Statusrainsensor "雨量传感器故障";
CM_ SG_ 903 BCM_AmbientLightStatus "环境光传感器";
CM_ SG_ 903 BCM_BuzzerWarningMode "蜂鸣器报警模式";
CM_ SG_ 903 BCM_RLS_Light_switch_reason "RLS环境光检测信号";
CM_ SG_ 903 BCM_FrontWiperStatus "前雨刮工作状态";
CM_ SG_ 903 BCM_FrontWashStatus "前洗涤工作状态";
CM_ SG_ 903 BCM_ThemeChangeSet "主题切换操作";
CM_ SG_ 903 BCM_RainfallLevel "雨量强度";
CM_ SG_ 903 BCM_DriveModeSet "驾驶模式设置信号";
CM_ SG_ 903 BCM_DrivingModeMemoryStatus "驾驶模式记忆反馈";
CM_ SG_ 903 BCM__BLEKeyIndicator "蓝牙钥匙提示信号";
CM_ SG_ 903 BCM_DriveModeStatus "驾驶模式状态";
CM_ SG_ 903 BCM_DriveModeFeedback "驾驶模式动力传动设置反馈";
CM_ SG_ 902 BCM_RRPressureSensorLowPower "右后RR胎压传感器电池电量低";
CM_ SG_ 902 BCM_LRPressureSensorLowPower "左后RL胎压传感器电池电量低";
CM_ SG_ 902 BCM_RFPressureSensorLowPower "右前FR胎压传感器电池电量低";
CM_ SG_ 902 BCM_LFPressureSensorLowPower "左前FL胎压传感器电池电量低";
CM_ SG_ 902 BCM_RRPressureNotLearn "右后胎压未学习";
CM_ SG_ 902 BCM_LRPressureNotLearn "左后胎压未学习";
CM_ SG_ 902 BCM_RFPressureNotLearn "右前胎压未学习";
CM_ SG_ 902 BCM_LFPressureNotLearn "左前胎压未学习";
CM_ SG_ 902 BCM_RRPressureSensorDiagnosis "右后RR胎压传感器诊断信号";
CM_ SG_ 902 BCM_LRPressureSensorDiagnosis "左后RL胎压传感器诊断信号";
CM_ SG_ 902 BCM_RFPressureSensorDiagnosis "右前FR胎压传感器诊断信号";
CM_ SG_ 902 BCM_LFPressureSensorDiagnosis "左前FL胎压传感器诊断信号";
CM_ SG_ 902 BCM_RLS_NotInstalled "光雨量传感器未安装到位";
CM_ SG_ 902 BCM_TurnIndicatorRightRearDiagnosis "右后转向灯诊断信号";
CM_ SG_ 902 BCM_TurnIndicatorLeftRearDiagnosis "左后转向灯诊断信号";
CM_ SG_ 902 BCM_TurnIndicatorRightFrontDiagnosis "右前转向灯诊断信号";
CM_ SG_ 902 BCM_TurnIndicatorLeftFrontDiagnosis "左前转向灯诊断信号";
CM_ SG_ 902 BCM_PositionLampDiagnosis "位置灯诊断信号";
CM_ SG_ 902 BCM_BrakeLightDiagnosis "制动灯诊断信号";
CM_ SG_ 902 BCM_RightHighBeamDiagnosis "右远光灯诊断信号";
CM_ SG_ 902 BCM_LeftHighBeamDiagnosis "左远光灯诊断信号";
CM_ SG_ 902 BCM_RightLowBeamDiagnosis "右近光灯诊断信号";
CM_ SG_ 902 BCM_LeftLowBeamDiagnosis "左近光灯诊断信号";
CM_ SG_ 902 BCM_RearFoglampDiagnosis "后雾灯诊断信号";
CM_ SG_ 902 BCM_TrunkLowFrequencyAntennaDiagnosis "后备箱低频天线诊断信号";
CM_ SG_ 902 BCM_MiddleCarLowFrequencyAntennaDiagnosis "车内中排低频天线诊断信号";
CM_ SG_ 902 BCM_FrontCarLowFrequencyAntennaDiagnosis "车内前排低频天线诊断信号";
CM_ SG_ 902 BCM_RightLowFrequencyAntennaDiagnosis "右侧低频天线诊断信号";
CM_ SG_ 902 BCM_LeftLowFrequencyAntennaDiagnosis "左侧低频天线诊断信号";
CM_ SG_ 889 Sunshade_PinchPlayModeStatus "天窗遮阳帘防玩保护状态信号";
CM_ SG_ 889 Sunshade_PinchEventStatus "天窗遮阳帘防夹状态信号";
CM_ SG_ 889 Sunshade_MotorStallStatus "遮阳帘电机堵转状态信号";
CM_ SG_ 889 Sunshade_MasterSlave2 "玻璃&遮阳帘互传信息保留字节";
CM_ SG_ 889 Sunshade_POS_VIT_FL "遮阳帘水平开度位置百分比";
CM_ SG_ 889 Sunshade_MasterSlave "玻璃&遮阳帘互传信息保留字节";
CM_ SG_ 889 Sunshade_APActive "防夹信号状态";
CM_ SG_ 889 Sunshade_Status "遮阳帘状态";
CM_ SG_ 889 Sunshade_TeachRun "是否处于自学习过程";
CM_ SG_ 889 Sunshade_Initialized "是否初始化";
CM_ SG_ 889 Sunshade_MovementStatus "遮阳帘运动状态";
CM_ SG_ 889 Sunshade_Position "遮阳帘所处特殊位置";
CM_ SG_ 889 Sunshade_TimeoutStatus "遮阳帘运行超时状态信号";
CM_ SG_ 889 Sunshade_RelayError "继电器错误";
CM_ SG_ 889 Sunshade_UnderVoltage "是否欠电压";
CM_ SG_ 889 Sunshade_OverVoltage "是否过电压";
CM_ SG_ 889 Sunshade_ThermalProtection "过热保护";
CM_ SG_ 889 Sunshade_HallError "霍尔信号错误";
CM_ SG_ 889 Sunshade_ECUError "遮阳帘ECU错误";
CM_ SG_ 889 Sunshade_Switch "遮阳帘开关状态";
CM_ SG_ 890 Sunroof_MasterSlave "玻璃&遮阳帘互传信息保留字节";
CM_ SG_ 890 Sunroof_MotorStallStatus "玻璃电机堵转状态";
CM_ SG_ 890 Sunroof_PinchEventStatus "天窗玻璃防夹状态信号";
CM_ SG_ 890 Sun_InitializedFailReason "天窗初始化失败原因";
CM_ SG_ 890 Sunroof_PinchPlayModeStatus "天窗玻璃防玩保护状态信号";
CM_ SG_ 890 Sun_InitializedResult "天窗学习结果反馈";
CM_ SG_ 890 Sunroof_RelayError "继电器的错误";
CM_ SG_ 890 Sunroof_UnderVoltage "是否欠电压";
CM_ SG_ 890 Sunroof_OverVoltage "是否过电压";
CM_ SG_ 890 Sunroof_TeachRun "是否处于自学习过程";
CM_ SG_ 890 Sunroof_SsInitializing "是否处于初始化过程";
CM_ SG_ 890 Sunroof_ThermalProtection "天窗热保护";
CM_ SG_ 890 Sunroof_MovementStatus "天窗运动状态";
CM_ SG_ 890 Sunroof_Position "玻璃所处特殊位置";
CM_ SG_ 890 Sunroof_POS_Direction "天窗朝向";
CM_ SG_ 890 Sunroof_TimeoutStatus "玻璃运行超时状态信号";
CM_ SG_ 890 Sunroof_HallError "天窗霍尔传感器错误";
CM_ SG_ 890 Sunroof_Switch "天窗开关状态";
CM_ SG_ 890 BDCR_ECUError "BDCRECU错误";
CM_ SG_ 890 Sunroof_APActive "防夹信号";
CM_ SG_ 890 Sunroof_Status "天窗状态";
CM_ SG_ 890 Sunroof_Initialized "是否初始化";
CM_ SG_ 887 RFDOOR_ALCBrightnessStatusFeedback "右前门板氛围灯亮度状态反馈";
CM_ SG_ 887 RFDOOR_ALCColorStatusFeedback "右前门板氛围灯颜色状态反馈";
CM_ SG_ 887 RFDOOR_ALCStatus "右前门板氛围灯状态信号";
CM_ SG_ 886 LFDOOR_ALCBrightnessStatusFeedback "左前门板氛围灯亮度状态反馈";
CM_ SG_ 886 LFDOOR_ALCColorStatusFeedback "左前门板氛围灯颜色状态反馈";
CM_ SG_ 886 LFDOOR_ALCStatus "左前门板氛围灯状态信号";
CM_ SG_ 885 InstrumentPanel_MiddleALCBrightnessStatusFeedback "仪表板中控氛围灯亮度状态反馈";
CM_ SG_ 885 InstrumentPanel_MiddleALCColorStatusFeedback "仪表板中控氛围灯颜色状态反馈";
CM_ SG_ 885 InstrumentPanel_MiddleALCStatus "仪表板中控氛围灯状态信号";
CM_ SG_ 883 InstrumentPanel_LeftALCBrightnessStatusFeedback "仪表板左侧氛围灯亮度状态反馈";
CM_ SG_ 883 InstrumentPanel_LeftALCColorStatusFeedback "仪表板左侧氛围灯颜色状态反馈";
CM_ SG_ 883 InstrumentPanel_LeftALCStatus "仪表板左侧氛围灯状态信号";
CM_ SG_ 881 RLS_Communication_error "LIN通信状态";
CM_ SG_ 881 RainfallLevel "雨量等级";
CM_ SG_ 881 RLS_Error_status_over_voltage "过压状态";
CM_ SG_ 881 RLS_Error_status_light_sensor "光传感器运行状态";
CM_ SG_ 881 RLS_Error_status_coding_rain_sensor "透光率配置反馈状态";
CM_ SG_ 881 RLS_Error_status_rain_sensor "雨量传感器运行状态";
CM_ SG_ 881 RLS_RLS_error "传感器故障状态";
CM_ SG_ 881 RLS_Status_low_beam "光传感器运行状态";
CM_ SG_ 881 RLS_Light_switch_request "自动大灯开启请求";
CM_ SG_ 881 RLS_LIN2_CRC "校验和";
CM_ SG_ 881 RLS_LIN2_RollingCounter "计数器";
CM_ SG_ 881 RLS_SunRoofCloseReqReason "雨天关窗原因";
CM_ SG_ 881 RLS_Light_switch_reason "自动大灯开关原因";
CM_ SG_ 881 RLS_Status_rain_sensor "雨量传感器运行状态";
CM_ SG_ 881 RLS_Wiper_speed "前雨刷速度请求";
CM_ SG_ 880 RLS_DewPoint "露点温度";
CM_ SG_ 880 RLS_WindshieldTemp "前挡风玻璃温度";
CM_ SG_ 880 RLS_relativeHumidity "相对湿度";
CM_ SG_ 880 RLS_SolarRight "右侧光照强度";
CM_ SG_ 880 RLS_SolarLeft "左侧光照强度";
CM_ SG_ 1668 TPMS_checksum "校验和";
CM_ SG_ 1667 TPMS__SensorFailure_Alarm "传感器故障";
CM_ SG_ 1667 TPMS_BatteryLevel_Alarm "电池电量标志";
CM_ SG_ 1667 TPMS_Hightemperature_Alarm "高温报警标志";
CM_ SG_ 1667 TPMS_Airleakage_Alarm "漏气报警标志";
CM_ SG_ 1667 TPMS_Informatioan_Frame "TPMS_信息帧序号";
CM_ SG_ 1667 TPMS__temperature "轮胎温度值";
CM_ SG_ 1667 TPMS__pressure "轮胎压力值";
CM_ SG_ 1667 TPMS_ID4 "胎压传感器ID4";
CM_ SG_ 1667 TPMS_ID3 "胎压传感器ID3";
CM_ SG_ 1667 TPMS_ID2 "胎压传感器ID2";
CM_ SG_ 1667 TPMS_ID1 "胎压传感器ID1";
CM_ SG_ 1667 TPMS_STYTUS "胎压传感器ID1";
CM_ SG_ 1310 BCM_AerateFlag "轮胎加气标志位";
CM_ SG_ 1310 BCM_Commendatory_pressure "轮胎推荐加气值";
CM_ SG_ 1310 BCM_Suggestion "TPMS温馨提示";
CM_ SG_ 1310 BCM_LRLeakageWarning "左后轮胎漏气等级信号";
CM_ SG_ 1310 BCM_RRLeakageWarning "右后轮胎漏气等级信号";
CM_ SG_ 1310 BCM_RFLeakageWarning "右前轮胎漏气等级信号";
CM_ SG_ 1310 BCM_LFLeakageWarning "左前轮胎漏气等级信号";
CM_ SG_ 1310 BCM_TireTemperature "轮胎温度值";
CM_ SG_ 1310 BCM_TirePosition "温度值轮胎位置";
CM_ SG_ 1310 BCM_LRTemperatureWarning "左后轮胎温度报警";
CM_ SG_ 1310 BCM_RRTemperatureWarning "右后轮胎温度报警";
CM_ SG_ 1310 BCM_RFTemperatureWarning "右前轮胎温度报警";
CM_ SG_ 1310 BCM_LFTemperatureWarning "左前轮胎温度报警";
CM_ SG_ 839 BCM_SystemFailureWarning "系统故障报警";
CM_ SG_ 839 BCM_LFPressureWarning "左前轮胎压力报警";
CM_ SG_ 839 BCM_RRPressureWarning "右后轮胎压力报警";
CM_ SG_ 839 BCM_LRTyrePressure "左后轮胎压力";
CM_ SG_ 839 BCM_RRTyrePressure "右后轮胎压力";
CM_ SG_ 839 BCM_RFTyrePressure "右前轮胎压力";
CM_ SG_ 839 BCM_LFTyrePressure "左前轮胎压力";
CM_ SG_ 839 BCM_LRPressureWarning "左后轮胎压力报警";
CM_ SG_ 839 BCM_RFPressureWarning "右前轮胎压力报警";
CM_ SG_ 839 BCM_TirePresureSignalStatus "胎压信号状态";
CM_ SG_ 839 BCM_SignalStatus "信号状态";
CM_ SG_ 664 BCM_WindowElectricInspectionSign "车窗电检学习标志";
CM_ SG_ 664 BCM_LockandUnlockFeedback "解锁及闭锁状态反馈";
CM_ SG_ 664 BCM_LeftRearDoorStatus "左后门状态";
CM_ SG_ 664 BCM_PassengerDoorLockStatus "乘员侧门锁状态信号";
CM_ SG_ 664 BCM_DriverDoorLockStatus "驾驶侧门锁状态信号";
CM_ SG_ 664 BCM_PassengerDoorStatus "右前门状态";
CM_ SG_ 664 PEPS_UnLockKeyStatus "钥匙解锁按键状态";
CM_ SG_ 664 PEPS_TrunkKeyStatus "钥匙行李箱按键状态";
CM_ SG_ 664 BCM_BreathingLightSet_FeedBack "迎宾灯设置反馈";
CM_ SG_ 664 BCM_RightRearDoorStatus "右后门状态";
CM_ SG_ 664 BCM_TrunkStatus "行李箱门状态";
CM_ SG_ 664 PEPS_LockKeyStatus "钥匙闭锁按键状态";
CM_ SG_ 664 PEPS_SmartLockSignal "智能闭锁信号";
CM_ SG_ 664 PEPS_SmartUnlockSignal "智能解锁信号";
CM_ SG_ 664 PEPS_LockSignal "闭锁信号";
CM_ SG_ 664 PEPS_WLCM_Enable "无线充电使能信号";
CM_ SG_ 664 PEPS_UnlockSignal "解锁信号";
CM_ SG_ 664 PEPS_SmartTrunkUlockRemind "行李箱解锁提示";
CM_ SG_ 664 PEPS_Welcomelamp "智能迎宾功能";
CM_ SG_ 664 PEPS_Easy_open "PE体感信号";
CM_ SG_ 664 PEPS_KeyAuthenticationStatus "钥匙认证状态";
CM_ SG_ 664 PEPS_KeyNumber "钥匙编号";
CM_ SG_ 664 PEPS_LuggageUnlockSignal "行李箱解锁信号";
CM_ SG_ 664 PEPS_SearchCarSignal "寻车信号";
CM_ SG_ 664 PEPS_RemoteFailedAlarmSignal "钥匙认证失败报警信号";
CM_ SG_ 664 PEPS_EasyOpenOrginalSignal "脚步传感器触发信号";
CM_ SG_ 664 PEPS_KeyLearningSignal "钥匙学习成功信号";
CM_ SG_ 664 PEPS_TrunkRequestSignal "行李箱按钮状态信号";
BA_DEF_ BO_  "GenMsgILSupport" ENUM  "No","Yes";
BA_DEF_ SG_  "GenSigSendType" ENUM  "Cyclic","OnWrite","OnWriteWithRepetition","OnChange","OnChangeWithRepetition","NotUsed","NotUsed","NoSigSendType";

BA_DEF_ SG_  "GenSigEnvVarType" ENUM  "int","float","undef";
BA_DEF_ BO_ "NmMessage" ENUM "No","Yes";
BA_DEF_ BO_  "GenMsgCycleTime" INT 0 65535;
BA_DEF_ BO_  "GenMsgSendType" ENUM  "cyclic","event","spontaneous","cyclicIOnEvent","spontaneousWithDelay","cyclicAndEvent","cyclicAndSpontaneousWithDelay","spontaneousWithRepetition","cyclicIfActiveAndSpontaneousWD","FixedPeriodic";
BA_DEF_DEF_  "GenMsgILSupport" "Yes";
BA_DEF_DEF_  "GenSigSendType" "Cyclic";
BA_DEF_DEF_ "NmMessage" "Yes";

BA_DEF_DEF_  "GenSigEnvVarType" "undef";
BA_DEF_DEF_  "GenMsgCycleTime" 2;
BA_DEF_DEF_  "GenMsgSendType" "cyclic";
BA_ "GenMsgCycleTime" BO_ 407 50;
BA_ "GenMsgCycleTime" BO_ 391 100;
BA_ "GenMsgCycleTime" BO_ 384 50;
BA_ "GenMsgCycleTime" BO_ 591 100;
BA_ "GenMsgCycleTime" BO_ 382 100;
BA_ "GenMsgCycleTime" BO_ 368 100;
BA_ "GenMsgCycleTime" BO_ 586 100;
BA_ "GenMsgCycleTime" BO_ 585 100;
BA_ "GenMsgCycleTime" BO_ 509 40;
BA_ "GenMsgCycleTime" BO_ 824 100;
BA_ "GenMsgCycleTime" BO_ 588 100;
BA_ "GenMsgCycleTime" BO_ 438 100;
BA_ "GenMsgCycleTime" BO_ 424 50;
BA_ "GenMsgCycleTime" BO_ 392 100;
BA_ "GenMsgCycleTime" BO_ 853 100;
BA_ "GenMsgCycleTime" BO_ 837 100;
BA_ "GenMsgCycleTime" BO_ 776 100;
BA_ "GenMsgCycleTime" BO_ 726 100;
BA_ "GenMsgCycleTime" BO_ 618 50;
BA_ "GenMsgCycleTime" BO_ 422 50;
BA_ "GenMsgCycleTime" BO_ 406 50;
BA_ "GenMsgCycleTime" BO_ 388 100;
BA_ "GenMsgCycleTime" BO_ 747 50;
BA_ "GenMsgCycleTime" BO_ 630 40;
BA_ "GenMsgCycleTime" BO_ 1020 100;
BA_ "GenMsgCycleTime" BO_ 1022 100;
BA_ "GenMsgCycleTime" BO_ 851 200;
BA_ "GenMsgCycleTime" BO_ 850 200;
BA_ "GenMsgCycleTime" BO_ 849 100;
BA_ "GenMsgCycleTime" BO_ 1002 100;
BA_ "GenMsgCycleTime" BO_ 1682 500;
BA_ "GenMsgCycleTime" BO_ 982 100;
BA_ "GenMsgCycleTime" BO_ 984 100;
BA_ "GenMsgCycleTime" BO_ 1533 500;
BA_ "GenMsgCycleTime" BO_ 1535 100;
BA_ "GenMsgCycleTime" BO_ 1524 500;
BA_ "GenMsgCycleTime" BO_ 1510 0;
BA_ "GenMsgCycleTime" BO_ 1304 500;
BA_ "GenMsgCycleTime" BO_ 1298 0;
BA_ "GenMsgCycleTime" BO_ 1021 100;
BA_ "GenMsgCycleTime" BO_ 1023 100;
BA_ "GenMsgCycleTime" BO_ 1007 100;
BA_ "GenMsgCycleTime" BO_ 1000 100;
BA_ "GenMsgCycleTime" BO_ 999 100;
BA_ "GenMsgCycleTime" BO_ 989 100;
BA_ "GenMsgCycleTime" BO_ 942 100;
BA_ "GenMsgCycleTime" BO_ 938 100;
BA_ "GenMsgCycleTime" BO_ 918 100;
BA_ "GenMsgCycleTime" BO_ 912 500;
BA_ "GenMsgCycleTime" BO_ 905 200;
BA_ "GenMsgCycleTime" BO_ 903 100;
BA_ "GenMsgCycleTime" BO_ 902 1000;
BA_ "GenMsgCycleTime" BO_ 889 100;
BA_ "GenMsgCycleTime" BO_ 890 100;
BA_ "GenMsgCycleTime" BO_ 887 100;
BA_ "GenMsgCycleTime" BO_ 886 100;
BA_ "GenMsgCycleTime" BO_ 885 100;
BA_ "GenMsgCycleTime" BO_ 884 100;
BA_ "GenMsgCycleTime" BO_ 883 100;
BA_ "GenMsgCycleTime" BO_ 881 100;
BA_ "GenMsgCycleTime" BO_ 880 100;
BA_ "GenMsgCycleTime" BO_ 1668 0;
BA_ "GenMsgCycleTime" BO_ 1667 0;
BA_ "GenMsgCycleTime" BO_ 1310 500;
BA_ "GenMsgCycleTime" BO_ 839 500;
BA_ "GenMsgCycleTime" BO_ 664 40;
BA_ "NmMessage" BO_ 407 0;
BA_ "NmMessage" BO_ 391 0;
BA_ "NmMessage" BO_ 384 0;
BA_ "NmMessage" BO_ 591 0;
BA_ "NmMessage" BO_ 382 0;
BA_ "NmMessage" BO_ 368 0;
BA_ "NmMessage" BO_ 586 0;
BA_ "NmMessage" BO_ 585 0;
BA_ "NmMessage" BO_ 509 0;
BA_ "NmMessage" BO_ 824 0;
BA_ "NmMessage" BO_ 588 0;
BA_ "NmMessage" BO_ 438 0;
BA_ "NmMessage" BO_ 424 0;
BA_ "NmMessage" BO_ 392 0;
BA_ "NmMessage" BO_ 853 0;
BA_ "NmMessage" BO_ 837 0;
BA_ "NmMessage" BO_ 776 0;
BA_ "NmMessage" BO_ 726 0;
BA_ "NmMessage" BO_ 618 0;
BA_ "NmMessage" BO_ 422 0;
BA_ "NmMessage" BO_ 406 0;
BA_ "NmMessage" BO_ 388 0;
BA_ "NmMessage" BO_ 747 0;
BA_ "NmMessage" BO_ 630 0;
BA_ "NmMessage" BO_ 1020 0;
BA_ "NmMessage" BO_ 1022 0;
BA_ "NmMessage" BO_ 851 0;
BA_ "NmMessage" BO_ 850 0;
BA_ "NmMessage" BO_ 849 0;
BA_ "NmMessage" BO_ 1002 0;
BA_ "NmMessage" BO_ 1682 0;
BA_ "NmMessage" BO_ 982 0;
BA_ "NmMessage" BO_ 984 0;
BA_ "NmMessage" BO_ 1533 0;
BA_ "NmMessage" BO_ 1535 0;
BA_ "NmMessage" BO_ 1524 0;
BA_ "NmMessage" BO_ 1510 0;
BA_ "NmMessage" BO_ 1304 0;
BA_ "NmMessage" BO_ 1298 0;
BA_ "NmMessage" BO_ 1021 0;
BA_ "NmMessage" BO_ 1023 0;
BA_ "NmMessage" BO_ 1007 0;
BA_ "NmMessage" BO_ 1000 0;
BA_ "NmMessage" BO_ 999 0;
BA_ "NmMessage" BO_ 989 0;
BA_ "NmMessage" BO_ 942 0;
BA_ "NmMessage" BO_ 938 0;
BA_ "NmMessage" BO_ 918 0;
BA_ "NmMessage" BO_ 912 0;
BA_ "NmMessage" BO_ 905 0;
BA_ "NmMessage" BO_ 903 0;
BA_ "NmMessage" BO_ 902 0;
BA_ "NmMessage" BO_ 889 0;
BA_ "NmMessage" BO_ 890 0;
BA_ "NmMessage" BO_ 887 0;
BA_ "NmMessage" BO_ 886 0;
BA_ "NmMessage" BO_ 885 0;
BA_ "NmMessage" BO_ 884 0;
BA_ "NmMessage" BO_ 883 0;
BA_ "NmMessage" BO_ 881 0;
BA_ "NmMessage" BO_ 880 0;
BA_ "NmMessage" BO_ 1668 0;
BA_ "NmMessage" BO_ 1667 0;
BA_ "NmMessage" BO_ 1310 0;
BA_ "NmMessage" BO_ 839 0;
BA_ "NmMessage" BO_ 664 0;
BA_ "GenMsgSendType" BO_ 1510 1;
BA_ "GenMsgSendType" BO_ 1298 1;
BA_ "GenMsgSendType" BO_ 1668 1;
BA_ "GenMsgSendType" BO_ 1667 1;
VAL_ 884 ADS_RightPedWarnLevel 0 "nowarning " 1 "lightlyremind " 2 "moderatealram " 3 "collisionwarning " ;
VAL_ 884 ADS_RightPedDetection 0 "notdectected " 1 "onepedestriandectected " 2 "multiplepedestriansdectected " 3 "invalid " ;
VAL_ 884 ADS_LeftPedWarnLevel 0 "nowarning " 1 "lightlyremind " 2 "moderatealram " 3 "collisionwarning " ;
VAL_ 884 ADS_LeftPedDetection 0 "notdectected " 1 "onepedestriandectected " 2 "multiplepedestriansdectected " 3 "invalid " ;
VAL_ 884 ADS_HostPedWarnLevel_1 0 "nowarning " 1 "lightlyremind " 2 "moderatealram " 3 "collisionwarning " ;
VAL_ 407 EPB_Status 0 "bothbrakesreleased " 1 "bothbrakesapplied " 2 "bothbrakesinoperationapplying/releasing " 3 "unknown " ;
VAL_ 407 EPB_APArequest_Available 0 "notavailable " 1 "available " ;
VAL_ 407 EPB_SwitchPosition 0 "norequest " 1 "Releaserequest " 2 "Applyrequest " 3 "Error " ;
VAL_ 407 EPB_SwitchPositionValid 0 "validfullfunction " 1 "errorinitorsubstitutevaluenofunction " ;
VAL_ 407 EPB_FaultStoredInfo 0 "nofaultcodestored " 1 "faultcodestored " ;
VAL_ 407 EPB_FailStatus 0 "noerrorinEPB–externalapplyavailable " 1 "notdefined " 2 "notdefined " 3 "errorinEPB–noexternalapplyallowed " ;
VAL_ 391 ESP_ADBF_Active 0 "NotActive " 1 "Active " ;
VAL_ 391 ESP_VehicleSpeedValid 0 "Valid " 1 "NotValid " ;
VAL_ 391 ESP_EngTorqIncActive 0 "NotActive " 1 "Active " ;
VAL_ 391 ESP_EngTorqDecActive 0 "NotActive " 1 "Active " ;
VAL_ 391 ESP_ESPActiveStatus 0 "NotActive " 1 "Active " ;
VAL_ 391 ESP_ESPFunctionStatus 0 "OFF " 1 "ON " ;
VAL_ 391 ESP_EBDFailStatus 0 "Noerror " 1 "Error " ;
VAL_ 391 ESP_ABSFailStatus 0 "Noerror " 1 "Error " ;
VAL_ 391 ESP_TCSFailStatus 0 "Noerror " 1 "Error " ;
VAL_ 391 ESP_GearHoldRequestValid 0 "Valid " 1 "NotValid " ;
VAL_ 391 ESP_GearHoldRequest 0 "NotRequest " 1 "Request " ;
VAL_ 391 ESP_ABSActiveStatus 0 "NotActive " 1 "Active " ;
VAL_ 384 SAS_Calibrated 0 "Calibrated " 1 "NotCalibrated " ;
VAL_ 384 SAS_SASFailure 0 "NoFailure " 1 "Failure " ;
VAL_ 384 SAS_SteeringAngleValid 0 "Valid " 1 "Invalid " ;
VAL_ 591 EPS_ConcussAvailabilityStatus 0 "ConcussAvailability震动可用但是未震动 " 1 "ConcussActive震动激活中 " 2 "EPSConcussfailureEPS震动故障不可用 " 3 "reserved " ;
VAL_ 591 EPS_TorqueAssistMode 0 "Normal " 1 "light " 2 "heavy " 3 "unknow " ;
VAL_ 591 EPS__IACC_abortreason 0 "NODRIVINGINTERUPTION " 1 "DRIVERRECOVERYOverride " 2 "VEHICLESPEEDERROR " 3 "REQUESTERROR " 4 "DAETHERMALSECURITY " 5 "OTHERDEFAULT " 6 "Reserved " ;
VAL_ 591 EPS_APA_ControlFeedback 0 "Controldisable " 1 "Controlenabled " ;
VAL_ 591 EPS_TorqSensorStatus 0 "Normal " 1 "Abnormal " ;
VAL_ 591 EPS_APA_EpasFAILED 0 "NoFail " 1 "Fail " ;
VAL_ 591 EPS_ModeSwitchSt 0 "Nojudgment " 1 "Injudgment " ;
VAL_ 591 EPS_APA_Abortfeedback 0 "NODRIVINGINTERUPTION " 1 "DRIVERRECOVERY " 2 "TOOHIGHVEHICLESPEED " 3 "TOOIMPORTANTANGULARERROR " 4 "TOOIMPORTANTANGULARSPEEDERROR " 5 "DAETHERMALSECURITY " 6 "DAELIMITSECURITY " 7 "OTHERDEFAULT " ;
VAL_ 591 EPS_EPSFailed 0 "NoFail " 1 "Fail " ;
VAL_ 382 EPS_LatCtrlAvailabilityStatus 0 "notAvailability " 1 "Availability " 2 "failure " 3 "reserved " ;
VAL_ 382 EPS_LatCtrlActive 0 "NotActived " 1 "Actived " ;
VAL_ 382 EPS_MeasuredTorsionBarTorqValid 0 "可用 " 1 "不可用 " ;
VAL_ 586 ESL_UnLockButtonStatus 0 "normal " 1 "Reserve " 2 "Fault " 3 "Reserved " ;
VAL_ 586 ESL_DriverParkButtonStatus 0 "normal " 1 "Reserved " 2 "Fault " 3 "Reserved " ;
VAL_ 586 ESL_DriveModeStatus 0 "normal " 1 "Degraded " 2 "Fault " 3 "Reserved " ;
VAL_ 586 ESL_ShiftLeverStatus 0 "normal " 1 "Degraded " 2 "Limphome " 3 "Fault " ;
VAL_ 586 ESL_DriverParkRequest 0 "DriverParkNotRequested " 1 "DriverParkRequested " 2 "Reserved " 3 "Invalid " ;
VAL_ 586 ESL_UnLockButtonPosition 0 "NotPressed " 1 "Pressed " ;
VAL_ 585 ACM_ParkSelectIPReq 0 "NoDisplayrequest " 1 "OnlyShifttoParkwhenvehicleisstationary " ;
VAL_ 585 ACM_NotMatchMPosnIPReq 0 "NoDisplayrequest " 1 "MoveShiftLevertoright " ;
VAL_ 585 ACM_ShifterGearAPosnIPReq 0 "NoDisplayrequest " 1 "PressBraketomovetheshiftlever " 2 "PressUnlockButtontomovetheshiftlever " 3 "Reserved " ;
VAL_ 585 ACM_EngStartIPReq 0 "NoDisplayrequest " 1 "ToStartEnginePressbrake " 2 "ToStartEngineMoveShiftLevertoRight " 3 "Reserved " ;
VAL_ 585 ACM_ESLFaultIPReq 0 "NoDisplayrequest " 1 "ParkActuatorFault " ;
VAL_ 585 ACM_ARCFaultIPReq 0 "NoDisplayrequest " 1 "ParkActuatorFault " ;
VAL_ 585 ACM_APAdriverInterruption 0 "NoInterruption " 1 "Interruption " 2 "Reserved " 3 "invalid " ;
VAL_ 585 ACM_APA_Request_Enable 0 "norequest " 1 "Controlenabled " 2 "Controldisable " 3 "invalid " ;
VAL_ 585 ACM_ACMActuatorStatus 0 "normal " 1 "Fault " ;
VAL_ 585 ACM_ACMActuatorStatus_DCT 0 "Normal " 1 "Degraded " 2 "Limphome " 3 "ARCEngagedstucknopositionchangedandovercurrentdetected " 4 "ARCReleasedstucknopositionchangedandovercurrentdetected " 5 "ARC?stuckmiddlenopositionchangedandovercurrentdetected " 6 "FaultLossofmotordrivetorque " 7 "Reserved " ;
VAL_ 585 ACM_ActuatorPOrNoPStatus 0 "parkposition " 1 "active " 2 "Noparkposition " 3 "Invalid " ;
VAL_ 509 TCU_CrankingAuthEnable 0 "TCUisnotreadyforstartup " 1 "TCUisreadyforstartup " 2 "reserved " 3 "reserved " ;
VAL_ 824 TCU_DriveMode 0 "Initialvalue " 1 "Dmode " 2 "Cruisemode " 3 "WUSPmode " 4 "Sportmode " 5 "Altitudemode " 6 "UPHillmode " 7 "Hotmode " 8 "Wintermode " 9 "Manualmode " 10 "ManualHOTmode " 11 "EcoModel " 12 "DownHillMode " 13 "Reserved " 14 "Reserved " 15 "Invalid " ;
VAL_ 824 TCU_ARCFaultIPReq 0 "NoDisplayrequest " 1 "ParkActuatorFaultServiceRequired " ;
VAL_ 824 TCU_ESLFaultIPReq 0 "NoDisplayrequest " 1 "ShiftLevermalfunctionServiceRequired " ;
VAL_ 824 TCU_ParkSelectIPReq 0 "NoDisplayrequest " 1 "OnlyShifttoParkwhenvehicleisstationary " ;
VAL_ 824 TCU_ParkRelMPosnIPReq 0 "NoDisplayrequest " 1 "MoveShiftLevertoright " ;
VAL_ 824 TCU_ParkRelAPosnIPReq 0 "NoDisplayrequest " 1 "PressBraketoreleasepark " 2 "PressUnlockButtontoreleasepark " 3 "Reserved " ;
VAL_ 824 TCU_EngStartIPReq 0 "NoDisplayrequest " 1 "ToStartEnginePressbrake " 2 "ToStartEngineMoveShiftLevertoRight " 3 "Reserved " ;
VAL_ 824 TCU_BuzzerReq 0 "OFF " 1 "WarningA " 2 "WarningB " 3 "WarningC " 4 "WarningD " 5 "Notused " 6 "Notused " 7 "Notused " ;
VAL_ 824 TCU_GearIndication 0 "Normaldisplay " 1 "Blinkingdisplay " ;
VAL_ 824 TCU_GearForDisplay 0 "Reserved " 1 "1stgear " 2 "2ndgear " 3 "3rdgear " 4 "4thgear " 5 "5thgear " 6 "6thgear " 7 "Parking " 8 "Reverse " 9 "Neutral " 10 "Drange " 11 "Srange " 12 "7thgear " 13 "8thgear " 14 "Unreliable " 15 "Invalid " ;
VAL_ 824 TCU_ClearDiagnosticInfo 0 "Normal " 1 "Notused " 2 "TCMrequestECMTOClearP0700 " 3 "TCMhasclearedDiaginfoperECMrequest " ;
VAL_ 824 TCU_LinePressureFailureStatus 0 "Normal " 1 "Failure " ;
VAL_ 824 TCU_ShiftMapID 0 "Manual " 1 "Auto " 2 "Downhill " 3 "Uphill1 " 4 "Uphill2 " 5 "ECO " 6 "Sport " 7 "Cold " 8 "Catalyst " 9 "Altitude " 10 "AltitudeHill " 11 "Hot " 12 "HotUphill1 " 13 "HotUphill2 " 14 "Reserved " 15 "Invalid " ;
VAL_ 824 TCU_FanRequest 0 "NoRequest " 1 "ActivateLowCoolingFan " 2 "ActivateHighCoolingFan " 3 "Notused " ;
VAL_ 824 TCU_BrakeAssistRequestValid 0 "Invalid " 1 "Valid " ;
VAL_ 824 TCU_BrakeAssistRequest 0 "NotRequested " 1 "Requested " ;
VAL_ 824 TCU_ReqTranTempWarning 0 "nowarningrequest " 1 "Transmissionhot " 2 "Transmissionoverheat " 3 "transmissioncoldreservedforfuture " ;
VAL_ 824 TCU_FailureLamp 0 "OFF " 1 "ON " ;
VAL_ 824 TCU_CompressorDisableReq 0 "NotRequested " 1 "Requested " ;
VAL_ 588 TCU_ClutchBFillStatus 0 "NotFill " 1 "Filling " 2 "Fillcompleted " 3 "Invalid " ;
VAL_ 588 TCU_ClutchAFillStatus 0 "NotFill " 1 "Filling " 2 "Fillcompleted " 3 "Invalid " ;
VAL_ 588 TCU_HeavyDecelerationFlag 0 "OFF " 1 "ON " ;
VAL_ 588 TCU_NeutralControl 0 "Notactive " 1 "Active " ;
VAL_ 588 TCU_ReverseControl 0 "Notactive " 1 "Active " ;
VAL_ 588 TCU_VehicleSpeedDirection 0 "NegativeBackward " 1 "Standstill " 2 "Forward " 3 "Reversed " ;
VAL_ 588 TCU_ShaftPiercingTrigger 0 "OFF " 1 "ON " 2 "reserved " 3 "invalid " ;
VAL_ 588 TCU_APAClutchCtrlRequestEnable 0 "norequestreceived " 1 "Controlenabled " 2 "Controldisable " 3 "invalid " ;
VAL_ 588 TCU_APAShiftGearRequestEnable 0 "norequestreceived " 1 "Controlenabled " 2 "Controldisable " 3 "invalid " ;
VAL_ 438 TCU_ClutchStatus 0 "slip " 1 "Nonslip " 2 "Fullydisengaged " 3 "error " ;
VAL_ 438 TCU_CreepingEnable 0 "Notenable " 1 "Enable " ;
VAL_ 438 TCU_EngineSpeedReqType 0 "None " 1 "SpeedCtrl " 2 "IdleCtrl " 3 "Reserved " ;
VAL_ 424 TCU_EPBRequest 0 "Initialvalue " 1 "EPBengagementrequest " 2 "EPBreleaserequest " 3 "Norequest " ;
VAL_ 424 TCU_VehicleSpeedValid 0 "Valid " 1 "Invalid " ;
VAL_ 424 TCU_GearShiftPosition 0 "Parking " 1 "Reverse " 2 "Neutral " 3 "D " 4 "D3 " 5 "D2 " 6 "L " 7 "MorS " 8 "Reserved " 9 "Reserved " 10 "Reserved " 11 "Reserved " 12 "Reserved " 13 "Reserved " 14 "Unreliable " 15 "Invalid " ;
VAL_ 424 TCU_ShiftPositionValid 0 "Valid " 1 "Invalid " ;
VAL_ 424 TCU_ActualGear 0 "Neutral " 1 "1stgear " 2 "2ndgear " 3 "3rdgear " 4 "4tgear " 5 "5tgear " 6 "6tgear " 7 "7tgear " 8 "8tgear " 9 "Reverse " 10 "Parking " 11 "Reserved " 12 "Reserved " 13 "Reserved " 14 "Reserved " 15 "Invalid " ;
VAL_ 424 TCU_ActualGearValid 0 "Valid " 1 "Invalid " ;
VAL_ 424 TCU_TargetGear 0 "Neutral " 1 "1stgear " 2 "2ndgear " 3 "3rdgear " 4 "4tgear " 5 "5tgear " 6 "6tgear " 7 "7tgear " 8 "8tgear " 9 "Reverse " 10 "Parking " 11 "Reserved " 12 "Reserved " 13 "Reserved " 14 "Reserved " 15 "Invalid " ;
VAL_ 424 TCU_TargetGearValid 0 "Valid " 1 "Invalid " ;
VAL_ 424 TCU_STLKfailure 0 "normal " 1 "error " ;
VAL_ 424 TCU_MILReqStatus 0 "NotRequest " 1 "Request " ;
VAL_ 424 TCU_TransFailureStatus 0 "Normal " 1 "Failwithoutlimphomemode " 2 "Failwithlimphomemode " 3 "undefine " ;
VAL_ 392 TCU_StopStartInhibit 0 "FalseTCU " 1 "TrueTCU " ;
VAL_ 392 TCU_ReadyForAutoStop 0 "Falsenotreadyforautostop " 1 "TrueReadyforautostop " ;
VAL_ 392 TCU_OpenPowertrain 0 "False " 1 "True " ;
VAL_ 392 TCU_TorqRateLimitType 0 "Norequest无请求 " 1 "Increase上升斜率限制 " ;
VAL_ 392 TCU_TCUClutchStatus 0 "Notactive " 1 "Transient " 2 "Locked " 3 "Error " ;
VAL_ 392 TCU_ShiftinProgressValid 0 "Valid " 1 "Invalid " ;
VAL_ 392 TCU_ShiftinProgress 0 "Noshift " 1 "Shift " ;
VAL_ 392 TCU_TorqueReqmodel 0 "notorquerequest " 1 "TorqueIncreaseRequest " 2 "TorqueReductionRequest " 3 "Invalid " ;
VAL_ 853 EMS_CruiseControlStatus_355 0 "Off " 1 "Active " 2 "Standby " 3 "Error " ;
VAL_ 853 EMS_AgsErrorStateDisplay 0 "NoDisplay " 0 "Display " ;
VAL_ 853 EMS_ClearDiagnosticInfo 0 "Normal " 1 "Notused " 2 "ECMrequestTCMtoclear " 3 "ECMhascleareddiagintoperTCMrequest " ;
VAL_ 853 EMS_RemindShiftGear 0 "noprompt " 1 "upgear " 2 "downgear " 3 "invalid " ;
VAL_ 853 EMS_GPF_State 0 "默认值不显示 " 1 "GPF需要再生 " 2 "GPF正在再生 " 3 "GPF再生保护 " 4 "GPF堵塞无法再生 " 5 "reserved " 6 "reserved " 7 "invalid " ;
VAL_ 853 EMS_TankDoorSts 0 "close " 1 "open " ;
VAL_ 853 EMS_PFCCCondition 0 "NotAchieved " 1 "Achieved " ;
VAL_ 853 EMS_CruiseSwitchOnOff 0 "Off " 1 "On " ;
VAL_ 853 EMS_CruiseSwitchResume 0 "Inactive " 1 "Acitve " ;
VAL_ 853 EMS_CruiseSwitchCANCEL 0 "Inactive " 1 "Acitve " ;
VAL_ 853 EMS_CruiseSwitchSET 0 "Inactive " 1 "Acitve " ;
VAL_ 853 EMS_CruiseDistance 0 "Inactive " 1 "Acitve " ;
VAL_ 853 EMS_StartPrompt 0 "无提示 " 1 "踩离合器和制动踏板启动 " 2 "踩离合器启动 " 3 "预留 " ;
VAL_ 853 EMS_SVS 0 "OFF " 1 "ON " ;
VAL_ 853 EMS_MIL 0 "Off " 1 "ON " 2 "Reserved " 3 "Error " ;
VAL_ 853 EMS_CruiseIndicate 0 "OFF " 1 "ON " ;
VAL_ 853 EMS_IdleStopStatus 0 "非怠速停机状态 " ;
VAL_ 853 EMS_CruiseUnavailDisplay 0 "NODisplay " 1 "Display " ;
VAL_ 853 EMS_SSMWarningLampCtrol 0 "OFF " 1 "ON " ;
VAL_ 853 EMS_CruiseActiveIndicate 0 "OFF " 1 "ON " ;
VAL_ 837 EMS_BRSTextDsiplay 0 "无提示 " 1 "电量短暂不足 " 2 "靠边停车 " 3 "reserved " ;
VAL_ 837 EMS_BSGDrivingMode 0 "invalid " 1 "ECO " 2 "SPORT " 3 "resvered " ;
VAL_ 837 EMS_BRSFaultLamp 0 "OFF " 1 "ON " ;
VAL_ 776 EMS_ASLControlStatus 0 "Off " 1 "Active " 2 "Standby " 3 "Error " ;
VAL_ 776 EMS_ASLExceedTarSpdIndi 0 "OFF " 1 "ON " ;
VAL_ 776 EMS_ASLFaultsWarning 0 "OFF " 1 "ON " ;
VAL_ 776 EMS_Neutralgear 0 "NotNeutralGear " 1 "NeutralGear " 2 "Reserved " 3 "Invalid " ;
VAL_ 776 EMS_RemindGear 0 "NotUsed " 1 "1stgear " 2 "2stgear " 3 "3rdgear " 4 "4thgear " 5 "5thgear " 6 "6thgear " 7 "invalid " ;
VAL_ 776 EMS_IntakeAirTempSensorError 0 "Noerror " 1 "Error " ;
VAL_ 776 EMS_EEM_state 0 "NomalModel " 1 "LowVoltageModel " 2 "HighVotageMode " 3 "DecelerateState " 4 "AccelerateState " 5 "Stop " 6 "crank " 7 "reserved " ;
VAL_ 776 EMS_EEMErrorFlag 0 "NoError " 1 "Error " ;
VAL_ 776 EMS_ChrageLightState 0 "OFF " 1 "ON " ;
VAL_ 776 EMS_OilPressureSts 0 "noerror " 1 "error " ;
VAL_ 776 EMS_FuelCapLeakDisplay 0 "NoDisplay " 1 "Display " ;
VAL_ 726 EMS_EngineStartupEnd 0 "No " 1 "YES " ;
VAL_ 726 EMS_BatteryVoltageError 1 "Error " 0 "Noerror " ;
VAL_ 726 EMS_CoolanTemperatureError 1 "Error " 0 "Noerror " ;
VAL_ 726 EMS_ImmoConfiguration 0 "NoIMMO " 1 "IMMO " ;
VAL_ 726 EMS_ImmoFeedback 0 "Inactive " 1 "Authenticating " 2 "Success " 3 "Failed " ;
VAL_ 726 EMS_EngineLimpHome 0 "notLimpHome " 1 "LimpHome " ;
VAL_ 726 EMS_DrivingCycle 0 "notachieved " 1 "achieved " ;
VAL_ 726 EMS_WarmUpCycle 0 "notachieved " 1 "achieved " ;
VAL_ 726 EMS_CatalystWarmUp 0 "notrequest " 1 "request " ;
VAL_ 618 EMS_VacuumPressureValid 0 "Invalid " 1 "Valid " ;
VAL_ 618 EMS_ConditionIdle 0 "False " 1 "True " ;
VAL_ 618 EMS_EngineStatusWithSTT 0 "nonstart/stopmode " 1 "Enginestandby " 2 "EngineStopped " 3 "Starterrestart " 4 "Enginerestart " 5 "EngineOperation " 6 "Engineautostopping " 7 "idlestartnotavailable " ;
VAL_ 618 EMS_CompressorStatus 0 "OFF " 1 "ON " ;
VAL_ 618 EMS_KickDown 0 "OFF " 1 "ON " ;
VAL_ 618 EMS_CompressorWoE 0 "Unallow " 1 "Allow " ;
VAL_ 618 EMS_EngTorqQualityFlag 0 "Enginetorquestableandreliable " 1 "Enginetorquenotreliable " 2 "Enginetorquenotstablereliabilityislimited " 3 "Noenginetorquesignalvailable " ;
VAL_ 618 EMS_APAAccPedShieldStatus 0 "Unshield " 1 "Shield " ;
VAL_ 618 EMS_ECGPOvrd 0 "nooverride " 1 "driveroverride " ;
VAL_ 618 EMS_QECACC 3 "notdefined " 2 "irreversibleerror " 1 "reversibleerror " 0 "noerror " ;
VAL_ 618 EMS_AccReqPossible 0 "noerror " 1 "error " ;
VAL_ 618 EMS_confirmation_in_sport_mode 0 "No " 1 "Yes " ;
VAL_ 618 EMS_EVPActive 0 "OFF " 1 "ON " ;
VAL_ 422 EMS_IntakeManifoldPressureValid 0 "valid " 1 "invalid " ;
VAL_ 422 EMS_IGNPosition 0 "IGNOFF " 1 "IGNON " ;
VAL_ 422 EMS_EngineStatus 0 "Stop " 1 "Crank " 2 "Running " 3 "Reserved " ;
VAL_ 422 EMS_PTOpenReq 0 "PassiveEMS不干涉TCU控制传动链状态 " 1 "ActiveEMS要求TCU分离传动链 " ;
VAL_ 422 EMS_AutoStopRequest 0 "NorequestEMS不请求自动停机 " 1 "RequestEMS请求自动停机 " ;
VAL_ 422 EMS_CruiseControlStatus 0 "Off " 1 "Active " 2 "Standby " 3 "Error " ;
VAL_ 406 EMS_ClutchPedalStatus 0 "NotPressed " 1 "Pressed " 2 "Reserved " 3 "Error " ;
VAL_ 406 EMS_BrakePedalStatus 0 "NotPressed " 1 "Pressed " 2 "Reserved " 3 "Error " ;
VAL_ 406 EMS_APATorqRequestAvailable 0 "available " 1 "notavailable " ;
VAL_ 406 EMS_TCUTorqRequestAvailability 0 "Available " 1 "NotAvailable " ;
VAL_ 406 EMS_AccpedelError 0 "Noerror " 1 "Error " ;
VAL_ 406 EMS_ThrottleValvePositionError 0 "Noerror " 1 "Error " ;
VAL_ 406 EMS_EngineSpeedError 0 "Noerror " 1 "Error " ;
VAL_ 406 EMS_ESPTorqRequestAvailability 0 "Available " 1 "NotAvailabl " ;
VAL_ 406 EMS_EngineFuelCutOff 0 "False " 1 "True " ;
VAL_ 406 EMS_CreepingInhibitCommand 0 "Allow " 1 "Prohibit " ;
VAL_ 388 EMS_Torqquality 0 "Highfidelity " 1 "Reducedfidelity " ;
VAL_ 388 EMS_TorqFailure 1 "Failure " 0 "NoFailure " ;
VAL_ 388 EMS_SailingRequest 0 "NormalMode " 1 "Sailing " 2 "Sailingfaulty " 3 "Reserved " ;
VAL_ 747 HUD_FollowTargetDisplay_SetSts 0 "OFF " 1 "ON " ;
VAL_ 747 HUDBiasLightSetSts 0 "Inactive " 1 "标准模式 " 2 "雪地模式 " 3 "赛道模式 " ;
VAL_ 747 HUDRearIncomingVehicleSetSts 0 "Inactive " 1 "Off " 2 "On " 3 "Reserved " ;
VAL_ 747 HUDMovingTargetDetect_SetSts 0 "Inactive " 1 "Off " 2 "On " 3 "Reserved " ;
VAL_ 747 HUD_DisplayLDWSts 0 "invalid " 1 "display " 2 "nodisplay " 5 "Reserved " ;
VAL_ 747 HUD_DimAdjustSts 0 "invalid " 1 "level1 " 2 "level2 " 3 "level3 " 4 "level4 " 5 "level5 " ;
VAL_ 747 HUD_DisplayNavSts 0 "invalid " 1 "display " 2 "nodisplay " 3 "Reserved " ;
VAL_ 747 HUD_DisplayACCSts 0 "invalid " 1 "display " 2 "nodisplay " 4 "Reserved " ;
VAL_ 747 HUD_HUDEnableSts 0 "invalid " 1 "On " 2 "Off " 3 "Reserved " ;
VAL_ 747 HUD_ReqSendNextRoadName 0 "norequst " 1 "requst " ;
VAL_ 630 ESCL_SteeringLockError 0 "NoError " 1 "Error " ;
VAL_ 630 ESCL_SteeringLockWait 0 "Natural " 1 "WaitingError " ;
VAL_ 630 ESCL_SteeringLockStuck 0 "Natural " 1 "StuckError " ;
VAL_ 1020 PLG_CloseSpeedMode 0 "reserved " 1 "Mode1 " 2 "Mode2 " 3 "Mode3 " ;
VAL_ 1020 TrunkStopInstruct 0 "reserved " 1 "PEPS01暂停 " 2 "PEPS02暂停 " 3 "主驾侧尾门按钮暂停 " 4 "HU控制暂停 " 5 "脚踢暂停 " 6 "背门内饰板按钮关闭 " 7 "reserved " ;
VAL_ 1020 TrunkCloseInstruct 0 "reserved " 1 "PEPS01关闭 " 2 "PEPS02关闭 " 3 "主驾侧尾门按钮关闭 " 4 "HU控制关闭 " 5 "脚踢关闭 " 6 "背门内饰板按钮关闭 " 7 "随动功能关闭 " ;
VAL_ 1022 PLG_PinchPlayModeStatus 0 "Off " 1 "On " ;
VAL_ 1022 PLG_GateMotorStallStatus 0 "Off " 1 "On " ;
VAL_ 1022 PLG_GateMotorHeatProtectStatus 0 "Off " 1 "On " ;
VAL_ 1022 PLG_LatchMotorStallStatus 0 "Off " 1 "On " ;
VAL_ 1022 PLG_LatchMotorHeatProtectStatus 0 "Off " 1 "On " ;
VAL_ 1022 PLG_RatchetSwitch 0 "Close " 1 "Open " ;
VAL_ 1022 PLG_ResetSwitch 0 "Close " 1 "Open " ;
VAL_ 1022 PLG_PinchEventStatus 0 "Off " 1 "On " ;
VAL_ 1022 PLG_ApsStatus 0 "Off " 1 "On " ;
VAL_ 1022 PLG_PawlSwitch 0 "Close " 1 "Open " ;
VAL_ 1022 PLG_KickSensorStatus 0 "Noaction " 1 "Action " ;
VAL_ 1022 PLG_OpenCloseSwitch 0 "Noaction " 1 "Action " ;
VAL_ 1022 PLG_ShutfaceSwitch 0 "Noaction " 1 "Action " ;
VAL_ 1022 PLG_InitializedResult 0 "Ok " 1 "LearnFail " ;
VAL_ 1022 PLG_InitializeStatus 0 "Unlearned " 1 "Learned " ;
VAL_ 1022 PLG_LatchStatus 0 "Unkonw " 1 "Cinched " 2 "Releasing " 3 "ReleasingRest " 4 "Released " 5 "Cinching " 6 "CinchingRest " 7 "Reserved " ;
VAL_ 1022 PLG_OpenHeightLearningStatus 0 "Unlearn " 1 "Learned " ;
VAL_ 851 DSM_RestModeSaved_Request 0 "NORequest " 1 "Request " ;
VAL_ 851 DSM_HistoryRighttMirrorYPosition 15 "invalid " ;
VAL_ 851 DSM_HistoryRightMirrorXPosition 15 "invalid " ;
VAL_ 851 DSM_HistoryLeftMirrorYPosition 15 "invalid " ;
VAL_ 851 DSM_HistoryLeftMirrorXPosition 15 "invalid " ;
VAL_ 850 DSM_MirrorTurnSetFeedback 0 "invalid " 1 "off " 2 "on " 3 "Reserved " ;
VAL_ 850 DSM_RightMirrorStatus 0 "Invalid " 1 "Off " 2 "On " 3 "Error " ;
VAL_ 850 DSM_LeftMirrorStatus 0 "Invalid " 1 "Off " 2 "On " 3 "Error " ;
VAL_ 850 DSM_ComityFeedback 0 "无效 " 1 "前 " 2 "中 " 3 "后 " ;
VAL_ 850 DSM_PaPositionSaved_Request 0 "NORequest " 1 "驾驶位置保存请求 " 2 "休息位置保存请保存请求 " ;
VAL_ 850 DSM_MirrorPositionSaved_Request 0 "NORequest " 1 "后视镜驾驶位置保存请求 " 2 "倒车后视镜位置保存请求 " ;
VAL_ 850 DSM_CurrentLeftMirrorXPosition 15 "invalid " ;
VAL_ 850 DSM_CurrentLeftMirrorYPosition 15 "invalid " ;
VAL_ 850 DSM_CurrentRightMirrorXPosition 15 "invalid " ;
VAL_ 850 DSM_CurrentRighttMirrorYPosition 15 "invalid " ;
VAL_ 850 DSM_SetSuccessed 0 "NO " 1 "Memorysuccessed " 2 "Deletesuccessed " 3 "Invalid " ;
VAL_ 850 DSM_PositionStatus 0 "NO " 1 "InPosition " 2 "OutPosition " 3 "NoMemory " ;
VAL_ 850 DSM_DrPositionSaved_Request 0 "NORequest " 1 "驾驶位置保存请求 " 2 "休息位置保存请保存请求 " ;
VAL_ 850 DSMPaComitySwitchFeedbasck 0 "OFF " 1 "ON " ;
VAL_ 850 DSMDrComitySwitchFeedbasck 0 "OFF " 1 "ON " ;

VAL_ 849 DSM_MirrCurrentPosition_Status 0 "invalid " 1 "驾驶模式 " 2 "倒车模式 " 3 "Reserved " ;
VAL_ 849 DSM_MemoryPositionFB 0 "inactive " 1 "failed " 2 "successed " 3 "Reserved " ;
VAL_ 849 DSM_DrUpwardSwtich 0 "Nopress " 1 "press " ;
VAL_ 849 DSM_DrDownwardSwtich 0 "Nopress " 1 "press " ;
VAL_ 849 DSM_PaBackBackwardSwtich 0 "Nopress " 1 "press " ;
VAL_ 849 DSM_PaBackForwardSwtich 0 "Nopress " 1 "press " ;
VAL_ 849 DSM_PaSlideBackwardSwtich 0 "Nopress " 1 "press " ;
VAL_ 849 DSM_PaSlideForwardSwitch 0 "Nopress " 1 "press " ;
VAL_ 849 DSM_RightMirrRightwardSW 0 "Nopress " 1 "press " ;
VAL_ 849 DSM_RightMirrLeftwardSW 0 "Nopress " 1 "press " ;
VAL_ 849 DSM_RightMirrDownwardSW 0 "Nopress " 1 "press " ;
VAL_ 849 DSM_RightMirrUpwardSW 0 "Nopress " 1 "press " ;
VAL_ 849 DSM_LeftMirrRightwardSW 0 "Nopress " 1 "press " ;
VAL_ 849 DSM_LeftMirrLeftwardSW 0 "Nopress " 1 "press " ;
VAL_ 849 DSM_LeftMirrDownwardSW 0 "Nopress " 1 "press " ;
VAL_ 849 DSM_LeftMirrUpwardSW 0 "Nopress " 1 "press " ;
VAL_ 849 DSM_BackBackwardSwtich 0 "Nopress " 1 "press " ;
VAL_ 849 DSM_BackForwardSwitch 0 "Nopress " 1 "press " ;
VAL_ 849 DSM_SlideBackwardSwtich 0 "Nopress " 1 "press " ;
VAL_ 849 DSM_SlideForwardSwitch 0 "Nopress " 1 "press " ;
VAL_ 849 DSM_DSMMemoryPosition 0 "NoRequest " 1 "Request " 2 "Reserved " 3 "Reserved " ;
VAL_ 849 DSM_KeyMomerySts 0 "inactive " 1 "off " 2 "on " 3 "Reserved " ;
VAL_ 849 DSM_MemoryAlarm 0 "invalid " 1 "failed " 2 "successed " 3 "Reserved " ;
VAL_ 1002 FSCM_DrHeatSts 0 "NoReq " 1 "Level1 " 2 "Level2 " 3 "Level3 " 4 "AutoMode " 5 "Reserved " 6 "Off " 7 "Reserved " ;
VAL_ 1002 FSCM_PaHeatSts 0 "NoReq " 1 "Level1 " 2 "Level2 " 3 "Level3 " 4 "AutoMode " 5 "Reserved " 6 "Off " 7 "Reserved " ;
VAL_ 982 BCM_FRWindowStatus 255 "Invalid " ;
VAL_ 982 BCM_RRWindowStatus 255 "Invalid " ;
VAL_ 982 BCM_FRWindowInitializedSts 0 "DeInitialized " 1 "Initialized " ;
VAL_ 982 BCM_RRWindowInitializedSts 0 "DeInitialized " 1 "Initialized " ;
VAL_ 982 BCM_FRWindowAPActice 0 "Inactive " 1 "Active " ;
VAL_ 982 BCM_RRWindowAPActice 0 "Inactive " 1 "Active " ;
VAL_ 982 BCM_FRWinMotor 0 "Stopped " 1 "Windowclose " 2 "Windowopen " 3 "Reserved " ;
VAL_ 982 BCM_RRWinMotor 0 "Stopped " 1 "Windowclose " 2 "Windowopen " 3 "Reserved " ;
VAL_ 984 BCM_FailStatus 0 "Noerror " 1 "Error " ;
VAL_ 984 BCM_DriverWindowStatus 255 "Invalid " ;
VAL_ 984 BCM_RLWindowStatus 255 "Invalid " ;
VAL_ 984 BCM_DriverWindowInitializedSts 0 "DeInitialized " 1 "Initialized " ;
VAL_ 984 BCM_RLWindowInitializedSts 0 "DeInitialized " 1 "Initialized " ;
VAL_ 984 BCM_DriverWindowAPActice 0 "Inactive " 1 "Active " ;
VAL_ 984 BCM_RLWindowAPActice 0 "Inactive " 1 "Active " ;
VAL_ 984 BCM_DriverWinMotor 0 "Stopped " 1 "Windowclose " 2 "Windowopen " 3 "Reserved " ;
VAL_ 984 BCM_RLWinMotor 0 "Stopped " 1 "Windowclose " 2 "Windowopen " 3 "Reserved " ;
VAL_ 984 BCM_DoorlockSwitchStatus 0 "notrequest " 1 "lockrequest " 2 "unlockrequest " 3 "invalid " ;
VAL_ 984 BCM_WindowlockSwitchStatus 0 "notrequest " 1 "lockrequest " 2 "unlockrequest " 3 "invalid " ;
VAL_ 1533 BCM_FBLRemoteSts 0 "notactive " 1 "执行远程启动中 " ;
VAL_ 1533 BCM_FBLBatterySts 0 "蓄电池剩余电量满足刷写 " 1 "蓄电池剩余电量不满足刷写 " ;
VAL_ 1533 BCM_FBLEngineSts 0 "发动机STOP " 1 "发动机非STOP状态 " ;
VAL_ 1533 BCM_FBLVehicleSpeedSts 0 "车速为零 " 1 "车速非零 " ;
VAL_ 1533 BCM_FBLShiftSts 0 "换挡器在P档 " 1 "换挡器非P档 " ;
VAL_ 1533 BCM_FBLPowerReqFeedback 0 "非刷写档位 " 1 "刷写档位 " 2 "Reserved " 3 "Reserved " 4 "Reserved " 5 "Reserved " 6 "Reserved " 7 "Invalid " ;
VAL_ 1533 BCM_FBLhandbreakSts 0 "手刹拉起 " 1 "手刹非拉起状态 " ;
VAL_ 1535 BCM_LatchOverheatProtect 0 "OFF " 1 "ON " ;
VAL_ 1535 BCM_LockAutoClsSunroofSetStatus 0 "inactive " 1 "on " 2 "off " 3 "reserved " ;
VAL_ 1535 BCM_RemoteCtrlSunroofSetStatus 0 "invalid " 1 "off " 2 "on " 3 "Reserved " ;
VAL_ 1535 BCM_RemoteControlWindowSetStatus 0 "invalid " 1 "off " 2 "on " 3 "Reserved " ;
VAL_ 1535 BCM_RemoteControlSwtichSetStatus 0 "invalid " 1 "LightandSound " 2 "onlyLight " 3 "onlySound " 4 "车外语音拟声加闪灯 " 5 "仅车外语音拟声 " 6 "Reserved " 7 "Reserved " ;
VAL_ 1535 BCM_CarWashMirrorFoldFeedback 0 "Invalid " 1 "OFF " 2 "ON " 3 "Reserved " ;
VAL_ 1535 BCM_MirrorAutoFoldSetStatus 0 "inactive " 1 "off " 2 "on " 3 "Reserved " ;
VAL_ 1535 BCM_RearWiperSetStatus 0 "invalid " 1 "off " 2 "on " 3 "Reserved " ;
VAL_ 1535 BCM_CarRemindFeedback 0 "NoFeedback " 1 "成功 " 2 "非OFF档 " 3 "Invalid " ;
VAL_ 1535 LCM_MirrorAutoFoldSetStatus 0 "invalid " 1 "off " 2 "on " 3 "Reserved " ;
VAL_ 1535 PEPS_SmartTrunkUlockStaus 0 "inactive " 1 "On " 2 "Off " 3 "Reserved " ;
VAL_ 1535 PEPS_Smartlockstatus 0 "invalid " 1 "off " 2 "on " 3 "Reserved " ;
VAL_ 1535 PEPS_SmartUnlockstatus 0 "invalid " 1 "off " 2 "on " 3 "Reserved " ;
VAL_ 1535 PEPS_HandleProximitySensorSignal 0 "OFF " 1 "感应开关解锁有效 " 2 "感应开关闭锁有效 " 3 "感应开关解锁闭锁同时有效 " ;
VAL_ 1535 PEPS_KeyBatteryStatus 0 "Inactive " 1 "EXchangeKeyBattery " ;
VAL_ 1535 PEPS_KeyUndetectedAlarmSignal 0 "Inactive " 1 "ON " ;
VAL_ 1535 PEPS_KeyInCarAlarmSignal 0 "Inactive " 1 "ON " ;
VAL_ 1535 PEPS_UnlockModeTransitionSignal 0 "Inactive " 1 "Exchange " ;
VAL_ 1535 PEPS_DoorHandleButtonSignal 0 "OFF " 1 "驾驶侧门按钮被按下 " ;
VAL_ 1535 PEPS_GreetLampFB 0 "无反馈 " 1 "钥匙10分钟持续在车辆迎宾区域 " 2 "洗车模式禁用 " 3 "用户设置无迎宾 " 4 "停车超过3天 " 5 "车辆迎宾解锁未开门3次 " 6 "用户设置开启迎宾 " 7 "锁动作过程中 " ;
VAL_ 1535 BCM_KeyInSignal 0 "KeyOut " 1 "KeyIn " ;
VAL_ 1535 PEPS_PeScanDoorStatus 0 "DoorClose " 1 "DoorOpen " ;
VAL_ 1535 PEPS_KeyPositionStatus 0 "未探测到钥匙 " 1 "钥匙在车内 " 2 "钥匙在行李箱内 " 3 "钥匙在左前门激活区 " 4 "钥匙在行李箱激活区 " 5 "钥匙在右前门激活区 " 6 "钥匙在车外迎宾区 " 7 "Invalid " ;
VAL_ 1535 BCM_AutoLeaveLockSetStatus 0 "Inactive " 1 "Close " 2 "30s " 3 "60s " 4 "120s " 5 "180s " 6 "240s " 7 "300s " ;
VAL_ 1535 BCM_TwiceLockDoorSetStatus 0 "inactive " 1 "On " 2 "Off " 3 "Reserved " ;
VAL_ 1535 BCM_RmoteLockFeedback 0 "NoFeedback也用于人脸识别反馈 " 1 "四门闭锁成功也用于人脸识别反馈 " 2 "车门未关 " 3 "行李箱未关 " 4 "非OFF档 " 5 "热保护 " 6 "行李箱闭锁成功 " 7 "Reserved " ;
VAL_ 1535 BCM_AutoSpeedLockSetStatus 0 "invalid " 1 "off " 2 "on " 3 "Reserved " ;
VAL_ 1535 BCM_AutoParkUnlockSetStatus 0 "invalid " 1 "off " 2 "on " 3 "Reserved " ;
VAL_ 1535 BCM_RKEUnlockDoorTypeSetStatus 0 "invalid " 1 "Unlockfourdoor " 2 "UnlockDriverdoor " 3 "Reserved " ;
VAL_ 1535 BCM_AutoLockFeedback 0 "inactive " 1 "success " 2 "fail " 3 "Reserved " ;
VAL_ 1304 BCM_FuelPotentialCond 0 "正常工况 " 1 "升档 " 2 "降档 " 3 "急加速 " 4 "高速 " 5 "驻车长怠速 " 6 "空踩油门 " 7 "半离合急加速 " 8 "空档滑行 " 9 "半离合行车 " 10 "油门刹车同时踩 " 11 "STT工作工况 " 12 "急减速 " 31 "Invalid " ;
VAL_ 1304 BCM_RoutineID 0 "车辆未运行 " ;
VAL_ 1304 BCM_CarMode 0 "车辆处于用户模式 " 1 "车辆处于工厂模式 " 2 "车辆处于运输模式 " 3 "车辆处于工厂调试模式 " ;
VAL_ 1304 BCM_BrakeAccChangeQCond 0 "无效 " 1 "有效 " ;
VAL_ 1304 BCM_EmergSteerCond 0 "无效 " 1 "有效 " ;
VAL_ 1021 HU_EPSTorqueMode 0 "normal " 1 "light " 2 "heavy " 3 "reserved " ;
VAL_ 1023 BCM_RainOpenLightStatus 0 "Inactive " 1 "Off " 2 "On " 3 "Reserved " ;
VAL_ 1023 BCM_AutoturnlightovertakemodeSetSts 0 "inactive " 1 "OFF " 2 "ON " 3 "Reserved " ;
VAL_ 1023 BCM_LightingDoorOpenWarningStatus 0 "inactive " 1 "OFF " 2 "ON " 3 "Reserved " ;
VAL_ 1023 BCM_LightingBackwardWarningStatus 0 "inactive " 1 "OFF " 2 "ON " 3 "Reserved " ;
VAL_ 1023 BCM_RearLeftTuningLightFaultSts 0 "Normal " 1 "Fault " ;
VAL_ 1023 BCM_HighBeamLampError 0 "Noerror " 1 "error " ;
VAL_ 1023 BCM_AutoHeadlightSetSts 0 "OFF " 1 "ON " ;
VAL_ 1023 BCM_FollowMeHomeLightSetStatus 0 "inactive " 1 "OFF " 2 "15s " 3 "30s " 4 "60s " 5 "120s " 6 "Reserved " 7 "Reserved " ;
VAL_ 1023 BCM_DRLSts 0 "NotActived " 1 "Actived " ;
VAL_ 1023 BCM_PositionLampSwitchStatus 0 "Off " 1 "On " ;
VAL_ 1023 BCM_TurnIndicatorLeftError 0 "无故障 " 1 "有故障 " ;
VAL_ 1023 BCM_TurnIndicatorRightError 0 "无故障 " 1 "有故障 " ;
VAL_ 1023 BCM_RearRightTuningLightFaultSts 0 "Normal " 1 "Fault " ;
VAL_ 1023 BCM_CHMLampError 0 "无故障 " 1 "有故障 " ;
VAL_ 1023 BCM_ReverseLampError 0 "无故障 " 1 "有故障 " ;
VAL_ 1023 BCM_LeftDayLampError 0 "无故障 " 1 "有故障 " ;
VAL_ 1023 BCM_RightDayLampError 0 "无故障 " 1 "有故障 " ;
VAL_ 1023 BCM_LeftPositionLampError 0 "无故障 " 1 "有故障 " ;
VAL_ 1023 BCM_RightPositionLampError 0 "无故障 " 1 "有故障 " ;
VAL_ 1023 BCM_ReverseLightSts 0 "OFF " 1 "ON " 2 "Notused " 3 "Error " ;
VAL_ 1023 BCM_RearPositionLampError 0 "无故障 " 1 "有故障 " ;
VAL_ 1023 BCM_LeftLowBeamError 0 "无故障 " 1 "有故障 " ;
VAL_ 1023 BCM_RightLowBeamError 0 "无故障 " 1 "有故障 " ;
VAL_ 1023 BCM_LeftFrontFoglampError 0 "无故障 " 1 "有故障 " ;
VAL_ 1023 BCM_RightFrontFoglampError 0 "无故障 " 1 "有故障 " ;
VAL_ 1023 BCM_LeftRearFoglampError 0 "无故障 " 1 "有故障 " ;
VAL_ 1023 BCM_RightRearFoglampError 0 "无故障 " 1 "有故障 " ;
VAL_ 1023 BCM_BrakeLampError 0 "无故障 " 1 "有故障 " ;
VAL_ 1023 BCM_PositionLampStatus 0 "OFF " 1 "ON " 2 "Notused " 3 "Reserved " ;
VAL_ 1023 BCM_RearFoglampStatus 0 "OFF " 1 "ON " 2 "Notused " 3 "Error " ;
VAL_ 1023 BCM_FrontFoglampStatus 0 "OFF " 1 "ON " 2 "Notused " 3 "Reserved " ;
VAL_ 1023 BCM_AutoHeadlightSts 0 "NotActived " 1 "Actived " ;
VAL_ 1023 BCM_FrontPositionLampError 0 "无故障 " 1 "有故障 " ;
VAL_ 1023 BCM_Musiclightfeedback 0 "inactive " 1 "enter " 2 "exit " 3 "Reserved " ;
VAL_ 1023 BCM_FollowMeTurnon 0 "OFF " 1 "ON " ;
VAL_ 1023 BCM_MusicLightModeSelectSts 0 "Inactive " 1 "LightMode1 " 2 "LightMode2 " 3 "LightMode3 " 4 "LightMode4 " 5 "LightMode5 " 6 "LightMode6 " 7 "LightMode7 " ;
VAL_ 1023 BCM_MusicPlayRequestSignal 0 "inactive " 1 "start " 2 "end " 3 "illegal " ;
VAL_ 1007 BCM_Interactive_switch_Status 0 "Inactive " 1 "ON " 2 "Off " 3 "Reseved " ;
VAL_ 1007 BCM_ALCEnableStatus 0 "inactive " 1 "Off " 2 "On " 3 "Reserved " ;
VAL_ 1007 BCM_SenseBlossomEnable 0 "inactive " 1 "Off " 2 "On " 3 "Reserved " ;
VAL_ 1007 BCM_AtmoLightAAEnableSts 0 "inactive " 1 "On " 2 "Off " 3 "Reserved " ;
VAL_ 1007 BCM_AtmoLightLinkDoorEnableSts 0 "inactive " 1 "Off " 2 "On " 3 "Reserved " ;
VAL_ 1007 BCM_AtmoLightLinkDriveModeSts 0 "inactive " 1 "Off " 2 "On " 3 "Reserved " ;
VAL_ 1007 BCM_AtmoLightSceneMode_FeedBack 0 "Norequest " 1 "满足 " 2 "不满足 " 3 "reserved " ;
VAL_ 1007 BCM_SenseAQIEnable 0 "inactive " 1 "Off " 2 "On " 3 "Reserved " ;
VAL_ 1007 BCM_AtmoLightOverspeedEnableSts 0 "inactive " 1 "Off " 2 "On " 3 "Reserved " ;
VAL_ 1007 BCM_AtmoLightLinkStartEnableSts 0 "inactive " 1 "Off " 2 "On " 3 "Reserved " ;
VAL_ 1007 BCM_WelcomeAtmoLightEnableSts 0 "inactive " 1 "Off " 2 "On " 3 "Reserved " ;
VAL_ 1007 BCM_SEWEnableSts 0 "inactive " 1 "Off " 2 "On " 3 "Reserved " ;
VAL_ 1007 BCM_RoomLightControlSts 0 "Inactive " 1 "Off " 2 "On " 3 "Reserved " ;
VAL_ 1007 BCM_SetDoorLightStatus 0 "Inactive " 1 "ON " 2 "Off " 3 "Reseved " ;
VAL_ 1007 BCM_AtmosphereLightswitchSetStatus 0 "Invalid " 1 "OFF " 2 "ON " 3 "Auto " ;
VAL_ 1007 BCM_AtmoLightTopLightEnableSts 0 "inactive " 1 "Off " 2 "On " 3 "Reserved " ;
VAL_ 1000 BCM_SOF_t_STATE 0 "deviation15 " 1 "deviation15 " 2 "deviation10 " 3 "invalid " ;
VAL_ 1000 BCM_SOF_V2_STATE 0 "deviation15 " 1 "deviation15 " 2 "deviation10 " 3 "invalid " ;
VAL_ 1000 BCM_SOF_V1_STATE 0 "deviation800mV " 1 "deviation400mV " 2 "deviation400mV " 3 "invalid " ;
VAL_ 1000 BCM_SOF_Q_STATE 0 "deviation15 " 1 "deviation15 " 2 "deviation10 " 3 "invalid " ;
VAL_ 1000 BCM_SOC_STATE 0 "deviation15 " 1 "deviation15 " 2 "deviation10 " 3 "invalid " ;
VAL_ 1000 BCM_SOF_t 1023 "Invalid " ;
VAL_ 1000 BCM_SOF_V2 255 "Invalid " ;
VAL_ 1000 BCM_SOF_V1 255 "Invalid " ;
VAL_ 1000 BCM_SOF_Q 255 "Invalid " ;
VAL_ 999 BCM_FLAG_INCONSISTENCY 0 "nobatteryinconsistency " 1 "batteryinconsistency " ;
VAL_ 999 BCM_Resp_Error 0 "Noerror " 1 "Error " ;
VAL_ 999 BCM_ERROR_IDENT 0 "Noerror " 1 "Error " ;
VAL_ 999 BCM_ERROR_Calib 0 "Noerror " 1 "Error " ;
VAL_ 999 BCM_Status_Temp 0 "Noerror " 1 "notused " 2 "HWdefectADCdefect " 3 "LINsaturationnoHWdefect " ;
VAL_ 999 BCM_Status_Voltage 0 "Noerror " 1 "ErrorOpencircuit " 2 "HWdefectADCdefect " 3 "LINsaturationnoHWdefect " ;
VAL_ 999 BCM_Status_Current 0 "Noerror " 1 "ErrorOpencircuit " 2 "HWdefectADCdefect " 3 "LINsaturationnoHWdefect " ;
VAL_ 999 BCM_IBATT_QUIESCENT 253 "Overflow " 254 "Outofbounds " 255 "Invalid " ;
VAL_ 999 BCM_I_RANGE 0 "currentRange11A " 1 "currentRange200200A " 2 "currentRange15001500A " 3 "unsigned " ;
VAL_ 989 BCM_RLWindowAPActice 0 "Inactive " 1 "Active " ;
VAL_ 989 BCM_DriverWindowAPActice 0 "Inactive " 1 "Active " ;
VAL_ 989 BCM_RLWindowInitializedSts 0 "DeInitialized " 1 "Initialized " ;
VAL_ 989 BCM_DriverWindowInitializedSts 0 "DeInitialized " 1 "Initialized " ;
VAL_ 989 BCM_RRWindowAPActice 0 "Inactive " 1 "Active " ;
VAL_ 989 BCM_PassengerWindowAPActice 0 "Inactive " 1 "Active " ;
VAL_ 989 BCM_RRWindowInitializedSts 0 "DeInitialized " 1 "Initialized " ;
VAL_ 989 BCM_FRWindowInitializedSts 0 "DeInitialized " 1 "Initialized " ;
VAL_ 989 BCM_LeftRearWinMotor 0 "OFF " 1 "Running " 2 "Notused " 3 "ErrorReserved " ;
VAL_ 989 BCM_DriverWinMotor 0 "OFF " 1 "Running " 2 "Notused " 3 "ErrorReserved " ;
VAL_ 989 BCM_RightRearWinMotor 0 "OFF " 1 "Running " 2 "Notused " 3 "ErrorReserved " ;
VAL_ 989 BCM_PassengerWinMotor 0 "OFF " 1 "Running " 2 "Notused " 3 "ErrorReserved " ;
VAL_ 989 BCM_LeftRearWindowStatus 255 "Invalid " ;
VAL_ 989 BCM_DriverWindowStatus 255 "Invalid " ;
VAL_ 989 BCM_RightRearWindowStatus 255 "Invalid " ;
VAL_ 989 BCM_PassengerWindowStatus 255 "Invalid " ;
VAL_ 938 BCM_DriverDoorHandleStatus 0 "无效 " 1 "展开位置 " 2 "收回位置 " 3 "预留 " ;
VAL_ 938 BCM_LeftRearDoorHandleStatus 0 "无效 " 1 "展开位置 " 2 "收回位置 " 3 "预留 " ;
VAL_ 938 BCM_PassengeDoorHandleStatus 0 "无效 " 1 "展开位置 " 2 "收回位置 " 3 "预留 " ;
VAL_ 938 BCM_RightRearDoorHandleStatus 0 "无效 " 1 "展开位置 " 2 "收回位置 " 3 "预留 " ;
VAL_ 918 BCM_Sunroof_Intialized 0 "Inactive " 1 "Active " ;
VAL_ 918 BCM_RemoteWindowFeedback 0 "NoRequest " 1 "RemoteCloseSuccess " 2 "RemoteOpenSuccess " 3 "门未关 " 4 "车窗未学习 " 5 "LIN线故障 " 6 "Reserve " 7 "Invalid " ;
VAL_ 918 BCM_AerationHintReq 0 "Inactive " 1 "On " 2 "Off " 3 "Reserved " ;
VAL_ 918 BCM_Sunroof_APActive 0 "Inactive " 1 "Active " ;
VAL_ 918 PEPS_RemoteWindowUpSignal 0 "Inactive " 1 "ON " ;
VAL_ 918 PEPS_RemoteWindowDownSignal 0 "Inactive " 1 "ON " ;
VAL_ 918 BCM_RemoteWindowUpSetStaus 0 "invalid " 1 "off " 2 "On " 3 "Reserved " ;
VAL_ 918 BCM_RemoteWindowDownSetStaus 0 "inactive " 1 "off " 2 "open " 3 "Reserved " ;
VAL_ 918 BCM_AutoCloseWindow 0 "inactive " 1 "success " 2 "fail " 3 "reserved " ;
VAL_ 918 BCM_WinOpenWarn 0 "inactive " 1 "warning " ;
VAL_ 918 BCM_WinUpCfgSts 0 "不带遥控功能 " 1 "遥控长按上升模式 " 2 "遥控一键上升模式 " 3 "无效值 " ;
VAL_ 918 BCM_LockAutoClsWinSetStatus 0 "inactive " 1 "on " 2 "off " 3 "reserved " ;
VAL_ 918 BCM_SunroofMotor 0 "OFF " 1 "Running " 2 "Notused " 3 "ErrorReserved " ;
VAL_ 918 BCM_Sunroof_Position 0 "fullyup全起翘 " 1 "tiltstop起翘段 " 2 "reserved " 3 "fullyclose（全关） " 4 "reserved " 5 "slidestop（平移段开） " 6 "fullyopen（全开） " 7 "DegradeMode（降级模式半初始化状态） " ;
VAL_ 918 BCM_RainCtrlSunRoofSetStatus 0 "inactive " 1 "off " 2 "on " 3 "Reserved " ;
VAL_ 918 BCM_Sunshade_Movement 0 "stopped " 1 "openingslide " 2 "closingslide " 3 "reversingAP/Stall " 4 "movinguninitialized " ;
VAL_ 918 BCM_Sunroof_Movement 0 "stopped " 1 "openingtilt " 2 "closingtilt " 3 "openingslide " 4 "closingslide " 5 "reversingAP/Stall " 6 "movinguninitialized " 7 "reserved " ;
VAL_ 918 BCM_Sunroof_POS_Direction 0 "horizontal " 1 "vertical " ;
VAL_ 918 BCM_SunroofStatus 0 "Close " 1 "Open " ;
VAL_ 912 BCM_PMSErrorFlag 0 "normal " 1 "Error1 " 2 "Erro2 " 3 "Error3 " ;
VAL_ 905 BCM_ValetModelFeedback 0 "Inactive " 1 "LocalAuthorizationModel " 2 "RemoteAuthorizationModel " 3 "NotActive " 4 "LocalAuthorizationModelOFF " 5 "RemoteAuthorizationModelOFF " 6 "检测到钥匙退出 " 7 "Reserved " ;
VAL_ 905 BCM_BrakePedalStatus 0 "NotPressed " 1 "Pressed " 2 "Reserved " 3 "Invalid " ;
VAL_ 905 BCM_WindowContralSta 0 "Uncontrollable " 1 "Controllable " ;
VAL_ 905 BCM_WiperForbiddenSta 0 "不禁用 " 1 "洗车模式禁用 " ;
VAL_ 905 BCM_WiperServiceReqStatus 0 "Inactive " 1 "Acitve " ;
VAL_ 905 BCM_RearWiperPosition 0 "WiperReturned " 1 "OnTheGlass " ;
VAL_ 905 BCM_FrontWiperPosition 0 "WiperReturned " 1 "OnTheGlass " ;
VAL_ 905 BCM_TrumpetSwitchStatus 0 "NotPressed " 1 "Pressed " ;
VAL_ 905 BCM_EmergencyLightSwitchStatus 0 "notrequest " 1 "OFF " 2 "ON " 3 "invalid " ;
VAL_ 905 BCM_FrontFoglampSwitchStatus 0 "notrequest " 1 "OFF " 2 "ON " 3 "invalid " ;
VAL_ 905 BCM_OverTakeLightSwitchStatus 0 "notrequest " 1 "OFF " 2 "ON " 3 "invalid " ;
VAL_ 905 BCM_FrontWiperSensibility 0 "Reserved " 1 "等级1 " 2 "等级2 " 3 "等级3 " 4 "等级4 " 5 "等级5 " ;
VAL_ 905 BCM_FrontWiperIntervalTime 0 "OFF " 1 "1s " 2 "35s " 3 "6s " 4 "95s " 5 "155s " 6 "22s " 7 "notused " ;
VAL_ 905 BCM_CarWashModelstatus 0 "invalid " 1 "off " 2 "on " 3 "车速过高关闭 " ;
VAL_ 905 BCM_SunshadeSwitchStatus 0 "notrequest " 1 "OFF " 2 "ON " 3 "invalid " ;
VAL_ 905 BCM_SunRoofSwitchStatus 0 "notrequest " 1 "OFF " 2 "ON " 3 "invalid " ;
VAL_ 905 BCM_RearMirrorFoldStatus 0 "notrequest " 1 "OFF " 2 "ON " 3 "invalid " ;
VAL_ 905 BCM_RightRearWindowSwitchStatus1 0 "notrequest " 1 "manuallyuprequest " 2 "downrequest " 3 "selfmotionuprequset " ;
VAL_ 905 BCM_LeftRearWindowSwitchStatus1 0 "notrequest " 1 "manuallyuprequest " 2 "downrequest " 3 "selfmotionuprequset " ;
VAL_ 905 BCM_PassengerWindowSwitchStatus1 0 "notrequest " 1 "manuallyuprequest " 2 "downrequest " 3 "selfmotionuprequset " ;
VAL_ 905 BCM_RoofLampDoorSwitchStatus 0 "notrequest " 1 "OFF " 2 "ON " 3 "invalid " ;
VAL_ 905 BCM_AutoHeadlightSwitchStatus 0 "notrequest " 1 "OFF " 2 "ON " 3 "invalid " ;
VAL_ 905 BCM_RearWashSwitchStatus 0 "notrequest " 1 "OFF " 2 "ON " 3 "invalid " ;
VAL_ 905 BCM_FrontWashSwitchStatus 0 "notrequest " 1 "OFF " 2 "ON " 3 "invalid " ;
VAL_ 905 BCM_LowBeamSwitchStatus 0 "notrequest " 1 "OFF " 2 "ON " 3 "invalid " ;
VAL_ 905 BCM_HighBeamSwitchStatus 0 "notrequest " 1 "OFF " 2 "ON " 3 "invalid " ;
VAL_ 905 BCM_RearFoglampSwitchStatus 0 "notrequest " 1 "requst " 2 "reserved " 3 "invalid " ;
VAL_ 905 BCM_PositionLampSwitchStatus 0 "notrequest " 1 "OFF " 2 "ON " 3 "invalid " ;
VAL_ 905 BCM_RearWiperSwitchStatus 0 "notrequest " 1 "OFF " 2 "ON " 3 "invalid " ;
VAL_ 903 BCM_RainOpenLightRequest 0 "Norequest " 1 "开雾灯 " 2 "开双闪 " 3 "开雾灯和双闪 " ;
VAL_ 903 BCM_VoiceWelcometSts 0 "Inactive " 1 "Off " 2 "On " 3 "Reserved " ;
VAL_ 903 BCM_SaveEnergySetStatus 0 "inactive " 1 "10min " 2 "5min " 3 "2min " ;
VAL_ 903 BCM_RearWiperStatus 0 "OFF " 1 "ON " ;
VAL_ 903 BCM_SystemFailureFlag 0 "NoError " 1 "Error " ;
VAL_ 903 BCM_Statuslowbeam 0 "NOerror " 1 "Error " ;
VAL_ 903 BCM_Statusrainsensor 0 "NOerror " 1 "Error " ;
VAL_ 903 BCM_AmbientLightStatus 0 "Day " 1 "Night " ;
VAL_ 903 BCM_FrontWiperStatus 0 "OFF " 1 "Low " 2 "High " 3 "Error " ;
VAL_ 903 BCM_FrontWashStatus 0 "OFF " 1 "ON " 2 "Notused " 3 "Error " ;
VAL_ 903 BCM_RainfallLevel 0 "Norain " 1 "Level1 " 2 "Level2 " 3 "Level3 " 4 "Level4 " 5 "Level5 " 6 "Level6 " 7 "Level7 " 8 "Level8 " 9 "Level9 " 10 "Level10 " 11 "Level11 " 12 "Level12 " 13 "level13 " 14 "initvalue " 15 "Invalidvalue " ;
VAL_ 903 BCM_DrivingModeMemoryStatus 0 "Inactive " 1 "yes " 2 "no " 3 "Reserved " ;
VAL_ 903 BCM__BLEKeyIndicator 0 "inactive " 1 "无蓝牙启动权限 " 2 "蓝牙钥匙连接断开 " 3 "Reserved " ;
VAL_ 903 BCM_DriveModeFeedback 0 "normal " 1 "eco " 2 "sport " 3 "Reserved " ;
VAL_ 902 BCM_RRPressureSensorLowPower 0 "Normal " 1 "LowPower " ;
VAL_ 902 BCM_LRPressureSensorLowPower 0 "Normal " 1 "LowPower " ;
VAL_ 902 BCM_RFPressureSensorLowPower 0 "Normal " 1 "LowPower " ;
VAL_ 902 BCM_LFPressureSensorLowPower 0 "Normal " 1 "LowPower " ;
VAL_ 902 BCM_RRPressureNotLearn 0 "learn " 1 "Notlearn " ;
VAL_ 902 BCM_LRPressureNotLearn 0 "learn " 1 "Notlearn " ;
VAL_ 902 BCM_RFPressureNotLearn 0 "learn " 1 "Notlearn " ;
VAL_ 902 BCM_LFPressureNotLearn 0 "learn " 1 "Notlearn " ;
VAL_ 902 BCM_RRPressureSensorDiagnosis 0 "Normal " 1 "Abnormal " 2 "Reserved " 3 "Invalid " ;
VAL_ 902 BCM_LRPressureSensorDiagnosis 0 "Normal " 1 "Abnormal " 2 "Reserved " 3 "Invalid " ;
VAL_ 902 BCM_RFPressureSensorDiagnosis 0 "Normal " 1 "Abnormal " 2 "Reserved " 3 "Invalid " ;
VAL_ 902 BCM_LFPressureSensorDiagnosis 0 "Normal " 1 "Abnormal " 2 "Reserved " 3 "Invalid " ;
VAL_ 902 BCM_RLS_NotInstalled 0 "Normal " 1 "Abnormal " 2 "Reserved " 3 "Invalid " ;
VAL_ 902 BCM_TurnIndicatorRightRearDiagnosis 0 "Normal " 1 "Abnormal " 2 "Reserved " 3 "Invalid " ;
VAL_ 902 BCM_TurnIndicatorLeftRearDiagnosis 0 "Normal " 1 "Abnormal " 2 "Reserved " 3 "Invalid " ;
VAL_ 902 BCM_TurnIndicatorRightFrontDiagnosis 0 "Normal " 1 "Abnormal " 2 "Reserved " 3 "Invalid " ;
VAL_ 902 BCM_TurnIndicatorLeftFrontDiagnosis 0 "Normal " 1 "Abnormal " 2 "Reserved " 3 "Invalid " ;
VAL_ 902 BCM_PositionLampDiagnosis 0 "Normal " 1 "Abnormal " 2 "Reserved " 3 "Invalid " ;
VAL_ 902 BCM_BrakeLightDiagnosis 0 "Normal " 1 "Abnormal " 2 "Reserved " 3 "Invalid " ;
VAL_ 902 BCM_RightHighBeamDiagnosis 0 "Normal " 1 "Abnormal " 2 "Reserved " 3 "Invalid " ;
VAL_ 902 BCM_LeftHighBeamDiagnosis 0 "Normal " 1 "Abnormal " 2 "Reserved " 3 "Invalid " ;
VAL_ 902 BCM_RightLowBeamDiagnosis 0 "Normal " 1 "Abnormal " 2 "Reserved " 3 "Invalid " ;
VAL_ 902 BCM_LeftLowBeamDiagnosis 0 "Normal " 1 "Abnormal " 2 "Reserved " 3 "Invalid " ;
VAL_ 902 BCM_RearFoglampDiagnosis 0 "Normal " 1 "Abnormal " 2 "Reserved " 3 "Invalid " ;
VAL_ 902 BCM_TrunkLowFrequencyAntennaDiagnosis 0 "Normal " 1 "Abnormal " 2 "Reserved " 3 "Invalid " ;
VAL_ 902 BCM_MiddleCarLowFrequencyAntennaDiagnosis 0 "Normal " 1 "Abnormal " 2 "Reserved " 3 "Invalid " ;
VAL_ 902 BCM_FrontCarLowFrequencyAntennaDiagnosis 0 "Normal " 1 "Abnormal " 2 "Reserved " 3 "Invalid " ;
VAL_ 902 BCM_RightLowFrequencyAntennaDiagnosis 0 "Normal " 1 "Abnormal " 2 "Reserved " 3 "Invalid " ;
VAL_ 902 BCM_LeftLowFrequencyAntennaDiagnosis 0 "Normal " 1 "Abnormal " 2 "Reserved " 3 "Invalid " ;
VAL_ 889 Sunshade_APActive 0 "Inactive " 1 "Active " ;
VAL_ 889 Sunshade_Status 0 "stopped " 1 "windowclose " 2 "windowopen " 3 "Invalid " ;
VAL_ 889 Sunshade_Initialized 0 "Deinitialized " 1 "initialized " ;
VAL_ 889 Sunshade_RelayError 0 "NoError " 1 "Error " ;
VAL_ 889 Sunshade_UnderVoltage 0 "NoError " 1 "Error " ;
VAL_ 889 Sunshade_OverVoltage 0 "NoError " 1 "Error " ;
VAL_ 889 Sunshade_ThermalProtection 0 "NoError " 1 "Error " ;
VAL_ 889 Sunshade_HallError 0 "NoError " 1 "Error " ;
VAL_ 889 Sunshade_ECUError 0 "NoError " 1 "Error " ;
VAL_ 889 Sunshade_Switch 0 "inactive " 1 "openswitchpressed " 2 "closeswitchpressed " ;
VAL_ 889 Sunshade_SwitchError 0 "NoError " 1 "Error " ;
VAL_ 890 Sunroof_RelayError 0 "NoError " 1 "Error " ;
VAL_ 890 Sunroof_UnderVoltage 0 "NoError " 1 "Error " ;
VAL_ 890 Sunroof_OverVoltage 0 "NoError " 1 "Error " ;
VAL_ 890 Sunroof_TeachRun 0 "Inactive " 1 "Active " ;
VAL_ 890 Sunroof_ThermalProtection 0 "NoError " 1 "Error " ;
VAL_ 890 Sunroof_POS_Direction 0 "horizontal " 1 "vertical " ;
VAL_ 890 Sunroof_HallError 0 "NoError " 1 "Error " ;
VAL_ 890 Sunroof_SwitchError 0 "NoError " 1 "Error " ;
VAL_ 890 BDCR_ECUError 0 "NoError " 1 "Error " ;
VAL_ 890 Sunroof_APActive 0 "Inactive " 1 "Active " ;
VAL_ 890 Sunroof_Status 0 "stopped " 1 "windowclose " 2 "windowopen " 3 "Invalid " ;
VAL_ 890 Sunroof_Initialized 0 "Deinitialized " 1 "initialized " ;
VAL_ 881 RLS_Communication_error 0 "LINcommunicationNormal " 1 "LINcommunicationError " ;
VAL_ 881 RainfallLevel 0 "NoRain " 1 "Level1 " 2 "Level2 " 3 "Level3 " 4 "Level4 " 5 "Level5 " 6 "Level6 " 7 "Level7 " 8 "Level8 " 9 "Level9 " 16 "Level10 " 17 "Level11 " 18 "Level12 " 19 "Level13 " 20 "initvalue " 21 "Invalidvalue " ;
VAL_ 881 RLS_Error_status_over_voltage 0 "VoltageNormal " 1 "Overvoltage " ;
VAL_ 881 RLS_Error_status_light_sensor 0 "LightSensorNormal " 1 "LightSensorError " ;
VAL_ 881 RLS_Error_status_coding_rain_sensor 0 "LightTransimissionValid " 1 "LightTransimissionOutOfRange " ;
VAL_ 881 RLS_Error_status_rain_sensor 0 "RainSensorNormal " 1 "RainSensorError " ;
VAL_ 881 RLS_RLS_error 0 "RLSNormal " 1 "RLSError " ;
VAL_ 881 RLS_Status_low_beam 0 "正常 " 1 "光传感器故障 " ;
VAL_ 881 RLS_Light_switch_request 0 "Switchlightoff " 1 "Switchlighton " ;
VAL_ 881 RLS_Light_switch_reason 0 "00000000Day0x0 " 1 "00000001Twilight0x1 " 2 "00000010Darkness0x2 " 4 "00000100Precipitation0x4 " 8 "00001000Tunnel0x8 " 16 "000010000UndergroundcarparkExitfromtunnel/undergroundcarpark0x10 " 32 "00100000Highspeed0x20 " 255 "11111111Signalinvalid0xFF " ;
VAL_ 881 RLS_Status_rain_sensor 0 "正常 " 4 "雨量传感器内部故障 " ;
VAL_ 881 RLS_Wiper_speed 0 "雨刮不刮 " 1 "间歇刮/低速连续 " 3 "高速连续 " ;
VAL_ 1667 TPMS__SensorFailure_Alarm 1 "故障 " ;
VAL_ 1667 TPMS_BatteryLevel_Alarm 0 "电池电量正常 " 1 "电池电量低 " ;
VAL_ 1667 TPMS_Hightemperature_Alarm 1 "高温报警 " ;
VAL_ 1667 TPMS_Airleakage_Alarm 0 "正常 " 1 "漏气报警 " ;
VAL_ 1310 BCM_AerateFlag 0 "invalid " 1 "active " ;
VAL_ 1310 BCM_LRLeakageWarning 0 "Noanytire " 1 "LeftReartirequikleakage " 2 "LeftReartirequikleakage " 3 "Reserved " ;
VAL_ 1310 BCM_RRLeakageWarning 0 "Noanytire " 1 "RightReartirequikleakage " 2 "RightReartireslowleakage " ;
VAL_ 1310 BCM_RFLeakageWarning 0 "Noanytire " 1 "RightFronttirequikleakage " 2 "RightFronttireslowleakage " 3 "Reserved " ;
VAL_ 1310 BCM_LFLeakageWarning 0 "Noanytire " 1 "LeftFronttirequikleakage " 2 "LeftFronttireslowleakage " 3 "Reserved " ;
VAL_ 1310 BCM_LRTemperatureWarning 0 "Notemperaturewarning " 1 "Temperaturewarning " ;
VAL_ 1310 BCM_RRTemperatureWarning 0 "Notemperaturewarning " 1 "Temperaturewarning " ;
VAL_ 1310 BCM_RFTemperatureWarning 0 "Notemperaturewarning " 1 "Temperaturewarning " ;
VAL_ 1310 BCM_LFTemperatureWarning 0 "Notemperaturewarning " 1 "Temperaturewarning " ;
VAL_ 839 BCM_SystemFailureWarning 0 "Noanyerror " 1 "Systemerror " ;
VAL_ 839 BCM_LFPressureWarning 0 "Nowarning " 1 "Highpressurewarning " 2 "Lowpressurewarning " 3 "Quikleakage " 4 "LostSensor " 5 "Sensorbatterylow " 6 "Sensorfailure " 7 "Reserved " ;
VAL_ 839 BCM_RRPressureWarning 0 "Nowarning " 1 "Highpressurewarning " 2 "Lowpressurewarning " 3 "Quikleakage " 4 "LostSensor " 5 "Sensorbatterylow " 6 "Sensorfailure " 7 "Reserved " ;
VAL_ 839 BCM_LRPressureWarning 0 "Nowarning " 1 "Highpressurewarning " 2 "Lowpressurewarning " 3 "Quikleakage " 4 "LostSensor " 5 "Sensorbatterylow " 6 "Sensorfailure " 7 "Reserved " ;
VAL_ 839 BCM_RFPressureWarning 0 "Nowarning " 1 "Highpressurewarning " 2 "Lowpressurewarning " 3 "Quikleakage " 4 "LostSensor " 5 "Sensorbatterylow " 6 "Sensorfailure " 7 "Reserved " ;
VAL_ 839 BCM_TirePresureSignalStatus 0 "reliablesignal " 1 "unreliablesignal " ;
VAL_ 839 BCM_SignalStatus 0 "CurrentSignal " 1 "LastSignal " ;
VAL_ 664 BCM_WindowElectricInspectionSign 0 "车窗防夹已学习 " 1 "车窗防夹未学习 " ;
VAL_ 664 BCM_LeftRearDoorStatus 0 "Close " 1 "Open " ;
VAL_ 664 BCM_PassengerDoorLockStatus 0 "Lock " 1 "Unlock " 2 "Notused " 3 "Error " ;
VAL_ 664 BCM_DriverDoorLockStatus 0 "Lock " 1 "Unlock " 2 "Notused " 3 "Error " ;
VAL_ 664 BCM_PassengerDoorStatus 0 "Close " 1 "Open " ;
VAL_ 664 PEPS_UnLockKeyStatus 0 "notpressed " 1 "pressed " 2 "notused " 3 "notusede " ;
VAL_ 664 PEPS_TrunkKeyStatus 0 "notpressed " 1 "pressed " 2 "notused " 3 "notused " ;
VAL_ 664 BCM_BreathingLightSet_FeedBack 0 "Inactive " 1 "On " 2 "Off " 3 "Reserve " ;
VAL_ 664 BCM_RightRearDoorStatus 0 "Close " 1 "Open " ;
VAL_ 664 BCM_TrunkStatus 0 "Close " 1 "Open " ;
VAL_ 664 PEPS_LockKeyStatus 0 "notpressed " 1 "pressed " 2 "notused " 3 "notused " ;
VAL_ 664 PEPS_SmartLockSignal 0 "Inactive " 1 "离开闭锁 " ;
VAL_ 664 PEPS_SmartUnlockSignal 0 "Inactive " 1 "靠近解锁 " ;
VAL_ 664 PEPS_LockSignal 0 "Inactive " 1 "遥控闭锁 " 2 "左前PE闭锁 " 3 "右前PE闭锁 " ;
VAL_ 664 PEPS_WLCM_Enable 0 "Inactive（默认WLCM可充电） " 1 "Enable（使能WLCM充电） " 2 "Forbid（禁止WLCM充电） " 3 "Reserved " ;
VAL_ 664 PEPS_UnlockSignal 0 "Inactive " 1 "遥控解锁 " 2 "左前PE解锁 " 3 "右前PE解锁 " ;
VAL_ 664 PEPS_SmartTrunkUlockRemind 0 "Inactive " 1 "SlowFlash " 2 "FastFlash " 3 "Reserved " ;
VAL_ 664 PEPS_Welcomelamp 0 "Inactive " 1 "OFF " 2 "ON " 3 "Reserved " ;
VAL_ 664 PEPS_Easy_open 0 "nocommand " 1 "自动感应信号 " ;
VAL_ 664 PEPS_KeyAuthenticationStatus 0 "Inactive非认证状态 " 1 "start认证中 " 2 "Success成功 " 3 "failed失败 " ;
VAL_ 664 PEPS_LuggageUnlockSignal 0 "Inactive " 1 "遥控行李箱解锁 " 2 "PE行李箱解锁 " 3 "语音控制行李箱解锁 " ;
VAL_ 664 PEPS_SearchCarSignal 0 "Inactive " 1 "ON " ;
VAL_ 664 PEPS_RemoteFailedAlarmSignal 0 "Inactive " 1 "钥匙认证失败 " ;
VAL_ 664 PEPS_EasyOpenOrginalSignal 0 "脚步传感器未触发 " 1 "脚步传感器触发 " ;
VAL_ 664 PEPS_KeyLearningSignal 0 "Inactive非学习状态 " 1 "Start学习中 " 2 "Success成功 " 3 "Failed失败 " ;
VAL_ 664 PEPS_TrunkRequestSignal 0 "OFF " 1 "行李箱按钮被按下 " ;
